VERSION ""

NS_ :

BS_:

BU_: TCM MRGB SGCP ECM MCPB MCPA EVCU2 AGSM

BO_ 271 ENGINE_HYBD_FD_1: 64 ECM
 SG_ Sum_FW_ID_Slw : 327|5@0+ (1,0) [0|30] "-"  EVCU2
 SG_ Sum_FW_ID_Fst : 367|5@0+ (1,0) [0|30] "-"  EVCU2
 SG_ MinPrdtdEngRunTorqCapV : 213|1@0+ (1,0) [0|0] "-"  EVCU2
 SG_ MinPrdtdEngRunTorqCap : 243|12@0+ (0.32,-300.16) [-300.16|1008] "Nm"  EVCU2
 SG_ MinImmedEngTorqCapV : 215|1@0+ (1,0) [0|0] "-"  EVCU2,TCM
 SG_ MinImmedEngTorqCap : 227|12@0+ (0.32,-300.16) [-300.16|1008] "Nm"  EVCU2,TCM
 SG_ MinEngTorqCapV : 196|1@0+ (1,0) [0|0] "-"  EVCU2
 SG_ MinEngTorqCap : 211|12@0+ (0.32,-300.16) [-300.16|1008] "Nm"  EVCU2
 SG_ MinAirFlowMinSparkTorqCapV : 197|1@0+ (1,0) [0|0] "-"  EVCU2,TCM
 SG_ MinAirFlowMinSparkTorqCap : 195|12@0+ (0.32,-300.16) [-300.16|1008] "Nm"  EVCU2,TCM
 SG_ MessageCounter_ENGINE_HYBD_FD_1 : 435|4@0+ (1,0) [0|15] "-"  EVCU2,TCM
 SG_ MaxPrdtdEngTorqCapV : 198|1@0+ (1,0) [0|0] "-"  EVCU2,TCM
 SG_ MaxPrdtdEngTorqCap : 179|12@0+ (0.32,-300.16) [-300.16|1008] "Nm"  EVCU2,TCM
 SG_ MaxOffEngTorqCap : 163|12@0+ (0.32,-300.16) [-300.16|1008] "Nm"  EVCU2
 SG_ HybActEngTorqRespTyp : 149|2@0+ (1,0) [0|0] "-"  EVCU2
 SG_ Feedback_HCP : 293|1@0+ (1,0) [0|0] "-"  EVCU2
 SG_ ETRQ_Mode : 362|3@0+ (1,0) [0|5] "-"  EVCU2
 SG_ EngTrqReserveReq : 351|8@0+ (0.32,0) [0|81.28] "Nm"  EVCU2
 SG_ EngRunCrnkAct : 295|1@0+ (1,0) [0|0] "-"  EVCU2
 SG_ EngAirFlwStdyStTorqV : 262|1@0+ (1,0) [0|0] "-"  EVCU2,TCM
 SG_ EngAirFlwStdyStTorq : 275|12@0+ (0.32,-300.16) [-300.16|1008] "Nm"  EVCU2,TCM
 SG_ EngActuatorsStat : 133|2@0+ (1,0) [0|0] "-"  EVCU2
 SG_ EngActStdyStTorqV : 263|1@0+ (1,0) [0|0] "-"  EVCU2
 SG_ EngActStdyStTorq : 259|12@0+ (0.32,-300.16) [-300.16|1008] "Nm"  EVCU2
 SG_ CRC_ENGINE_HYBD_FD_1 : 447|8@0+ (1,0) [0|255] "-"  EVCU2,TCM
 SG_ MAP_4_BAR_PHEV : 392|9@0+ (0.8,0) [0|408] "kPa"  EVCU2
 SG_ RedSpkAuthorityAvbl : 308|1@0+ (1,0) [0|1] "" EVCU2
 SG_ EngMinSparkNomCurrAirTorqCap : 82|11@0+ (1,-500) [-500|1547] "Nm"  EVCU2
 SG_ EngTrqFSO_CurrAir : 391|12@0+ (0.32,-300.16) [-300.16|1008] "Nm"  TCM
 SG_ GasFlwEnblsFuAtStr : 212|1@0+ (1,0) [0|1] "" EVCU2

BO_ 262 ENGINE_FD_2: 64 ECM
 SG_ TxAC_EMCC_rq_W : 189|1@0+ (1,0) [0|1] "-"  TCM
 SG_ TRANS_CLU_SLIP_MODE_W : 71|3@0+ (1,0) [0|7] "-"  TCM
 SG_ MessageCounter_ENGINE2 : 435|4@0+ (1,0) [0|15] "-"  EVCU2,TCM
 SG_ LV12PwrFreeRq_W : 176|1@0+ (1,0) [0|1] "-"  EVCU2,TCM
 SG_ KickDownRequest_W : 182|1@0+ (1,0) [0|1] "-"  TCM
 SG_ IntakeAirTemperature_W : 151|8@0+ (1,-40) [-40|214] "C"  TCM
 SG_ GasPedalPositionFailSts_W : 169|1@0+ (1,0) [0|1] "-"  TCM
 SG_ GasPedalPosition_W : 143|8@0+ (0.392,0) [0|99.568] "%"  TCM
 SG_ ESS_RqShftPark_W : 115|1@0+ (1,0) [0|0] "-"  Vector__XXX
 SG_ ESS_ENG_ST_W : 175|4@0+ (1,0) [0|15] "-"  TCM
 SG_ EngTrq_Enbl_Rq_TCM_W : 178|1@0+ (1,0) [0|1] "-"  EVCU2,TCM
 SG_ EngineSts_W : 87|2@0+ (1,0) [0|3] "-"  EVCU2,TCM
 SG_ EngineSpeedFailSts_W : 168|1@0+ (1,0) [0|1] "-"  SGCP,MCPB,MCPA
 SG_ EngineSpeed_W : 21|14@0+ (1,0) [0|16382] "1/min"  SGCP,EVCU2,MCPB,MCPA,TCM
 SG_ EngineIdleRefSpeed : 35|12@0+ (1,0) [0|4094] "1/min"  EVCU2,TCM
 SG_ EngineFrictionTorque_W : 112|9@0+ (1,0) [0|510] "Nm"  EVCU2
 SG_ ECM_LHOM_W : 188|1@0+ (1,0) [0|1] "-"  EVCU2,TCM
 SG_ ECM_LHOM_Trans_W : 117|2@0+ (1,0) [0|3] "-"  EVCU2,TCM
 SG_ CRC_ENGINE2 : 447|8@0+ (1,0) [0|255] "-"  EVCU2,TCM
 SG_ CrankHold_W : 179|1@0+ (1,0) [0|1] "-"  Vector__XXX
 SG_ ESS_EBOOST_BRKHLD_STATUS : 279|3@0+ (1,0) [0|6] "-"  Vector__XXX
 SG_ Engine_Stall_Detected : 197|1@0+ (1,0) [0|1] "-"  EVCU2
 SG_ EssEngStrtIsNotAllwdID : 68|3@0+ (1,0) [0|7] "" EVCU2
 SG_ EssEngStrtIsNotAllwd : 37|1@0+ (1,0) [0|1] "" EVCU2
 SG_ EssEngStopIsNotAllwdID : 59|4@0+ (1,0) [0|15] "" EVCU2
 SG_ EssEngStopIsNotAllwd : 255|1@0+ (1,0) [0|1] "" EVCU2
 SG_ EssEngSt : 202|3@0+ (1,0) [0|7] "" EVCU2
 SG_ EssEngModReq : 254|3@0+ (1,0) [0|7] "" EVCU2
 SG_ CompressionTest : 36|1@0+ (1,0) [0|1] "" EVCU2
 SG_ MinEngPowerReqForOilDil : 111|8@0+ (0.2,0) [0|51] "kw"  EVCU2
 SG_ MinEngPowerReqForOilDilEnabler : 96|1@0+ (1,0) [0|1] "" EVCU2
 SG_ Torque_Interface_Mask : 79|6@0+ (1,0) [0|63] "" TCM

BO_ 258 BRAKE_FD_2: 64 EVCU2
 SG_ MessageCounter_BRAKE2 : 435|4@0+ (1,0) [0|15] "-"  MCPB,MCPA
 SG_ LongAccelerationFailSts_BSM : 69|1@0+ (1,0) [0|1] "-"  MCPB,MCPA
 SG_ LongAcceleration_BSM : 35|12@0+ (0.02,-40.96) [-40.96|40.92] "m/s^2"  MCPB,MCPA
 SG_ LatAccelerationFailSts_BSM : 68|1@0+ (1,0) [0|1] "-"  MCPB,MCPA
 SG_ LatAcceleration_BSM : 19|12@0+ (0.02,-40.96) [-40.96|40.92] "m/s^2"  MCPB,MCPA
 SG_ ESCActive : 84|1@0+ (1,0) [0|1] "-"  MCPB,MCPA
 SG_ CRC_BRAKE2 : 447|8@0+ (1,0) [0|255] "-"  MCPB,MCPA
 SG_ ABSActive : 83|1@0+ (1,0) [0|1] "-"  MCPB,MCPA

BO_ 476 AGSM_FD_2: 32 AGSM
 SG_ ShiftLockFailSts : 91|1@0+ (1,0) [0|1] "-"  TCM
 SG_ PRNDFailSts : 82|1@0+ (1,0) [0|1] "-"  EVCU2,TCM
 SG_ PRNDdisplayFailSts : 83|1@0+ (1,0) [0|1] "-"  EVCU2,TCM
 SG_ MessageCounter_AGSM2 : 179|4@0+ (1,0) [0|15] "-"  EVCU2,TCM
 SG_ CRC_AGSM2 : 191|8@0+ (1,0) [0|255] "-"  EVCU2,TCM
 SG_ APCM_Stat : 107|2@0+ (1,0) [0|2] "-"  EVCU2
 SG_ ShiftLever_PositionFlt : 104|1@0+ (1,0) [0|1] "-"  TCM
 SG_ Low_Mode_Req : 5|1@0+ (1,0) [0|1] "-"  TCM
 SG_ ShiftLeverPositionReq : 95|4@0+ (1,0) [0|15] "-"  EVCU2,MCPB,TCM

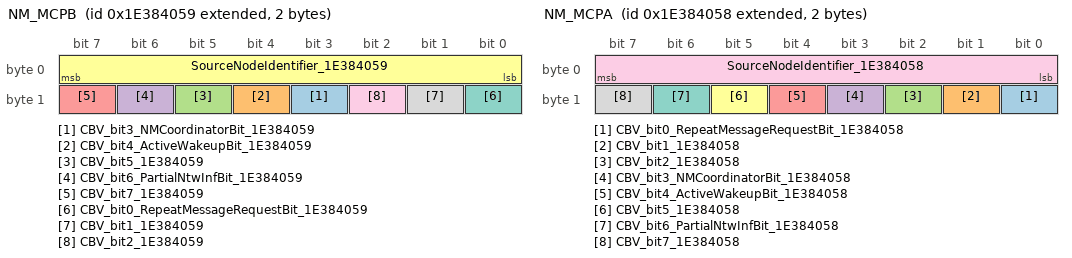
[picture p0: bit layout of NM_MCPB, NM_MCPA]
BO_ 2654486617 NM_MCPB: 2 MCPB
 SG_ CBV_bit3_NMCoordinatorBit_1E384059 : 11|1@0+ (1,0) [0|1] "" SGCP,EVCU2,MCPA,AGSM
 SG_ CBV_bit4_ActiveWakeupBit_1E384059 : 12|1@0+ (1,0) [0|1] "" SGCP,EVCU2,MCPA,AGSM
 SG_ CBV_bit5_1E384059 : 13|1@0+ (1,0) [0|1] "" SGCP,EVCU2,MCPA,AGSM
 SG_ CBV_bit6_PartialNtwInfBit_1E384059 : 14|1@0+ (1,0) [0|1] "" SGCP,EVCU2,MCPA,AGSM
 SG_ CBV_bit7_1E384059 : 15|1@0+ (1,0) [0|1] "" SGCP,EVCU2,MCPA,AGSM
 SG_ SourceNodeIdentifier_1E384059 : 7|8@0+ (1,0) [0|255] "-"  SGCP,EVCU2,MCPA,AGSM
 SG_ CBV_bit0_RepeatMessageRequestBit_1E384059 : 8|1@0+ (1,0) [0|1] "" SGCP,EVCU2,MCPA,AGSM
 SG_ CBV_bit1_1E384059 : 9|1@0+ (1,0) [0|1] "" SGCP,EVCU2,MCPA,AGSM
 SG_ CBV_bit2_1E384059 : 10|1@0+ (1,0) [0|1] "" SGCP,EVCU2,MCPA,AGSM

BO_ 2654486616 NM_MCPA: 2 MCPA
 SG_ CBV_bit0_RepeatMessageRequestBit_1E384058 : 8|1@0+ (1,0) [0|1] "" SGCP,EVCU2,MCPB,AGSM
 SG_ CBV_bit1_1E384058 : 9|1@0+ (1,0) [0|1] "" SGCP,EVCU2,MCPB,AGSM
 SG_ CBV_bit2_1E384058 : 10|1@0+ (1,0) [0|1] "" SGCP,EVCU2,MCPB,AGSM
 SG_ CBV_bit3_NMCoordinatorBit_1E384058 : 11|1@0+ (1,0) [0|1] "" SGCP,EVCU2,MCPB,AGSM
 SG_ CBV_bit4_ActiveWakeupBit_1E384058 : 12|1@0+ (1,0) [0|1] "" SGCP,EVCU2,MCPB,AGSM
 SG_ CBV_bit5_1E384058 : 13|1@0+ (1,0) [0|1] "" SGCP,EVCU2,MCPB,AGSM
 SG_ CBV_bit6_PartialNtwInfBit_1E384058 : 14|1@0+ (1,0) [0|1] "" SGCP,EVCU2,MCPB,AGSM
 SG_ CBV_bit7_1E384058 : 15|1@0+ (1,0) [0|1] "" SGCP,EVCU2,MCPB,AGSM
 SG_ SourceNodeIdentifier_1E384058 : 7|8@0+ (1,0) [0|255] "-"  SGCP,EVCU2,MCPB,AGSM

BO_ 2564682261 DIAGNOSTIC_ROE_FD_MCPB: 64 MCPB
 SG_ N_PDU_18DDF215 : 7|64@0+ (1,0) [0|0] "" EVCU2

BO_ 2564682260 DIAGNOSTIC_ROE_FD_MCPA: 64 MCPA
 SG_ N_PDU_18DDF214 : 7|64@0+ (1,0) [0|0] "" EVCU2

BO_ 2564485396 DIAGNOSTIC_RESPONSE_MCPA: 8 MCPA
 SG_ N_PDU_18DAF114 : 7|64@0+ (1,0) [0|0] "" EVCU2

BO_ 2564485653 DIAGNOSTIC_RESPONSE_FD_MCPB: 64 MCPB
 SG_ N_PDU_18DAF215 : 7|64@0+ (1,0) [0|0] "" EVCU2

BO_ 2564485652 DIAGNOSTIC_RESPONSE_FD_MCPA: 64 MCPA
 SG_ N_PDU_18DAF214 : 7|64@0+ (1,0) [0|0] "" EVCU2

BO_ 2564429297 DIAGNOSTIC_REQUEST_MCPB: 8 EVCU2
 SG_ N_PDU_18DA15F1 : 7|64@0+ (1,0) [0|0] "" MCPB

BO_ 2564429298 DIAGNOSTIC_REQUEST_FD_MCPB: 64 EVCU2
 SG_ N_PDU_18DA15F2 : 7|64@0+ (1,0) [0|0] "" MCPB

BO_ 2564429042 DIAGNOSTIC_REQUEST_FD_MCPA: 64 EVCU2
 SG_ N_PDU_18DA14F2 : 7|64@0+ (1,0) [0|0] "" MCPA

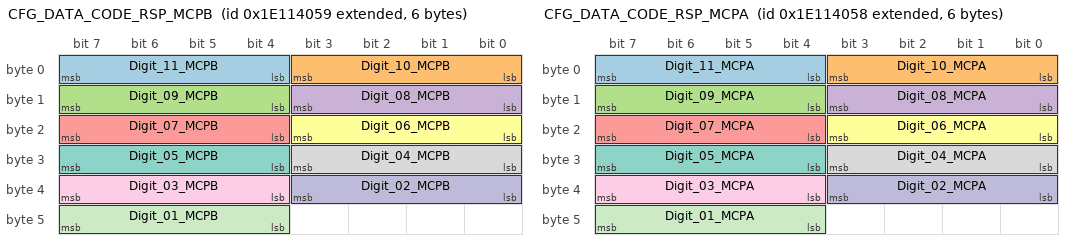
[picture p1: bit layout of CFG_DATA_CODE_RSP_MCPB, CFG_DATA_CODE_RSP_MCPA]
BO_ 2651930713 CFG_DATA_CODE_RSP_MCPB: 6 MCPB
 SG_ Digit_11_MCPB : 7|4@0+ (1,0) [0|15] "-"  EVCU2
 SG_ Digit_10_MCPB : 3|4@0+ (1,0) [0|15] "-"  EVCU2
 SG_ Digit_09_MCPB : 15|4@0+ (1,0) [0|15] "-"  EVCU2
 SG_ Digit_08_MCPB : 11|4@0+ (1,0) [0|15] "-"  EVCU2
 SG_ Digit_07_MCPB : 23|4@0+ (1,0) [0|15] "-"  EVCU2
 SG_ Digit_06_MCPB : 19|4@0+ (1,0) [0|15] "-"  EVCU2
 SG_ Digit_05_MCPB : 31|4@0+ (1,0) [0|15] "-"  EVCU2
 SG_ Digit_04_MCPB : 27|4@0+ (1,0) [0|15] "-"  EVCU2
 SG_ Digit_03_MCPB : 39|4@0+ (1,0) [0|15] "-"  EVCU2
 SG_ Digit_02_MCPB : 35|4@0+ (1,0) [0|15] "-"  EVCU2
 SG_ Digit_01_MCPB : 47|4@0+ (1,0) [0|15] "-"  EVCU2

BO_ 2651930712 CFG_DATA_CODE_RSP_MCPA: 6 MCPA
 SG_ Digit_11_MCPA : 7|4@0+ (1,0) [0|15] "-"  EVCU2
 SG_ Digit_10_MCPA : 3|4@0+ (1,0) [0|15] "-"  EVCU2
 SG_ Digit_09_MCPA : 15|4@0+ (1,0) [0|15] "-"  EVCU2
 SG_ Digit_08_MCPA : 11|4@0+ (1,0) [0|15] "-"  EVCU2
 SG_ Digit_07_MCPA : 23|4@0+ (1,0) [0|15] "-"  EVCU2
 SG_ Digit_06_MCPA : 19|4@0+ (1,0) [0|15] "-"  EVCU2
 SG_ Digit_05_MCPA : 31|4@0+ (1,0) [0|15] "-"  EVCU2
 SG_ Digit_04_MCPA : 27|4@0+ (1,0) [0|15] "-"  EVCU2
 SG_ Digit_03_MCPA : 39|4@0+ (1,0) [0|15] "-"  EVCU2
 SG_ Digit_02_MCPA : 35|4@0+ (1,0) [0|15] "-"  EVCU2
 SG_ Digit_01_MCPA : 47|4@0+ (1,0) [0|15] "-"  EVCU2

BO_ 496 PARK_DATA: 24 MCPB
 SG_ MessageCounter_PARK_DATA : 115|4@0+ (1,0) [0|15] "" EVCU2
 SG_ CRC_PARK_DATA : 127|8@0+ (1,0) [0|255] "" EVCU2
 SG_ Plock_fdbk_sts : 7|3@0+ (1,0) [0|7] "" Vector__XXX

BO_ 105 VDCM_PWT3: 64 EVCU2
 SG_ T7_Sensor_Temp : 330|11@0+ (0.1,-40) [-40|164.7] "°C"  SGCP,MCPB,MCPA
 SG_ T7_CoolantTempVldty : 331|1@0+ (1,0) [0|1] "" SGCP,MCPB,MCPA
 SG_ T4_Sensor_Temp : 378|11@0+ (0.1,-40) [-40|164.7] "°C"  SGCP,MCPB,MCPA

BO_ 2654339273 PDC_INFO_FD_SGCP: 32 SGCP
 SG_ GenericFailSts_FD16_SGCP : 180|1@0+ (1,0) [0|1] "" EVCU2
 SG_ EOL_FD16_SGCP : 2|1@0+ (1,0) [0|1] "-"  EVCU2
 SG_ CurrentFailSts_FD16_SGCP : 181|1@0+ (1,0) [0|1] "" EVCU2

BO_ 2654339161 PDC_INFO_FD_MCPB: 32 MCPB
 SG_ EOL_FD16_MCPB : 2|1@0+ (1,0) [0|1] "-"  EVCU2
 SG_ GenericFailSts_FD16_MCPB : 172|1@0+ (1,0) [0|1] "" EVCU2
 SG_ CurrentFailSts_FD16_MCPB : 173|1@0+ (1,0) [0|1] "" EVCU2

BO_ 2654339160 PDC_INFO_FD_MCPA: 32 MCPA
 SG_ EOL_FD16_MCPA : 2|1@0+ (1,0) [0|1] "-"  EVCU2
 SG_ GenericFailSts_FD16_MCPA : 172|1@0+ (1,0) [0|1] "" EVCU2
 SG_ CurrentFailSts_FD16_MCPA : 173|1@0+ (1,0) [0|1] "" EVCU2

BO_ 2564682364 DIAGNOSTIC_ROE_FD_SGCP: 64 SGCP
 SG_ N_PDU_18DDF27C : 7|64@0+ (1,0) [0|0] "" EVCU2

BO_ 2564485756 DIAGNOSTIC_RESPONSE_FD_SGCP: 64 SGCP
 SG_ N_PDU_18DAF27C : 7|64@0+ (1,0) [0|0] "" EVCU2

BO_ 2564455666 DIAGNOSTIC_REQUEST_FD_SGCP: 64 EVCU2
 SG_ N_PDU_18DA7CF2 : 7|64@0+ (1,0) [0|0] "" SGCP

BO_ 263 PT_SYSTEM_FD_1: 64 EVCU2
 SG_ OptimdStrtReqdActr : 2|3@0+ (1,0) [0|7] "" ECM
 SG_ OptimdEngStrtStpType : 7|5@0+ (1,0) [0|31] "" ECM
 SG_ OptimdEngOnOffCmd : 15|1@0+ (1,0) [0|1] "" ECM
 SG_ Hyb_ProducingTorque : 13|1@0+ (1,0) [0|1] "" ECM
 SG_ HCPFuelDisable : 14|1@0+ (1,0) [0|1] "" ECM
 SG_ PowertrainPrplsnActv_PT : 146|1@0+ (1,0) [0|1] "" SGCP,MCPB,MCPA
 SG_ GearEngagedForDisplay_PT : 12|5@0+ (1,0) [0|31] "" AGSM
 SG_ GearEngaged_PT : 132|4@0+ (1,0) [0|15] "" MCPB
 SG_ TransmissionFailSts_PT : 152|1@0+ (1,0) [0|1] "" AGSM
 SG_ TerrainModeStat_PT : 119|5@0+ (1,0) [0|31] "" Vector__XXX
 SG_ ShiftLeverPosition_PT : 51|4@0+ (1,0) [0|15] "" AGSM
 SG_ ShiftLeverLockReq_PT : 155|1@0+ (1,0) [0|1] "" AGSM
 SG_ R_SHFT_LOCK_PT : 154|1@0+ (1,0) [0|1] "" AGSM
 SG_ MessageCounter_PT_SYSTEM_FD_1 : 435|4@0+ (1,0) [0|15] "-"  MCPB,AGSM,ECM
 SG_ GearIndicationSts_PT : 153|1@0+ (1,0) [0|1] "" AGSM
 SG_ GasPedalPositionFailSts_PT : 145|1@0+ (1,0) [0|1] "" ECM
 SG_ GasPedalPosition_PT : 31|8@0+ (0.392,0) [0|99.96] "%"  ECM
 SG_ CRC_PT_SYSTEM_FD_1 : 447|8@0+ (1,0) [0|255] "-"  MCPB,AGSM,ECM
 SG_ APCM_Rq_PT : 137|2@0+ (1,0) [0|3] "" AGSM
 SG_ PropulsionSystemActive_PT : 209|1@0+ (1,0) [0|1] "-"  MRGB
 SG_ Custom_DrvMdSts_PT : 327|5@0+ (1,0) [0|31] "" Vector__XXX
 SG_ WheelSpeedRearRight : 348|13@0+ (0.0625,0) [0|511.9375] "Km/h"  MRGB
 SG_ WheelSpeedRearLeft : 364|13@0+ (0.0625,0) [0|511.9375] "Km/h"  MRGB
 SG_ Transm_Torq_Feedback : 279|1@0+ (1,0) [0|1] "" MRGB
 SG_ Inertia_Torque_Active : 415|1@0+ (1,0) [0|1] "" MRGB
 SG_ Gear_Rq : 351|3@0+ (1,0) [0|7] "" MRGB
 SG_ EM_min_Trqdyn_P : 393|10@0+ (1,-1021) [-1021|2] "Nm"  MRGB
 SG_ EM_max_Trqdyn_P : 391|10@0+ (1,-1021) [-1021|2] "Nm"  MRGB
 SG_ EOPB_Min_Oil_FlwRate_Rq : 431|8@0+ (0.1,0) [0|25.5] "lpm"  MRGB

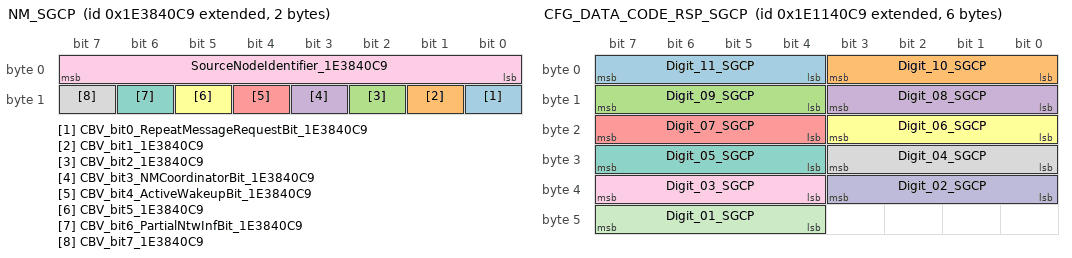
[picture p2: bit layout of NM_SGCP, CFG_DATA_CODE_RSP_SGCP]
BO_ 2654486729 NM_SGCP: 2 SGCP
 SG_ CBV_bit0_RepeatMessageRequestBit_1E3840C9 : 8|1@0+ (1,0) [0|1] "" EVCU2,MCPB,MCPA
 SG_ CBV_bit1_1E3840C9 : 9|1@0+ (1,0) [0|1] "" EVCU2,MCPB,MCPA
 SG_ CBV_bit2_1E3840C9 : 10|1@0+ (1,0) [0|1] "" EVCU2,MCPB,MCPA
 SG_ CBV_bit3_NMCoordinatorBit_1E3840C9 : 11|1@0+ (1,0) [0|1] "" EVCU2,MCPB,MCPA
 SG_ CBV_bit4_ActiveWakeupBit_1E3840C9 : 12|1@0+ (1,0) [0|1] "" EVCU2,MCPB,MCPA
 SG_ CBV_bit5_1E3840C9 : 13|1@0+ (1,0) [0|1] "" EVCU2,MCPB,MCPA
 SG_ CBV_bit6_PartialNtwInfBit_1E3840C9 : 14|1@0+ (1,0) [0|1] "" EVCU2,MCPB,MCPA
 SG_ CBV_bit7_1E3840C9 : 15|1@0+ (1,0) [0|1] "" EVCU2,MCPB,MCPA
 SG_ SourceNodeIdentifier_1E3840C9 : 7|8@0+ (1,0) [0|255] "-"  EVCU2,MCPB,MCPA

BO_ 2651930825 CFG_DATA_CODE_RSP_SGCP: 6 SGCP
 SG_ Digit_11_SGCP : 7|4@0+ (1,0) [0|15] "-"  EVCU2
 SG_ Digit_10_SGCP : 3|4@0+ (1,0) [0|15] "-"  EVCU2
 SG_ Digit_09_SGCP : 15|4@0+ (1,0) [0|15] "-"  EVCU2
 SG_ Digit_08_SGCP : 11|4@0+ (1,0) [0|15] "-"  EVCU2
 SG_ Digit_07_SGCP : 23|4@0+ (1,0) [0|15] "-"  EVCU2
 SG_ Digit_06_SGCP : 19|4@0+ (1,0) [0|15] "-"  EVCU2
 SG_ Digit_05_SGCP : 31|4@0+ (1,0) [0|15] "-"  EVCU2
 SG_ Digit_04_SGCP : 27|4@0+ (1,0) [0|15] "-"  EVCU2
 SG_ Digit_03_SGCP : 39|4@0+ (1,0) [0|15] "-"  EVCU2
 SG_ Digit_02_SGCP : 35|4@0+ (1,0) [0|15] "-"  EVCU2
 SG_ Digit_01_SGCP : 47|4@0+ (1,0) [0|15] "-"  EVCU2

BO_ 216 PT_ENERGY_FD_1: 64 EVCU2
 SG_ BatteryVoltage_Raw_PT : 97|10@0+ (0.2,0) [0|204.60] "V"  MCPB,MCPA

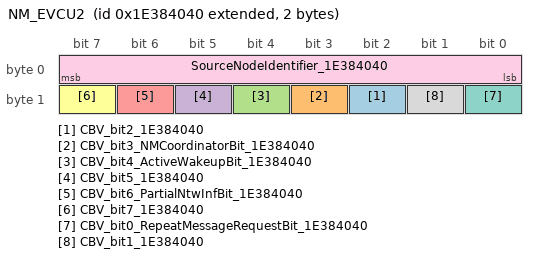
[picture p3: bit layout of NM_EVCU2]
BO_ 2654486592 NM_EVCU2: 2 EVCU2
 SG_ CBV_bit2_1E384040 : 10|1@0+ (1,0) [0|1] "" SGCP,MCPB,MCPA,AGSM
 SG_ CBV_bit3_NMCoordinatorBit_1E384040 : 11|1@0+ (1,0) [0|1] "" SGCP,MCPB,MCPA,AGSM
 SG_ CBV_bit4_ActiveWakeupBit_1E384040 : 12|1@0+ (1,0) [0|1] "" SGCP,MCPB,MCPA,AGSM
 SG_ CBV_bit5_1E384040 : 13|1@0+ (1,0) [0|1] "" SGCP,MCPB,MCPA,AGSM
 SG_ CBV_bit6_PartialNtwInfBit_1E384040 : 14|1@0+ (1,0) [0|1] "" SGCP,MCPB,MCPA,AGSM
 SG_ CBV_bit7_1E384040 : 15|1@0+ (1,0) [0|1] "" SGCP,MCPB,MCPA,AGSM
 SG_ CBV_bit0_RepeatMessageRequestBit_1E384040 : 8|1@0+ (1,0) [0|1] "" SGCP,MCPB,MCPA,AGSM
 SG_ CBV_bit1_1E384040 : 9|1@0+ (1,0) [0|1] "" SGCP,MCPB,MCPA,AGSM
 SG_ SourceNodeIdentifier_1E384040 : 7|8@0+ (1,0) [0|255] "-"  SGCP,MCPB,MCPA,AGSM

BO_ 1811 REAL_TIME_CLOCK: 64 EVCU2
 SG_ Real_Time_Validity : 39|1@0+ (1,0) [0|1] "" SGCP,MCPB,MCPA
 SG_ Real_Time_Clock : 7|32@0+ (1,0) [0|4294967295] "" SGCP,MCPB,MCPA

BO_ 1070 SGCP_OBD_DTC: 32 SGCP
 SG_ SGCP_DTC_Stat2 : 26|3@0+ (1,0) [0|7] "" EVCU2
 SG_ SGCP_DTC_Stat1 : 18|3@0+ (1,0) [0|7] "" EVCU2
 SG_ SGCP_DTC_Idx2 : 31|5@0+ (1,0) [0|31] "" EVCU2
 SG_ SGCP_DTC_Idx1 : 23|5@0+ (1,0) [0|31] "" EVCU2
 SG_ SGCP_CalChar : 15|8@0+ (1,0) [0|255] "" EVCU2
 SG_ SGCP_Cal_ID_Idx : 7|6@0+ (1,0) [0|63] "" EVCU2
 SG_ MessageCounter_SGCP_OBD_DTC : 179|4@0+ (1,0) [0|15] ""  EVCU2
 SG_ CRC_SGCP_OBD_DTC : 191|8@0+ (1,0) [0|255] ""  EVCU2

BO_ 1065 MCPB_OBD_DTC: 32 MCPB
 SG_ MessageCounter_MCPB_OBD_DTC : 179|4@0+ (1,0) [0|15] ""  EVCU2
 SG_ MCPB_DTC_Stat2 : 26|3@0+ (1,0) [0|7] "" EVCU2
 SG_ MCPB_DTC_Stat1 : 18|3@0+ (1,0) [0|7] "" EVCU2
 SG_ MCPB_DTC_Idx2 : 31|5@0+ (1,0) [0|31] "" EVCU2
 SG_ MCPB_DTC_Idx1 : 23|5@0+ (1,0) [0|31] "" EVCU2
 SG_ MCPB_CalChar : 15|8@0+ (1,0) [0|255] "" EVCU2
 SG_ MCPB_Cal_ID_Idx : 7|6@0+ (1,0) [0|63] "" EVCU2
 SG_ CRC_MCPB_OBD_DTC : 191|8@0+ (1,0) [0|255] ""  EVCU2

BO_ 1057 MCPA_OBD_DTC: 32 MCPA
 SG_ MessageCounter_MCPA_OBD_DTC : 179|4@0+ (1,0) [0|15] ""  EVCU2
 SG_ MCPA_DTC_Stat2 : 26|3@0+ (1,0) [0|7] "" EVCU2
 SG_ MCPA_DTC_Stat1 : 18|3@0+ (1,0) [0|7] "" EVCU2
 SG_ MCPA_DTC_Idx2 : 31|5@0+ (1,0) [0|31] "" EVCU2
 SG_ MCPA_DTC_Idx1 : 23|5@0+ (1,0) [0|31] "" EVCU2
 SG_ MCPA_CalChar : 15|8@0+ (1,0) [0|255] "" EVCU2
 SG_ MCPA_Cal_ID_Idx : 7|6@0+ (1,0) [0|63] "" EVCU2
 SG_ CRC_MCPA_OBD_DTC : 191|8@0+ (1,0) [0|255] ""  EVCU2

BO_ 286 VEHDYN_FD_1: 64 EVCU2
 SG_ RELSD_TgtTrq : 136|9@0+ (10,0) [0|5110] "Nm"  MRGB

CM_ SG_ 476 ShiftLockFailSts "-";
CM_ SG_ 476 PRNDFailSts "-";
CM_ SG_ 476 PRNDdisplayFailSts "-";
CM_ SG_ 476 MessageCounter_AGSM2 "This signal is a counter used for safety checks strategies. This counter is incremented of 1 (one) unit at each frame transmission.";
CM_ SG_ 476 CRC_AGSM2 "CRC according to SAE J1850 standard at each frame transmission.";
CM_ SG_ 271 Sum_FW_ID_Slw "Enumeration of system controlling combustion slow path";
CM_ SG_ 271 Sum_FW_ID_Fst "Enumeration of system controlling combustion fast path";
CM_ SG_ 271 MinPrdtdEngRunTorqCapV "Minimum predicted engine run torque capacity validity; Invalid = [1]";
CM_ SG_ 271 MinPrdtdEngRunTorqCap "Minimum predicted engine run torque capacity (minimum air flow, MBT spark)";
CM_ SG_ 271 MinImmedEngTorqCapV "Minimum immediate engine torque capacity validity; Invalid = [1]";
CM_ SG_ 271 MinImmedEngTorqCap "Minimum immediate engine torque capacity (current air flow, minimum spark)";
CM_ SG_ 271 MinEngTorqCapV "Minimum engine torque capacity validity; Invalid = [1]";
CM_ SG_ 271 MinEngTorqCap "Minimum engine torque capacity (min air flow, fuel off)";
CM_ SG_ 271 MinAirFlowMinSparkTorqCapV "Engine Torque capacity at minimum air flow and  minimum spark validity; Invalid = [1]";
CM_ SG_ 271 MinAirFlowMinSparkTorqCap "Engine Torque capacity at minimum air flow and  minimum spark";
CM_ SG_ 271 MessageCounter_ENGINE_HYBD_FD_1 "This signal is a counter used for safety checks strategies. This counter is incremented of 1 (one) unit at each frame transmission.";
CM_ SG_ 271 MaxPrdtdEngTorqCapV "Maximum predicted engine torque capacity validity; Invalid = [1]";
CM_ SG_ 271 MaxPrdtdEngTorqCap "Maximum predicted engine torque capacity";
CM_ SG_ 271 MaxOffEngTorqCap "Capacity Max-off";
CM_ SG_ 271 HybActEngTorqRespTyp "Hybrid Actual Engine Torque Response Type";
CM_ SG_ 271 Feedback_HCP "Indication that the ECM is receiving valid data from the HCP. 0 - False; 1 - True.";
CM_ SG_ 271 ETRQ_Mode "Enumeration of combustion torque mode";
CM_ SG_ 271 EngTrqReserveReq "Engine Torque Reserve Request";
CM_ SG_ 271 EngRunCrnkAct "ECM run crank terminal status, 1=active";
CM_ SG_ 271 EngAirFlwStdyStTorqV "Engine airflow steady state torque validity; Invalid = [1]";
CM_ SG_ 271 EngAirFlwStdyStTorq "Engine airflow steady state torque (potential)";
CM_ SG_ 271 EngActuatorsStat "Engine Actuator Status for Autostop";
CM_ SG_ 271 EngActStdyStTorqV "Engine actual steady state torque validity; Invalid = [1]";
CM_ SG_ 271 EngActStdyStTorq "Engine actual steady state torque (current conditions)";
CM_ SG_ 271 CRC_ENGINE_HYBD_FD_1 "CRC according to SAE J1850 standard at each frame transmission.";
CM_ SG_ 262 TxAC_EMCC_rq_W "-";
CM_ SG_ 262 TRANS_CLU_SLIP_MODE_W "-";
CM_ SG_ 262 MessageCounter_ENGINE2 "This signal is a counter used for safety checks strategies. This counter is incremented of 1 (one) unit at each frame transmission.";
CM_ SG_ 262 LV12PwrFreeRq_W "-";
CM_ SG_ 262 KickDownRequest_W "It is set to KD_requested whenever the Kick-Down condition is detected by the ECM.";
CM_ SG_ 262 GasPedalPositionFailSts_W "-";
CM_ SG_ 262 GasPedalPosition_W "-";
CM_ SG_ 262 ESS_RqShftPark_W "ESS Request shift to Park.  1 = True, 0 = False";
CM_ SG_ 262 ESS_ENG_ST_W "ESS Engine State";
CM_ SG_ 262 EngTrq_Enbl_Rq_TCM_W "Allow TRANS torque request";
CM_ SG_ 262 EngineSts_W "-";
CM_ SG_ 262 EngineSpeedFailSts_W "Used to indicate if a Fail is present for the engine speed";
CM_ SG_ 262 EngineSpeed_W "It gives information on C-CAN network about  engine speed";
CM_ SG_ 262 EngineIdleRefSpeed "This signal represents target of engine speed for the idle control function, at the end of dynamic transient conditions. It takes into account changes of idle speed due to temperature and auxiliary loads. It is updated even when the engine is ou(...)";
CM_ SG_ 262 EngineFrictionTorque_W "-";
CM_ SG_ 262 ECM_LHOM_W "-";
CM_ SG_ 262 ECM_LHOM_Trans_W "Indicates to the transmission the Limp Home Status of ECM and Torque Accuracy";
CM_ SG_ 262 CRC_ENGINE2 "CRC according to SAE J1850 standard at each frame transmission.";
CM_ SG_ 262 CrankHold_W "Used by ECM to command an action to the BCM cranking relay during cranking phase";
CM_ SG_ 258 MessageCounter_BRAKE2 "This signal is a counter used for safety checks strategies. This counter is incremented of 1 (one) unit at each frame transmission.";
CM_ SG_ 258 LongAccelerationFailSts_BSM "This signal indicates the status of Longitudinal acceleration signal";
CM_ SG_ 258 LongAcceleration_BSM "This signal indicates the Longitudinal Acceleration Value";
CM_ SG_ 258 LatAccelerationFailSts_BSM "This signal indicates the status of Lateral Acceleration Signal";
CM_ SG_ 258 LatAcceleration_BSM "This signal indicates the Lateral Acceleration Value";
CM_ SG_ 258 ESCActive "This signal is set to Active when the brake intervention by ESC is active.";
CM_ SG_ 258 CRC_BRAKE2 "CRC according to SAE J1850 standard at each frame transmission.";
CM_ SG_ 258 ABSActive "This signal is set to Active when the ABS functionality is active.";
CM_ SG_ 476 APCM_Stat "Auto position correction mode status";
CM_ SG_ 262 ESS_EBOOST_BRKHLD_STATUS "ESS brake hold release status";
CM_ SG_ 262 Engine_Stall_Detected "Engine stall detected flag";
CM_ SG_ 496 MessageCounter_PARK_DATA "This signal is a counter used for safety checks strategies. This counter is incremented of 1 (one) unit at each frame transmission.";
CM_ SG_ 496 CRC_PARK_DATA "CRC according to SAE J1850 standard at each frame transmission.";
CM_ SG_ 105 T7_Sensor_Temp "T7 Temperature sensor";
CM_ SG_ 105 T7_CoolantTempVldty "Inlet inverter temperature validity";
CM_ SG_ 105 T4_Sensor_Temp "T4 Temperature sensor";
CM_ SG_ 271 MAP_4_BAR_PHEV "Engine manifold pressure (4 bar range) 10ms cyclic";
CM_ SG_ 2564485396 N_PDU_18DAF114 "This signal is used for diagnostic purposes";
CM_ SG_ 2654486617 CBV_bit3_NMCoordinatorBit_1E384059 "NM Coordinator Sleep Bit";
CM_ SG_ 2654486617 CBV_bit4_ActiveWakeupBit_1E384059 "Active Wakeup Bit";
CM_ SG_ 2654486617 CBV_bit6_PartialNtwInfBit_1E384059 "Partial Network Information Bit (PNI)";
CM_ SG_ 2654486617 SourceNodeIdentifier_1E384059 "Source Node Identifier";
CM_ SG_ 2654486617 CBV_bit0_RepeatMessageRequestBit_1E384059 "Repeat Message Request Bit";
CM_ SG_ 2654486616 CBV_bit0_RepeatMessageRequestBit_1E384058 "Repeat Message Request Bit";
CM_ SG_ 2654486616 CBV_bit3_NMCoordinatorBit_1E384058 "NM Coordinator Sleep Bit";
CM_ SG_ 2654486616 CBV_bit4_ActiveWakeupBit_1E384058 "Active Wakeup Bit";
CM_ SG_ 2654486616 CBV_bit6_PartialNtwInfBit_1E384058 "Partial Network Information Bit (PNI)";
CM_ SG_ 2654486616 SourceNodeIdentifier_1E384058 "Source Node Identifier";
CM_ SG_ 2564682261 N_PDU_18DDF215 "This signal is used for diagnostic purposes";
CM_ SG_ 2564682260 N_PDU_18DDF214 "This signal is used for diagnostic purposes";
CM_ SG_ 2564485653 N_PDU_18DAF215 "This signal is used for diagnostic purposes";
CM_ SG_ 2564485652 N_PDU_18DAF214 "This signal is used for diagnostic purposes";
CM_ SG_ 2564429297 N_PDU_18DA15F1 "This signal is used for diagnostic purposes";
CM_ SG_ 2564429298 N_PDU_18DA15F2 "This signal is used for diagnostic purposes";
CM_ SG_ 2564429042 N_PDU_18DA14F2 "This signal is used for diagnostic purposes";
CM_ SG_ 476 ShiftLever_PositionFlt "Shifter Position Failure";
CM_ SG_ 2654339273 GenericFailSts_FD16_SGCP "Indicates the presence/absent of at least one DTC in the System Memory";
CM_ SG_ 2654339273 EOL_FD16_SGCP "Indicates if the ECU requires configuration data at the assembly plant End Of Line";
CM_ SG_ 2654339273 CurrentFailSts_FD16_SGCP "Indicates the presence/absence of at least one DTC with DTCStatus = present in the System Memory";
CM_ SG_ 2654339161 EOL_FD16_MCPB "Indicates if the ECU requires configuration data at the assembly plant End Of Line";
CM_ SG_ 2654339160 EOL_FD16_MCPA "Indicates if the ECU requires configuration data at the assembly plant End Of Line";
CM_ SG_ 263 OptimdStrtReqdActr "Signal to determine which actuator will be used to spin/crank the engine";
CM_ SG_ 263 OptimdEngStrtStpType "This signal indicates the type of engine start";
CM_ SG_ 263 OptimdEngOnOffCmd "Signal to give the final command on if the engine should be On or Off";
CM_ SG_ 263 Hyb_ProducingTorque "This signal indicates that hybrid control unit is declaring enging producing torque";
CM_ SG_ 263 HCPFuelDisable "Signal to disable fueling for engine ramp or ramp down purposes";
CM_ SG_ 262 EssEngStrtIsNotAllwdID "This is an enumerated interface that reports the reason why a Start is not allowed by the ECM";
CM_ SG_ 262 EssEngStrtIsNotAllwd "This is a flag that signifies if a start is allowed by the ECM";
CM_ SG_ 262 EssEngStopIsNotAllwdID "This is an enumerated interface that reports the reason why a Stop is not allowed by the ECM";
CM_ SG_ 262 EssEngStopIsNotAllwd "This is a flag that signifies if a stop is allowed by the ECM";
CM_ SG_ 262 EssEngSt "Signal that gives feedback on the current engine state";
CM_ SG_ 262 EssEngModReq "Command signal from EssEveMgr that directs the engine actuators for turning On or Off the engine";
CM_ SG_ 262 CompressionTest "This signal requests a compression test";
CM_ SG_ 263 PowertrainPrplsnActv_PT "Powertrain Propulsion System Status";
CM_ SG_ 263 GearEngagedForDisplay_PT "Transmission Gear Engaged signal for the instrument cluster display";
CM_ SG_ 263 GearEngaged_PT "Current engaged gear";
CM_ SG_ 216 BatteryVoltage_Raw_PT "Battery Voltage value measured from the electrified powertrain control module pin";
CM_ SG_ 2654339161 GenericFailSts_FD16_MCPB "Indicates the presence/absent of at least one DTC in the System Memory";
CM_ SG_ 2654339161 CurrentFailSts_FD16_MCPB "Indicates the presence/absence of at least one DTC with DTCStatus = present in the System Memory";
CM_ SG_ 2654339160 GenericFailSts_FD16_MCPA "Indicates the presence/absent of at least one DTC in the System Memory";
CM_ SG_ 2654339160 CurrentFailSts_FD16_MCPA "Indicates the presence/absence of at least one DTC with DTCStatus = present in the System Memory";
CM_ SG_ 496 Plock_fdbk_sts "Park lock status";
CM_ SG_ 271 RedSpkAuthorityAvbl "Reduced Spark Availability Warning";
CM_ SG_ 271 EngMinSparkNomCurrAirTorqCap "Engine Torque capacity at current airflow  min and  nominal spark advance.";
CM_ SG_ 263 TransmissionFailSts_PT "Transmission Failure Status";
CM_ SG_ 263 TerrainModeStat_PT "Terrain Mode";
CM_ SG_ 263 ShiftLeverPosition_PT "Shift Lever Position";
CM_ SG_ 263 ShiftLeverLockReq_PT "Shift Lever Lock Request";
CM_ SG_ 263 R_SHFT_LOCK_PT "Shift lock for reverse";
CM_ SG_ 263 MessageCounter_PT_SYSTEM_FD_1 "This signal is a counter used for safety checks strategies. This counter is incremented of 1 (one) unit at each frame transmission.";
CM_ SG_ 263 GearIndicationSts_PT "Gear Indication Status";
CM_ SG_ 263 GasPedalPositionFailSts_PT "Gas Pedal Position Failure Status";
CM_ SG_ 263 GasPedalPosition_PT "Gas Pedal Position in percentage";
CM_ SG_ 263 CRC_PT_SYSTEM_FD_1 "CRC according to SAE J1850 standard at each frame transmission.";
CM_ SG_ 263 APCM_Rq_PT "Auto position correction mode request";
CM_ SG_ 271 EngTrqFSO_CurrAir "Engine torque at current air at with all cylinders in fuel shut off";
CM_ SG_ 2564682364 N_PDU_18DDF27C "This signal is used for diagnostic purposes";
CM_ SG_ 2564485756 N_PDU_18DAF27C "This signal is used for diagnostic purposes";
CM_ SG_ 2564455666 N_PDU_18DA7CF2 "This signal is used for diagnostic purposes";
CM_ SG_ 2654486729 CBV_bit0_RepeatMessageRequestBit_1E3840C9 "Repeat Message Request Bit";
CM_ SG_ 2654486729 CBV_bit3_NMCoordinatorBit_1E3840C9 "NM Coordinator Sleep Bit";
CM_ SG_ 2654486729 CBV_bit4_ActiveWakeupBit_1E3840C9 "Active Wakeup Bit";
CM_ SG_ 2654486729 CBV_bit6_PartialNtwInfBit_1E3840C9 "Partial Network Information Bit (PNI)";
CM_ SG_ 2654486729 SourceNodeIdentifier_1E3840C9 "Source Node Identifier";
CM_ SG_ 1811 Real_Time_Validity "EVCU Real Time Clock Validity";
CM_ SG_ 1811 Real_Time_Clock "EVCU Real Time Clock";
CM_ SG_ 476 Low_Mode_Req "Signal Indicating L Button Pressed Status";
CM_ SG_ 476 ShiftLeverPositionReq "This signal describes the shift lever position requested by the driver.";
CM_ SG_ 1070 SGCP_DTC_Stat2 "SGCP diagnostic trouble code status 1";
CM_ SG_ 1070 SGCP_DTC_Stat1 "SGCP diagnostic trouble code status 1";
CM_ SG_ 1070 SGCP_DTC_Idx2 "SGCP diagnostic trouble code index 2";
CM_ SG_ 1070 SGCP_DTC_Idx1 "SGCP diagnostic trouble code index 1";
CM_ SG_ 1070 SGCP_CalChar "SGCP Calibration CVN";
CM_ SG_ 1070 SGCP_Cal_ID_Idx "SGCP Calibration ID Index";
CM_ SG_ 1070 MessageCounter_SGCP_OBD_DTC "This signal is a counter used for safety checks strategies. This counter is incremented of 1 (one) unit at each frame transmission.";
CM_ SG_ 1070 CRC_SGCP_OBD_DTC "CRC according to SAE J1850 standard at each frame transmission.";
CM_ SG_ 1065 MessageCounter_MCPB_OBD_DTC "This signal is a counter used for safety checks strategies. This counter is incremented of 1 (one) unit at each frame transmission.";
CM_ SG_ 1065 MCPB_DTC_Stat2 "MCPB diagnostic trouble code status 1";
CM_ SG_ 1065 MCPB_DTC_Stat1 "MCPB diagnostic trouble code status 1";
CM_ SG_ 1065 MCPB_DTC_Idx2 "MCPB diagnostic trouble code index 2";
CM_ SG_ 1065 MCPB_DTC_Idx1 "MCPB diagnostic trouble code index 1";
CM_ SG_ 1065 MCPB_CalChar "MCPB Calibration CVN";
CM_ SG_ 1065 MCPB_Cal_ID_Idx "MCPB Calibration ID Index";
CM_ SG_ 1065 CRC_MCPB_OBD_DTC "CRC according to SAE J1850 standard at each frame transmission.";
CM_ SG_ 1057 MessageCounter_MCPA_OBD_DTC "This signal is a counter used for safety checks strategies. This counter is incremented of 1 (one) unit at each frame transmission.";
CM_ SG_ 1057 MCPA_DTC_Stat2 "MCPA diagnostic trouble code status 1";
CM_ SG_ 1057 MCPA_DTC_Stat1 "MCPA diagnostic trouble code status 1";
CM_ SG_ 1057 MCPA_DTC_Idx2 "MCPA diagnostic trouble code index 2";
CM_ SG_ 1057 MCPA_DTC_Idx1 "MCPA diagnostic trouble code index 1";
CM_ SG_ 1057 MCPA_CalChar "MCPA Calibration CVN";
CM_ SG_ 1057 MCPA_Cal_ID_Idx "MCPA Calibration ID Index";
CM_ SG_ 1057 CRC_MCPA_OBD_DTC "CRC according to SAE J1850 standard at each frame transmission.";
CM_ SG_ 263 PropulsionSystemActive_PT "Propulsion system active, [1] = active";
CM_ SG_ 263 Custom_DrvMdSts_PT "The requested state of the drive mode feature";
CM_ SG_ 263 WheelSpeedRearRight "This is the value of the right rear wheel speed";
CM_ SG_ 263 WheelSpeedRearLeft "This is the value of the left rear wheel speed";
CM_ SG_ 263 Transm_Torq_Feedback "Ability of EVCU to honor a torque request from the MRGB";
CM_ SG_ 263 Inertia_Torque_Active "Zero Torque Confirmation for Transmission's Request";
CM_ SG_ 263 Gear_Rq "Desired Gear determined by EVCU";
CM_ SG_ 263 EM_min_Trqdyn_P "Minimum electrical machine torque available (short time limit) Negative: Generating Mode";
CM_ SG_ 263 EM_max_Trqdyn_P "Maximum electrical machine torque available (short time limit). Positive: Motoring Mode";
CM_ SG_ 262 MinEngPowerReqForOilDil "The minimum ICE effective power that grants that the engine oil temperature is high enough to promote a fuel evaporation sufficient to reduce the dilution of the fuel in engine oil";
CM_ SG_ 262 MinEngPowerReqForOilDilEnabler "Flag indicating if the request of the minimum ICE effective power is enabled";
CM_ SG_ 262 Torque_Interface_Mask "Bit mask signal representing conditions when the torque is not accurate.";
CM_ SG_ 271 GasFlwEnblsFuAtStr "VVT (Variable Valve Timing), Throttle and DSVL (Dual Stage Valve Lift) actutors are on target, to allow fuel at start of the engine";
CM_ SG_ 263 EOPB_Min_Oil_FlwRate_Rq "Minimum oil flow sent to the rear Electric Oil Pump";
BA_DEF_ SG_ "GenSigTimeoutTime_MRGB" INT 0 65535;
BA_DEF_ SG_ "GenSigTimeoutTime_TCM" INT 0 65535;
BA_DEF_ SG_ "GenSigTimeoutTime_ECM" INT 0 65535;
BA_DEF_ SG_ "GenSigTimeoutTime_SGCP" INT 0 65535;
BA_DEF_ SG_ "GenSigStartValue" INT 0 2147483647;
BA_DEF_ SG_ "GenSigInactiveValue" INT 0 2147483647;
BA_DEF_ SG_ "GenSigSendType" ENUM "NotUsed","OnWrite","OnWriteWithRepetition","OnChange","OnChangeWithRepetition","IfActive","IfActiveWithRepetition","NoSigSendType";
BA_DEF_ SG_ "SystemSignalLongSymbol" STRING ;
BA_DEF_ SG_ "GenSigTimeoutTime_AGSM" INT 0 65535;
BA_DEF_ SG_ "GenSigTimeoutTime_EVCU2" INT 0 65535;
BA_DEF_ SG_ "GenSigTimeoutTime_MCPA" INT 0 65535;
BA_DEF_ SG_ "GenSigTimeoutTime_MCPB" INT 0 65535;
BA_DEF_ BO_ "DiagRequest" ENUM "No","Yes";
BA_DEF_ BO_ "Type" ENUM "P","C","PE","COC","PE_Cntrl","E","E_Cntrl","OC","S","BAF","DC","EM","MM","ISO-TP","-";
BA_DEF_ BO_ "DiagResponse" ENUM "No","Yes";
BA_DEF_ BO_ "NmMessage" ENUM "No","Yes";
BA_DEF_ BO_ "GenMsgSendType" ENUM "Cyclic","NotUsed","NotUsed","NotUsed","NotUsed","NotUsed","NotUsed","NotUsed","NoMsgSendType";
BA_DEF_ BO_ "GenMsgNrOfRepetition" INT 0 255;
BA_DEF_ BO_ "GenMsgILSupport" ENUM "No","Yes";
BA_DEF_ BO_ "GenMsgStartDelayTime" INT 0 65535;
BA_DEF_ BO_ "GenMsgCycleTimeFast" INT 0 65535;
BA_DEF_ BO_ "GenMsgCycleTime" INT 0 65535;
BA_DEF_ BO_ "GenMsgDelayTime" INT 0 65535;
BA_DEF_ BO_ "NmAsrMessage" ENUM "No","Yes";
BA_DEF_ BO_ "DiagState" ENUM "No","Yes";
BA_DEF_ BO_ "DiagConnection" HEX 0 65535;
BA_DEF_ BO_ "VFrameFormat" ENUM "StandardCAN","ExtendedCAN","reserved","reserved","reserved","reserved","reserved","reserved","reserved","reserved","reserved","reserved","reserved","reserved","StandardCAN_FD","ExtendedCAN_FD";
BA_DEF_ BO_ "CANFD_BRS" ENUM "0","1";
BA_DEF_DEF_ "GenSigTimeoutTime_MRGB" 2500;
BA_DEF_DEF_ "GenSigTimeoutTime_TCM" 2500;
BA_DEF_DEF_ "GenSigTimeoutTime_ECM" 2500;
BA_DEF_DEF_ "GenSigTimeoutTime_SGCP" 2500;
BA_DEF_DEF_ "GenSigStartValue" 0;
BA_DEF_DEF_ "GenSigInactiveValue" 0;
BA_DEF_DEF_ "GenSigSendType" "NoSigSendType";
BA_DEF_DEF_ "SystemSignalLongSymbol" "";
BA_DEF_DEF_ "GenSigTimeoutTime_AGSM" 2500;
BA_DEF_DEF_ "GenSigTimeoutTime_EVCU2" 2500;
BA_DEF_DEF_ "GenSigTimeoutTime_MCPA" 2500;
BA_DEF_DEF_ "GenSigTimeoutTime_MCPB" 2500;
BA_DEF_DEF_ "DiagRequest" "No";
BA_DEF_DEF_ "Type" "-";
BA_DEF_DEF_ "DiagResponse" "No";
BA_DEF_DEF_ "NmMessage" "No";
BA_DEF_DEF_ "GenMsgSendType" "NoMsgSendType";
BA_DEF_DEF_ "GenMsgNrOfRepetition" 0;
BA_DEF_DEF_ "GenMsgILSupport" "No";
BA_DEF_DEF_ "GenMsgStartDelayTime" 0;
BA_DEF_DEF_ "GenMsgCycleTimeFast" 0;
BA_DEF_DEF_ "GenMsgCycleTime" 0;
BA_DEF_DEF_ "GenMsgDelayTime" 0;
BA_DEF_DEF_ "NmAsrMessage" "No";
BA_DEF_DEF_ "DiagState" "No";
BA_DEF_DEF_ "DiagConnection" 0;
BA_DEF_DEF_ "VFrameFormat" "StandardCAN_FD";
BA_DEF_DEF_ "CANFD_BRS" "0";
BA_ "Type" BO_ 271 1;
BA_ "GenMsgSendType" BO_ 271 0;
BA_ "GenMsgILSupport" BO_ 271 1;
BA_ "GenMsgCycleTime" BO_ 271 10;
BA_ "CANFD_BRS" BO_ 271 1;
BA_ "Type" BO_ 262 1;
BA_ "GenMsgSendType" BO_ 262 0;
BA_ "GenMsgILSupport" BO_ 262 1;
BA_ "GenMsgCycleTime" BO_ 262 10;
BA_ "CANFD_BRS" BO_ 262 1;
BA_ "GenMsgILSupport" BO_ 258 1;
BA_ "Type" BO_ 258 1;
BA_ "GenMsgSendType" BO_ 258 0;
BA_ "GenMsgCycleTime" BO_ 258 10;
BA_ "CANFD_BRS" BO_ 258 1;
BA_ "Type" BO_ 476 3;
BA_ "GenMsgSendType" BO_ 476 0;
BA_ "GenMsgNrOfRepetition" BO_ 476 2;
BA_ "GenMsgILSupport" BO_ 476 1;
BA_ "GenMsgCycleTimeFast" BO_ 476 20;
BA_ "GenMsgCycleTime" BO_ 476 20;
BA_ "GenMsgDelayTime" BO_ 476 15;
BA_ "CANFD_BRS" BO_ 476 1;
BA_ "Type" BO_ 2654486617 8;
BA_ "NmMessage" BO_ 2654486617 1;
BA_ "NmAsrMessage" BO_ 2654486617 1;
BA_ "VFrameFormat" BO_ 2654486617 15;
BA_ "CANFD_BRS" BO_ 2654486617 1;
BA_ "NmAsrMessage" BO_ 2654486616 1;
BA_ "VFrameFormat" BO_ 2654486616 15;
BA_ "CANFD_BRS" BO_ 2654486616 1;
BA_ "Type" BO_ 2654486616 8;
BA_ "NmMessage" BO_ 2654486616 1;
BA_ "Type" BO_ 2564682261 8;
BA_ "DiagResponse" BO_ 2564682261 1;
BA_ "DiagConnection" BO_ 2564682261 61973;
BA_ "VFrameFormat" BO_ 2564682261 15;
BA_ "CANFD_BRS" BO_ 2564682261 1;
BA_ "Type" BO_ 2564682260 8;
BA_ "DiagResponse" BO_ 2564682260 1;
BA_ "DiagConnection" BO_ 2564682260 61972;
BA_ "VFrameFormat" BO_ 2564682260 15;
BA_ "CANFD_BRS" BO_ 2564682260 1;
BA_ "Type" BO_ 2564485396 8;
BA_ "DiagResponse" BO_ 2564485396 1;
BA_ "DiagConnection" BO_ 2564485396 61716;
BA_ "VFrameFormat" BO_ 2564485396 1;
BA_ "Type" BO_ 2564485653 8;
BA_ "DiagResponse" BO_ 2564485653 1;
BA_ "DiagConnection" BO_ 2564485653 61973;
BA_ "VFrameFormat" BO_ 2564485653 15;
BA_ "CANFD_BRS" BO_ 2564485653 1;
BA_ "DiagConnection" BO_ 2564485652 61972;
BA_ "VFrameFormat" BO_ 2564485652 15;
BA_ "CANFD_BRS" BO_ 2564485652 1;
BA_ "Type" BO_ 2564485652 8;
BA_ "DiagResponse" BO_ 2564485652 1;
BA_ "DiagRequest" BO_ 2564429297 1;
BA_ "Type" BO_ 2564429297 8;
BA_ "DiagConnection" BO_ 2564429297 61717;
BA_ "VFrameFormat" BO_ 2564429297 1;
BA_ "DiagRequest" BO_ 2564429298 1;
BA_ "Type" BO_ 2564429298 8;
BA_ "DiagConnection" BO_ 2564429298 61973;
BA_ "VFrameFormat" BO_ 2564429298 15;
BA_ "CANFD_BRS" BO_ 2564429298 1;
BA_ "DiagConnection" BO_ 2564429042 61972;
BA_ "VFrameFormat" BO_ 2564429042 15;
BA_ "CANFD_BRS" BO_ 2564429042 1;
BA_ "DiagRequest" BO_ 2564429042 1;
BA_ "Type" BO_ 2564429042 8;
BA_ "Type" BO_ 2651930713 11;
BA_ "GenMsgILSupport" BO_ 2651930713 1;
BA_ "VFrameFormat" BO_ 2651930713 15;
BA_ "CANFD_BRS" BO_ 2651930713 1;
BA_ "Type" BO_ 2651930712 11;
BA_ "GenMsgILSupport" BO_ 2651930712 1;
BA_ "VFrameFormat" BO_ 2651930712 15;
BA_ "CANFD_BRS" BO_ 2651930712 1;
BA_ "Type" BO_ 496 1;
BA_ "GenMsgSendType" BO_ 496 0;
BA_ "GenMsgILSupport" BO_ 496 1;
BA_ "GenMsgCycleTime" BO_ 496 10;
BA_ "CANFD_BRS" BO_ 496 1;
BA_ "Type" BO_ 105 3;
BA_ "GenMsgSendType" BO_ 105 0;
BA_ "GenMsgILSupport" BO_ 105 1;
BA_ "GenMsgCycleTime" BO_ 105 1000;
BA_ "GenMsgDelayTime" BO_ 105 100;
BA_ "CANFD_BRS" BO_ 105 1;
BA_ "Type" BO_ 2654339273 1;
BA_ "GenMsgSendType" BO_ 2654339273 0;
BA_ "GenMsgILSupport" BO_ 2654339273 1;
BA_ "GenMsgCycleTime" BO_ 2654339273 1000;
BA_ "VFrameFormat" BO_ 2654339273 15;
BA_ "CANFD_BRS" BO_ 2654339273 1;
BA_ "Type" BO_ 2654339161 1;
BA_ "GenMsgSendType" BO_ 2654339161 0;
BA_ "GenMsgILSupport" BO_ 2654339161 1;
BA_ "GenMsgCycleTime" BO_ 2654339161 1000;
BA_ "VFrameFormat" BO_ 2654339161 15;
BA_ "CANFD_BRS" BO_ 2654339161 1;
BA_ "Type" BO_ 2654339160 1;
BA_ "GenMsgSendType" BO_ 2654339160 0;
BA_ "GenMsgILSupport" BO_ 2654339160 1;
BA_ "GenMsgCycleTime" BO_ 2654339160 1000;
BA_ "VFrameFormat" BO_ 2654339160 15;
BA_ "CANFD_BRS" BO_ 2654339160 1;
BA_ "Type" BO_ 2564682364 8;
BA_ "DiagResponse" BO_ 2564682364 1;
BA_ "DiagConnection" BO_ 2564682364 62076;
BA_ "VFrameFormat" BO_ 2564682364 15;
BA_ "CANFD_BRS" BO_ 2564682364 1;
BA_ "Type" BO_ 2564485756 8;
BA_ "DiagResponse" BO_ 2564485756 1;
BA_ "DiagConnection" BO_ 2564485756 62076;
BA_ "VFrameFormat" BO_ 2564485756 15;
BA_ "CANFD_BRS" BO_ 2564485756 1;
BA_ "Type" BO_ 2564455666 8;
BA_ "DiagConnection" BO_ 2564455666 62076;
BA_ "VFrameFormat" BO_ 2564455666 15;
BA_ "CANFD_BRS" BO_ 2564455666 1;
BA_ "DiagRequest" BO_ 2564455666 1;
BA_ "Type" BO_ 263 1;
BA_ "GenMsgSendType" BO_ 263 0;
BA_ "GenMsgILSupport" BO_ 263 1;
BA_ "GenMsgCycleTime" BO_ 263 10;
BA_ "CANFD_BRS" BO_ 263 1;
BA_ "Type" BO_ 2654486729 8;
BA_ "NmMessage" BO_ 2654486729 1;
BA_ "NmAsrMessage" BO_ 2654486729 1;
BA_ "VFrameFormat" BO_ 2654486729 15;
BA_ "CANFD_BRS" BO_ 2654486729 1;
BA_ "Type" BO_ 2651930825 11;
BA_ "GenMsgILSupport" BO_ 2651930825 1;
BA_ "VFrameFormat" BO_ 2651930825 15;
BA_ "CANFD_BRS" BO_ 2651930825 1;
BA_ "Type" BO_ 216 1;
BA_ "GenMsgSendType" BO_ 216 0;
BA_ "GenMsgILSupport" BO_ 216 1;
BA_ "GenMsgCycleTime" BO_ 216 10;
BA_ "CANFD_BRS" BO_ 216 1;
BA_ "Type" BO_ 2654486592 8;
BA_ "NmMessage" BO_ 2654486592 1;
BA_ "NmAsrMessage" BO_ 2654486592 1;
BA_ "VFrameFormat" BO_ 2654486592 15;
BA_ "CANFD_BRS" BO_ 2654486592 1;
BA_ "Type" BO_ 1811 1;
BA_ "GenMsgSendType" BO_ 1811 0;
BA_ "GenMsgILSupport" BO_ 1811 1;
BA_ "GenMsgCycleTime" BO_ 1811 1000;
BA_ "GenMsgDelayTime" BO_ 1811 20;
BA_ "CANFD_BRS" BO_ 1811 1;
BA_ "Type" BO_ 1070 1;
BA_ "GenMsgSendType" BO_ 1070 0;
BA_ "GenMsgILSupport" BO_ 1070 1;
BA_ "GenMsgCycleTime" BO_ 1070 100;
BA_ "CANFD_BRS" BO_ 1070 1;
BA_ "Type" BO_ 1065 1;
BA_ "GenMsgSendType" BO_ 1065 0;
BA_ "GenMsgILSupport" BO_ 1065 1;
BA_ "GenMsgCycleTime" BO_ 1065 100;
BA_ "CANFD_BRS" BO_ 1065 1;
BA_ "Type" BO_ 1057 1;
BA_ "GenMsgSendType" BO_ 1057 0;
BA_ "GenMsgILSupport" BO_ 1057 1;
BA_ "GenMsgCycleTime" BO_ 1057 100;
BA_ "CANFD_BRS" BO_ 1057 1;
BA_ "Type" BO_ 286 1;
BA_ "GenMsgSendType" BO_ 286 0;
BA_ "GenMsgILSupport" BO_ 286 1;
BA_ "GenMsgCycleTime" BO_ 286 10;
BA_ "CANFD_BRS" BO_ 286 1;
BA_ "GenSigTimeoutTime_MRGB" SG_ 262 EngTrq_Enbl_Rq_TCM_W 0;
BA_ "GenSigTimeoutTime_ECM" SG_ 262 EngTrq_Enbl_Rq_TCM_W 0;
BA_ "GenSigTimeoutTime_SGCP" SG_ 262 EngTrq_Enbl_Rq_TCM_W 0;
BA_ "GenSigTimeoutTime_AGSM" SG_ 262 EngTrq_Enbl_Rq_TCM_W 0;
BA_ "GenSigTimeoutTime_EVCU2" SG_ 262 EngTrq_Enbl_Rq_TCM_W 0;
BA_ "GenSigTimeoutTime_MCPA" SG_ 262 EngTrq_Enbl_Rq_TCM_W 0;
BA_ "GenSigTimeoutTime_MCPB" SG_ 262 EngTrq_Enbl_Rq_TCM_W 0;
BA_ "GenSigTimeoutTime_MRGB" SG_ 262 EngineSts_W 0;
BA_ "GenSigTimeoutTime_ECM" SG_ 262 EngineSts_W 0;
BA_ "GenSigTimeoutTime_SGCP" SG_ 262 EngineSts_W 0;
BA_ "GenSigStartValue" SG_ 262 EngineSts_W 3;
BA_ "GenSigTimeoutTime_AGSM" SG_ 262 EngineSts_W 0;
BA_ "GenSigTimeoutTime_EVCU2" SG_ 262 EngineSts_W 0;
BA_ "GenSigTimeoutTime_MCPA" SG_ 262 EngineSts_W 0;
BA_ "GenSigTimeoutTime_MCPB" SG_ 262 EngineSts_W 0;
BA_ "GenSigTimeoutTime_MRGB" SG_ 262 EngineSpeed_W 0;
BA_ "GenSigTimeoutTime_ECM" SG_ 262 EngineSpeed_W 0;
BA_ "GenSigTimeoutTime_AGSM" SG_ 262 EngineSpeed_W 0;
BA_ "GenSigTimeoutTime_EVCU2" SG_ 262 EngineSpeed_W 0;
BA_ "GenSigTimeoutTime_MCPA" SG_ 262 EngineSpeed_W 0;
BA_ "GenSigTimeoutTime_MCPB" SG_ 262 EngineSpeed_W 0;
BA_ "GenSigTimeoutTime_ECM" SG_ 262 EngineSpeedFailSts_W 0;
BA_ "GenSigTimeoutTime_AGSM" SG_ 262 EngineSpeedFailSts_W 0;
BA_ "GenSigTimeoutTime_EVCU2" SG_ 262 EngineSpeedFailSts_W 0;
BA_ "GenSigTimeoutTime_MRGB" SG_ 271 MinImmedEngTorqCap 0;
BA_ "GenSigTimeoutTime_ECM" SG_ 271 MinImmedEngTorqCap 0;
BA_ "GenSigTimeoutTime_SGCP" SG_ 271 MinImmedEngTorqCap 0;
BA_ "GenSigStartValue" SG_ 271 MinImmedEngTorqCap 938;
BA_ "GenSigTimeoutTime_ECM" SG_ 271 MinEngTorqCapV 0;
BA_ "GenSigTimeoutTime_SGCP" SG_ 271 MinEngTorqCapV 0;
BA_ "GenSigTimeoutTime_AGSM" SG_ 271 MinEngTorqCapV 0;
BA_ "GenSigTimeoutTime_MCPA" SG_ 271 MinEngTorqCapV 0;
BA_ "GenSigTimeoutTime_MCPB" SG_ 271 MinEngTorqCapV 0;
BA_ "GenSigTimeoutTime_ECM" SG_ 271 MinEngTorqCap 0;
BA_ "GenSigTimeoutTime_SGCP" SG_ 271 MinEngTorqCap 0;
BA_ "GenSigStartValue" SG_ 271 MinEngTorqCap 938;
BA_ "GenSigTimeoutTime_AGSM" SG_ 271 MinEngTorqCap 0;
BA_ "GenSigTimeoutTime_MCPA" SG_ 271 MinEngTorqCap 0;
BA_ "GenSigTimeoutTime_MCPB" SG_ 271 MinEngTorqCap 0;
BA_ "GenSigTimeoutTime_MRGB" SG_ 271 MinAirFlowMinSparkTorqCapV 0;
BA_ "GenSigTimeoutTime_ECM" SG_ 271 MinAirFlowMinSparkTorqCapV 0;
BA_ "GenSigTimeoutTime_SGCP" SG_ 271 MinAirFlowMinSparkTorqCapV 0;
BA_ "GenSigTimeoutTime_AGSM" SG_ 271 MinAirFlowMinSparkTorqCapV 0;
BA_ "GenSigTimeoutTime_EVCU2" SG_ 271 MinAirFlowMinSparkTorqCapV 0;
BA_ "GenSigTimeoutTime_MCPA" SG_ 271 MinAirFlowMinSparkTorqCapV 0;
BA_ "GenSigTimeoutTime_MCPB" SG_ 271 MinAirFlowMinSparkTorqCapV 0;
BA_ "GenSigTimeoutTime_MRGB" SG_ 271 MinAirFlowMinSparkTorqCap 0;
BA_ "GenSigTimeoutTime_ECM" SG_ 271 MinAirFlowMinSparkTorqCap 0;
BA_ "GenSigTimeoutTime_SGCP" SG_ 271 MinAirFlowMinSparkTorqCap 0;
BA_ "GenSigStartValue" SG_ 271 MinAirFlowMinSparkTorqCap 938;
BA_ "GenSigTimeoutTime_AGSM" SG_ 271 MinAirFlowMinSparkTorqCap 0;
BA_ "GenSigTimeoutTime_EVCU2" SG_ 271 MinAirFlowMinSparkTorqCap 0;
BA_ "GenSigTimeoutTime_MCPA" SG_ 271 MinAirFlowMinSparkTorqCap 0;
BA_ "GenSigTimeoutTime_MCPB" SG_ 271 MinAirFlowMinSparkTorqCap 0;
BA_ "GenSigTimeoutTime_MRGB" SG_ 271 MessageCounter_ENGINE_HYBD_FD_1 0;
BA_ "GenSigTimeoutTime_ECM" SG_ 271 MessageCounter_ENGINE_HYBD_FD_1 0;
BA_ "GenSigTimeoutTime_SGCP" SG_ 271 MessageCounter_ENGINE_HYBD_FD_1 0;
BA_ "GenSigTimeoutTime_AGSM" SG_ 271 MessageCounter_ENGINE_HYBD_FD_1 0;
BA_ "GenSigTimeoutTime_EVCU2" SG_ 271 MessageCounter_ENGINE_HYBD_FD_1 0;
BA_ "GenSigTimeoutTime_MCPA" SG_ 271 MessageCounter_ENGINE_HYBD_FD_1 0;
BA_ "GenSigTimeoutTime_MCPB" SG_ 271 MessageCounter_ENGINE_HYBD_FD_1 0;
BA_ "GenSigTimeoutTime_MRGB" SG_ 271 MaxPrdtdEngTorqCapV 0;
BA_ "GenSigTimeoutTime_ECM" SG_ 271 MaxPrdtdEngTorqCapV 0;
BA_ "GenSigTimeoutTime_SGCP" SG_ 271 MaxPrdtdEngTorqCapV 0;
BA_ "GenSigTimeoutTime_AGSM" SG_ 271 MaxPrdtdEngTorqCapV 0;
BA_ "GenSigTimeoutTime_EVCU2" SG_ 271 MaxPrdtdEngTorqCapV 0;
BA_ "GenSigTimeoutTime_MCPA" SG_ 271 MaxPrdtdEngTorqCapV 0;
BA_ "GenSigTimeoutTime_MCPB" SG_ 271 MaxPrdtdEngTorqCapV 0;
BA_ "GenSigTimeoutTime_MRGB" SG_ 271 MaxPrdtdEngTorqCap 0;
BA_ "GenSigTimeoutTime_ECM" SG_ 271 MaxPrdtdEngTorqCap 0;
BA_ "GenSigTimeoutTime_SGCP" SG_ 271 MaxPrdtdEngTorqCap 0;
BA_ "GenSigStartValue" SG_ 271 MaxPrdtdEngTorqCap 938;
BA_ "GenSigTimeoutTime_AGSM" SG_ 271 MaxPrdtdEngTorqCap 0;
BA_ "GenSigTimeoutTime_EVCU2" SG_ 271 MaxPrdtdEngTorqCap 0;
BA_ "GenSigTimeoutTime_MCPA" SG_ 271 MaxPrdtdEngTorqCap 0;
BA_ "GenSigTimeoutTime_MCPB" SG_ 271 MaxPrdtdEngTorqCap 0;
BA_ "GenSigTimeoutTime_ECM" SG_ 271 MaxOffEngTorqCap 0;
BA_ "GenSigTimeoutTime_SGCP" SG_ 271 MaxOffEngTorqCap 0;
BA_ "GenSigStartValue" SG_ 271 MaxOffEngTorqCap 938;
BA_ "GenSigTimeoutTime_AGSM" SG_ 271 MaxOffEngTorqCap 0;
BA_ "GenSigTimeoutTime_MCPA" SG_ 271 MaxOffEngTorqCap 0;
BA_ "GenSigTimeoutTime_MCPB" SG_ 271 MaxOffEngTorqCap 0;
BA_ "GenSigTimeoutTime_ECM" SG_ 271 HybActEngTorqRespTyp 0;
BA_ "GenSigTimeoutTime_SGCP" SG_ 271 HybActEngTorqRespTyp 0;
BA_ "GenSigTimeoutTime_AGSM" SG_ 271 HybActEngTorqRespTyp 0;
BA_ "GenSigTimeoutTime_MCPA" SG_ 271 HybActEngTorqRespTyp 0;
BA_ "GenSigTimeoutTime_MCPB" SG_ 271 HybActEngTorqRespTyp 0;
BA_ "GenSigTimeoutTime_ECM" SG_ 271 Feedback_HCP 0;
BA_ "GenSigTimeoutTime_SGCP" SG_ 271 Feedback_HCP 0;
BA_ "GenSigTimeoutTime_AGSM" SG_ 271 Feedback_HCP 0;
BA_ "GenSigTimeoutTime_MCPA" SG_ 271 Feedback_HCP 0;
BA_ "GenSigTimeoutTime_MCPB" SG_ 271 Feedback_HCP 0;
BA_ "GenSigTimeoutTime_ECM" SG_ 271 ETRQ_Mode 0;
BA_ "GenSigTimeoutTime_SGCP" SG_ 271 ETRQ_Mode 0;
BA_ "GenSigTimeoutTime_AGSM" SG_ 271 ETRQ_Mode 0;
BA_ "GenSigTimeoutTime_MCPA" SG_ 271 ETRQ_Mode 0;
BA_ "GenSigTimeoutTime_MCPB" SG_ 271 ETRQ_Mode 0;
BA_ "GenSigTimeoutTime_ECM" SG_ 271 EngTrqReserveReq 0;
BA_ "GenSigTimeoutTime_SGCP" SG_ 271 EngTrqReserveReq 0;
BA_ "GenSigTimeoutTime_AGSM" SG_ 271 EngTrqReserveReq 0;
BA_ "GenSigTimeoutTime_MCPA" SG_ 271 EngTrqReserveReq 0;
BA_ "GenSigTimeoutTime_MCPB" SG_ 271 EngTrqReserveReq 0;
BA_ "GenSigTimeoutTime_ECM" SG_ 271 EngRunCrnkAct 0;
BA_ "GenSigTimeoutTime_SGCP" SG_ 271 EngRunCrnkAct 0;
BA_ "GenSigTimeoutTime_AGSM" SG_ 271 EngRunCrnkAct 0;
BA_ "GenSigTimeoutTime_MCPA" SG_ 271 EngRunCrnkAct 0;
BA_ "GenSigTimeoutTime_MCPB" SG_ 271 EngRunCrnkAct 0;
BA_ "GenSigTimeoutTime_MRGB" SG_ 271 EngAirFlwStdyStTorqV 0;
BA_ "GenSigTimeoutTime_ECM" SG_ 271 EngAirFlwStdyStTorqV 0;
BA_ "GenSigTimeoutTime_SGCP" SG_ 271 EngAirFlwStdyStTorqV 0;
BA_ "GenSigTimeoutTime_AGSM" SG_ 271 EngAirFlwStdyStTorqV 0;
BA_ "GenSigTimeoutTime_EVCU2" SG_ 271 EngAirFlwStdyStTorqV 0;
BA_ "GenSigTimeoutTime_MCPA" SG_ 271 EngAirFlwStdyStTorqV 0;
BA_ "GenSigTimeoutTime_MCPB" SG_ 271 EngAirFlwStdyStTorqV 0;
BA_ "GenSigTimeoutTime_MRGB" SG_ 271 EngAirFlwStdyStTorq 0;
BA_ "GenSigTimeoutTime_ECM" SG_ 271 EngAirFlwStdyStTorq 0;
BA_ "GenSigTimeoutTime_SGCP" SG_ 271 EngAirFlwStdyStTorq 0;
BA_ "GenSigStartValue" SG_ 271 EngAirFlwStdyStTorq 938;
BA_ "GenSigTimeoutTime_AGSM" SG_ 271 EngAirFlwStdyStTorq 0;
BA_ "GenSigTimeoutTime_EVCU2" SG_ 271 EngAirFlwStdyStTorq 0;
BA_ "GenSigTimeoutTime_MCPA" SG_ 271 EngAirFlwStdyStTorq 0;
BA_ "GenSigTimeoutTime_MCPB" SG_ 271 EngAirFlwStdyStTorq 0;
BA_ "GenSigTimeoutTime_ECM" SG_ 271 EngActuatorsStat 0;
BA_ "GenSigTimeoutTime_SGCP" SG_ 271 EngActuatorsStat 0;
BA_ "GenSigTimeoutTime_AGSM" SG_ 271 EngActuatorsStat 0;
BA_ "GenSigTimeoutTime_MCPA" SG_ 271 EngActuatorsStat 0;
BA_ "GenSigTimeoutTime_MCPB" SG_ 271 EngActuatorsStat 0;
BA_ "GenSigTimeoutTime_ECM" SG_ 271 EngActStdyStTorqV 0;
BA_ "GenSigTimeoutTime_SGCP" SG_ 271 EngActStdyStTorqV 0;
BA_ "GenSigTimeoutTime_AGSM" SG_ 271 EngActStdyStTorqV 0;
BA_ "GenSigTimeoutTime_MCPA" SG_ 271 EngActStdyStTorqV 0;
BA_ "GenSigTimeoutTime_MCPB" SG_ 271 EngActStdyStTorqV 0;
BA_ "GenSigTimeoutTime_MRGB" SG_ 271 CRC_ENGINE_HYBD_FD_1 0;
BA_ "GenSigTimeoutTime_ECM" SG_ 271 CRC_ENGINE_HYBD_FD_1 0;
BA_ "GenSigTimeoutTime_SGCP" SG_ 271 CRC_ENGINE_HYBD_FD_1 0;
BA_ "GenSigTimeoutTime_AGSM" SG_ 271 CRC_ENGINE_HYBD_FD_1 0;
BA_ "GenSigTimeoutTime_EVCU2" SG_ 271 CRC_ENGINE_HYBD_FD_1 0;
BA_ "GenSigTimeoutTime_MCPA" SG_ 271 CRC_ENGINE_HYBD_FD_1 0;
BA_ "GenSigTimeoutTime_MCPB" SG_ 271 CRC_ENGINE_HYBD_FD_1 0;
BA_ "GenSigTimeoutTime_ECM" SG_ 271 EngActStdyStTorq 0;
BA_ "GenSigTimeoutTime_SGCP" SG_ 271 EngActStdyStTorq 0;
BA_ "GenSigStartValue" SG_ 271 EngActStdyStTorq 938;
BA_ "GenSigTimeoutTime_AGSM" SG_ 271 EngActStdyStTorq 0;
BA_ "GenSigTimeoutTime_MCPA" SG_ 271 EngActStdyStTorq 0;
BA_ "GenSigTimeoutTime_MCPB" SG_ 271 EngActStdyStTorq 0;
BA_ "GenSigTimeoutTime_MRGB" SG_ 262 LV12PwrFreeRq_W 0;
BA_ "GenSigTimeoutTime_ECM" SG_ 262 LV12PwrFreeRq_W 0;
BA_ "GenSigTimeoutTime_SGCP" SG_ 262 LV12PwrFreeRq_W 0;
BA_ "GenSigTimeoutTime_AGSM" SG_ 262 LV12PwrFreeRq_W 0;
BA_ "GenSigTimeoutTime_EVCU2" SG_ 262 LV12PwrFreeRq_W 0;
BA_ "GenSigTimeoutTime_MCPA" SG_ 262 LV12PwrFreeRq_W 0;
BA_ "GenSigTimeoutTime_MCPB" SG_ 262 LV12PwrFreeRq_W 0;
BA_ "GenSigTimeoutTime_MRGB" SG_ 262 MessageCounter_ENGINE2 0;
BA_ "GenSigTimeoutTime_ECM" SG_ 262 MessageCounter_ENGINE2 0;
BA_ "GenSigTimeoutTime_SGCP" SG_ 262 MessageCounter_ENGINE2 0;
BA_ "GenSigTimeoutTime_AGSM" SG_ 262 MessageCounter_ENGINE2 0;
BA_ "GenSigTimeoutTime_EVCU2" SG_ 262 MessageCounter_ENGINE2 0;
BA_ "GenSigTimeoutTime_MCPA" SG_ 262 MessageCounter_ENGINE2 0;
BA_ "GenSigTimeoutTime_MCPB" SG_ 262 MessageCounter_ENGINE2 0;
BA_ "GenSigTimeoutTime_MRGB" SG_ 271 EngTrqFSO_CurrAir 0;
BA_ "GenSigTimeoutTime_ECM" SG_ 271 EngTrqFSO_CurrAir 0;
BA_ "GenSigTimeoutTime_AGSM" SG_ 271 EngTrqFSO_CurrAir 0;
BA_ "GenSigTimeoutTime_EVCU2" SG_ 271 EngTrqFSO_CurrAir 0;
BA_ "GenSigTimeoutTime_MCPA" SG_ 271 EngTrqFSO_CurrAir 0;
BA_ "GenSigTimeoutTime_MCPB" SG_ 271 EngTrqFSO_CurrAir 0;
BA_ "GenSigTimeoutTime_AGSM" SG_ 262 EssEngStrtIsNotAllwdID 0;
BA_ "GenSigTimeoutTime_MCPA" SG_ 262 EssEngStrtIsNotAllwdID 0;
BA_ "GenSigTimeoutTime_MCPB" SG_ 262 EssEngStrtIsNotAllwdID 0;
BA_ "GenSigTimeoutTime_ECM" SG_ 262 CompressionTest 0;
BA_ "GenSigTimeoutTime_SGCP" SG_ 262 CompressionTest 0;
BA_ "GenSigTimeoutTime_AGSM" SG_ 262 CompressionTest 0;
BA_ "GenSigTimeoutTime_MCPA" SG_ 262 CompressionTest 0;
BA_ "GenSigTimeoutTime_MCPB" SG_ 262 CompressionTest 0;
BA_ "GenSigTimeoutTime_ECM" SG_ 271 EngMinSparkNomCurrAirTorqCap 0;
BA_ "GenSigTimeoutTime_SGCP" SG_ 271 EngMinSparkNomCurrAirTorqCap 0;
BA_ "GenSigTimeoutTime_AGSM" SG_ 271 EngMinSparkNomCurrAirTorqCap 0;
BA_ "GenSigTimeoutTime_MCPA" SG_ 271 EngMinSparkNomCurrAirTorqCap 0;
BA_ "GenSigTimeoutTime_MCPB" SG_ 271 EngMinSparkNomCurrAirTorqCap 0;
BA_ "GenSigTimeoutTime_ECM" SG_ 271 RedSpkAuthorityAvbl 0;
BA_ "GenSigTimeoutTime_SGCP" SG_ 271 RedSpkAuthorityAvbl 0;
BA_ "GenSigTimeoutTime_AGSM" SG_ 271 RedSpkAuthorityAvbl 0;
BA_ "GenSigTimeoutTime_MCPA" SG_ 271 RedSpkAuthorityAvbl 0;
BA_ "GenSigTimeoutTime_MCPB" SG_ 271 RedSpkAuthorityAvbl 0;
BA_ "GenSigTimeoutTime_ECM" SG_ 271 MAP_4_BAR_PHEV 0;
BA_ "GenSigTimeoutTime_SGCP" SG_ 271 MAP_4_BAR_PHEV 0;
BA_ "GenSigStartValue" SG_ 271 MAP_4_BAR_PHEV 511;
BA_ "GenSigTimeoutTime_AGSM" SG_ 271 MAP_4_BAR_PHEV 0;
BA_ "GenSigTimeoutTime_MCPA" SG_ 271 MAP_4_BAR_PHEV 0;
BA_ "GenSigTimeoutTime_MCPB" SG_ 271 MAP_4_BAR_PHEV 0;
BA_ "GenSigTimeoutTime_ECM" SG_ 262 MinEngPowerReqForOilDilEnabler 0;
BA_ "GenSigTimeoutTime_SGCP" SG_ 262 MinEngPowerReqForOilDilEnabler 0;
BA_ "GenSigTimeoutTime_AGSM" SG_ 262 MinEngPowerReqForOilDilEnabler 0;
BA_ "GenSigTimeoutTime_MCPA" SG_ 262 MinEngPowerReqForOilDilEnabler 0;
BA_ "GenSigTimeoutTime_MCPB" SG_ 262 MinEngPowerReqForOilDilEnabler 0;
BA_ "GenSigTimeoutTime_MCPB" SG_ 271 GasFlwEnblsFuAtStr 0;
BA_ "GenSigTimeoutTime_ECM" SG_ 271 GasFlwEnblsFuAtStr 0;
BA_ "GenSigTimeoutTime_SGCP" SG_ 271 GasFlwEnblsFuAtStr 0;
BA_ "GenSigTimeoutTime_AGSM" SG_ 271 GasFlwEnblsFuAtStr 0;
BA_ "GenSigTimeoutTime_MCPA" SG_ 271 GasFlwEnblsFuAtStr 0;
BA_ "GenSigTimeoutTime_ECM" SG_ 262 MinEngPowerReqForOilDil 0;
BA_ "GenSigTimeoutTime_SGCP" SG_ 262 MinEngPowerReqForOilDil 0;
BA_ "GenSigTimeoutTime_AGSM" SG_ 262 MinEngPowerReqForOilDil 0;
BA_ "GenSigTimeoutTime_MCPA" SG_ 262 MinEngPowerReqForOilDil 0;
BA_ "GenSigTimeoutTime_MCPB" SG_ 262 MinEngPowerReqForOilDil 0;
BA_ "GenSigTimeoutTime_TCM" SG_ 286 RELSD_TgtTrq 0;
BA_ "GenSigTimeoutTime_ECM" SG_ 286 RELSD_TgtTrq 0;
BA_ "GenSigTimeoutTime_AGSM" SG_ 286 RELSD_TgtTrq 0;
BA_ "GenSigTimeoutTime_EVCU2" SG_ 286 RELSD_TgtTrq 0;
BA_ "GenSigTimeoutTime_MCPA" SG_ 286 RELSD_TgtTrq 0;
BA_ "GenSigTimeoutTime_MCPB" SG_ 286 RELSD_TgtTrq 0;
BA_ "GenSigTimeoutTime_ECM" SG_ 2651930825 Digit_01_SGCP 0;
BA_ "GenSigTimeoutTime_SGCP" SG_ 2651930825 Digit_01_SGCP 0;
BA_ "GenSigSendType" SG_ 2651930825 Digit_01_SGCP 1;
BA_ "GenSigTimeoutTime_AGSM" SG_ 2651930825 Digit_01_SGCP 0;
BA_ "GenSigTimeoutTime_MCPA" SG_ 2651930825 Digit_01_SGCP 0;
BA_ "GenSigTimeoutTime_MCPB" SG_ 2651930825 Digit_01_SGCP 0;
BA_ "GenSigTimeoutTime_ECM" SG_ 2651930825 Digit_02_SGCP 0;
BA_ "GenSigTimeoutTime_SGCP" SG_ 2651930825 Digit_02_SGCP 0;
BA_ "GenSigTimeoutTime_AGSM" SG_ 2651930825 Digit_02_SGCP 0;
BA_ "GenSigTimeoutTime_MCPA" SG_ 2651930825 Digit_02_SGCP 0;
BA_ "GenSigTimeoutTime_MCPB" SG_ 2651930825 Digit_02_SGCP 0;
BA_ "GenSigTimeoutTime_ECM" SG_ 2651930825 Digit_03_SGCP 0;
BA_ "GenSigTimeoutTime_SGCP" SG_ 2651930825 Digit_03_SGCP 0;
BA_ "GenSigTimeoutTime_AGSM" SG_ 2651930825 Digit_03_SGCP 0;
BA_ "GenSigTimeoutTime_MCPA" SG_ 2651930825 Digit_03_SGCP 0;
BA_ "GenSigTimeoutTime_MCPB" SG_ 2651930825 Digit_03_SGCP 0;
BA_ "GenSigTimeoutTime_ECM" SG_ 2654339161 GenericFailSts_FD16_MCPB 0;
BA_ "GenSigTimeoutTime_SGCP" SG_ 2654339161 GenericFailSts_FD16_MCPB 0;
BA_ "GenSigTimeoutTime_AGSM" SG_ 2654339161 GenericFailSts_FD16_MCPB 0;
BA_ "GenSigTimeoutTime_MCPA" SG_ 2654339161 GenericFailSts_FD16_MCPB 0;
BA_ "GenSigTimeoutTime_MCPB" SG_ 2654339161 GenericFailSts_FD16_MCPB 0;
BA_ "GenSigTimeoutTime_ECM" SG_ 2654339160 CurrentFailSts_FD16_MCPA 0;
BA_ "GenSigTimeoutTime_SGCP" SG_ 2654339160 CurrentFailSts_FD16_MCPA 0;
BA_ "GenSigTimeoutTime_AGSM" SG_ 2654339160 CurrentFailSts_FD16_MCPA 0;
BA_ "GenSigTimeoutTime_MCPA" SG_ 2654339160 CurrentFailSts_FD16_MCPA 0;
BA_ "GenSigTimeoutTime_MCPB" SG_ 2654339160 CurrentFailSts_FD16_MCPA 0;
BA_ "GenSigTimeoutTime_ECM" SG_ 2654339160 GenericFailSts_FD16_MCPA 0;
BA_ "GenSigTimeoutTime_SGCP" SG_ 2654339160 GenericFailSts_FD16_MCPA 0;
BA_ "GenSigTimeoutTime_AGSM" SG_ 2654339160 GenericFailSts_FD16_MCPA 0;
BA_ "GenSigTimeoutTime_MCPA" SG_ 2654339160 GenericFailSts_FD16_MCPA 0;
BA_ "GenSigTimeoutTime_MCPB" SG_ 2654339160 GenericFailSts_FD16_MCPA 0;
BA_ "GenSigTimeoutTime_ECM" SG_ 2654339161 CurrentFailSts_FD16_MCPB 0;
BA_ "GenSigTimeoutTime_SGCP" SG_ 2654339161 CurrentFailSts_FD16_MCPB 0;
BA_ "GenSigTimeoutTime_AGSM" SG_ 2654339161 CurrentFailSts_FD16_MCPB 0;
BA_ "GenSigTimeoutTime_MCPA" SG_ 2654339161 CurrentFailSts_FD16_MCPB 0;
BA_ "GenSigTimeoutTime_MCPB" SG_ 2654339161 CurrentFailSts_FD16_MCPB 0;
BA_ "GenSigTimeoutTime_ECM" SG_ 2651930825 Digit_11_SGCP 0;
BA_ "GenSigTimeoutTime_SGCP" SG_ 2651930825 Digit_11_SGCP 0;
BA_ "GenSigTimeoutTime_AGSM" SG_ 2651930825 Digit_11_SGCP 0;
BA_ "GenSigTimeoutTime_MCPA" SG_ 2651930825 Digit_11_SGCP 0;
BA_ "GenSigTimeoutTime_MCPB" SG_ 2651930825 Digit_11_SGCP 0;
BA_ "GenSigTimeoutTime_ECM" SG_ 2651930825 Digit_10_SGCP 0;
BA_ "GenSigTimeoutTime_SGCP" SG_ 2651930825 Digit_10_SGCP 0;
BA_ "GenSigTimeoutTime_AGSM" SG_ 2651930825 Digit_10_SGCP 0;
BA_ "GenSigTimeoutTime_MCPA" SG_ 2651930825 Digit_10_SGCP 0;
BA_ "GenSigTimeoutTime_MCPB" SG_ 2651930825 Digit_10_SGCP 0;
BA_ "GenSigTimeoutTime_ECM" SG_ 2651930825 Digit_08_SGCP 0;
BA_ "GenSigTimeoutTime_SGCP" SG_ 2651930825 Digit_08_SGCP 0;
BA_ "GenSigTimeoutTime_AGSM" SG_ 2651930825 Digit_08_SGCP 0;
BA_ "GenSigTimeoutTime_MCPA" SG_ 2651930825 Digit_08_SGCP 0;
BA_ "GenSigTimeoutTime_MCPB" SG_ 2651930825 Digit_08_SGCP 0;
BA_ "GenSigTimeoutTime_ECM" SG_ 2651930825 Digit_09_SGCP 0;
BA_ "GenSigTimeoutTime_SGCP" SG_ 2651930825 Digit_09_SGCP 0;
BA_ "GenSigTimeoutTime_AGSM" SG_ 2651930825 Digit_09_SGCP 0;
BA_ "GenSigTimeoutTime_MCPA" SG_ 2651930825 Digit_09_SGCP 0;
BA_ "GenSigTimeoutTime_MCPB" SG_ 2651930825 Digit_09_SGCP 0;
BA_ "GenSigTimeoutTime_ECM" SG_ 2651930825 Digit_04_SGCP 0;
BA_ "GenSigTimeoutTime_SGCP" SG_ 2651930825 Digit_04_SGCP 0;
BA_ "GenSigTimeoutTime_AGSM" SG_ 2651930825 Digit_04_SGCP 0;
BA_ "GenSigTimeoutTime_MCPA" SG_ 2651930825 Digit_04_SGCP 0;
BA_ "GenSigTimeoutTime_MCPB" SG_ 2651930825 Digit_04_SGCP 0;
BA_ "GenSigTimeoutTime_ECM" SG_ 2651930825 Digit_05_SGCP 0;
BA_ "GenSigTimeoutTime_SGCP" SG_ 2651930825 Digit_05_SGCP 0;
BA_ "GenSigTimeoutTime_AGSM" SG_ 2651930825 Digit_05_SGCP 0;
BA_ "GenSigTimeoutTime_MCPA" SG_ 2651930825 Digit_05_SGCP 0;
BA_ "GenSigTimeoutTime_MCPB" SG_ 2651930825 Digit_05_SGCP 0;
BA_ "GenSigTimeoutTime_ECM" SG_ 2651930825 Digit_06_SGCP 0;
BA_ "GenSigTimeoutTime_SGCP" SG_ 2651930825 Digit_06_SGCP 0;
BA_ "GenSigTimeoutTime_AGSM" SG_ 2651930825 Digit_06_SGCP 0;
BA_ "GenSigTimeoutTime_MCPA" SG_ 2651930825 Digit_06_SGCP 0;
BA_ "GenSigTimeoutTime_MCPB" SG_ 2651930825 Digit_06_SGCP 0;
BA_ "GenSigTimeoutTime_ECM" SG_ 2651930825 Digit_07_SGCP 0;
BA_ "GenSigTimeoutTime_SGCP" SG_ 2651930825 Digit_07_SGCP 0;
BA_ "GenSigTimeoutTime_AGSM" SG_ 2651930825 Digit_07_SGCP 0;
BA_ "GenSigTimeoutTime_MCPA" SG_ 2651930825 Digit_07_SGCP 0;
BA_ "GenSigTimeoutTime_MCPB" SG_ 2651930825 Digit_07_SGCP 0;
BA_ "GenSigTimeoutTime_ECM" SG_ 2654339273 EOL_FD16_SGCP 0;
BA_ "GenSigTimeoutTime_SGCP" SG_ 2654339273 EOL_FD16_SGCP 0;
BA_ "GenSigTimeoutTime_AGSM" SG_ 2654339273 EOL_FD16_SGCP 0;
BA_ "GenSigTimeoutTime_MCPA" SG_ 2654339273 EOL_FD16_SGCP 0;
BA_ "GenSigTimeoutTime_MCPB" SG_ 2654339273 EOL_FD16_SGCP 0;
BA_ "GenSigTimeoutTime_ECM" SG_ 2654339273 GenericFailSts_FD16_SGCP 0;
BA_ "GenSigTimeoutTime_SGCP" SG_ 2654339273 GenericFailSts_FD16_SGCP 0;
BA_ "GenSigTimeoutTime_AGSM" SG_ 2654339273 GenericFailSts_FD16_SGCP 0;
BA_ "GenSigTimeoutTime_MCPA" SG_ 2654339273 GenericFailSts_FD16_SGCP 0;
BA_ "GenSigTimeoutTime_MCPB" SG_ 2654339273 GenericFailSts_FD16_SGCP 0;
BA_ "GenSigTimeoutTime_ECM" SG_ 2654339160 EOL_FD16_MCPA 0;
BA_ "GenSigTimeoutTime_SGCP" SG_ 2654339160 EOL_FD16_MCPA 0;
BA_ "GenSigTimeoutTime_AGSM" SG_ 2654339160 EOL_FD16_MCPA 0;
BA_ "GenSigTimeoutTime_MCPA" SG_ 2654339160 EOL_FD16_MCPA 0;
BA_ "GenSigTimeoutTime_MCPB" SG_ 2654339160 EOL_FD16_MCPA 0;
BA_ "GenSigTimeoutTime_ECM" SG_ 2654339161 EOL_FD16_MCPB 0;
BA_ "GenSigTimeoutTime_SGCP" SG_ 2654339161 EOL_FD16_MCPB 0;
BA_ "GenSigTimeoutTime_AGSM" SG_ 2654339161 EOL_FD16_MCPB 0;
BA_ "GenSigTimeoutTime_MCPA" SG_ 2654339161 EOL_FD16_MCPB 0;
BA_ "GenSigTimeoutTime_MCPB" SG_ 2654339161 EOL_FD16_MCPB 0;
BA_ "GenSigTimeoutTime_ECM" SG_ 2654339273 CurrentFailSts_FD16_SGCP 0;
BA_ "GenSigTimeoutTime_SGCP" SG_ 2654339273 CurrentFailSts_FD16_SGCP 0;
BA_ "GenSigTimeoutTime_AGSM" SG_ 2654339273 CurrentFailSts_FD16_SGCP 0;
BA_ "GenSigTimeoutTime_MCPA" SG_ 2654339273 CurrentFailSts_FD16_SGCP 0;
BA_ "GenSigTimeoutTime_MCPB" SG_ 2654339273 CurrentFailSts_FD16_SGCP 0;
BA_ "GenSigTimeoutTime_ECM" SG_ 2651930712 Digit_01_MCPA 0;
BA_ "GenSigTimeoutTime_SGCP" SG_ 2651930712 Digit_01_MCPA 0;
BA_ "GenSigSendType" SG_ 2651930712 Digit_01_MCPA 1;
BA_ "GenSigTimeoutTime_AGSM" SG_ 2651930712 Digit_01_MCPA 0;
BA_ "GenSigTimeoutTime_MCPA" SG_ 2651930712 Digit_01_MCPA 0;
BA_ "GenSigTimeoutTime_MCPB" SG_ 2651930712 Digit_01_MCPA 0;
BA_ "GenSigTimeoutTime_ECM" SG_ 2651930712 Digit_02_MCPA 0;
BA_ "GenSigTimeoutTime_SGCP" SG_ 2651930712 Digit_02_MCPA 0;
BA_ "GenSigTimeoutTime_AGSM" SG_ 2651930712 Digit_02_MCPA 0;
BA_ "GenSigTimeoutTime_MCPA" SG_ 2651930712 Digit_02_MCPA 0;
BA_ "GenSigTimeoutTime_MCPB" SG_ 2651930712 Digit_02_MCPA 0;
BA_ "GenSigTimeoutTime_ECM" SG_ 2651930712 Digit_03_MCPA 0;
BA_ "GenSigTimeoutTime_SGCP" SG_ 2651930712 Digit_03_MCPA 0;
BA_ "GenSigTimeoutTime_AGSM" SG_ 2651930712 Digit_03_MCPA 0;
BA_ "GenSigTimeoutTime_MCPA" SG_ 2651930712 Digit_03_MCPA 0;
BA_ "GenSigTimeoutTime_MCPB" SG_ 2651930712 Digit_03_MCPA 0;
BA_ "GenSigTimeoutTime_ECM" SG_ 2651930712 Digit_04_MCPA 0;
BA_ "GenSigTimeoutTime_SGCP" SG_ 2651930712 Digit_04_MCPA 0;
BA_ "GenSigTimeoutTime_AGSM" SG_ 2651930712 Digit_04_MCPA 0;
BA_ "GenSigTimeoutTime_MCPA" SG_ 2651930712 Digit_04_MCPA 0;
BA_ "GenSigTimeoutTime_MCPB" SG_ 2651930712 Digit_04_MCPA 0;
BA_ "GenSigTimeoutTime_ECM" SG_ 2651930712 Digit_05_MCPA 0;
BA_ "GenSigTimeoutTime_SGCP" SG_ 2651930712 Digit_05_MCPA 0;
BA_ "GenSigTimeoutTime_AGSM" SG_ 2651930712 Digit_05_MCPA 0;
BA_ "GenSigTimeoutTime_MCPA" SG_ 2651930712 Digit_05_MCPA 0;
BA_ "GenSigTimeoutTime_MCPB" SG_ 2651930712 Digit_05_MCPA 0;
BA_ "GenSigTimeoutTime_ECM" SG_ 2651930712 Digit_06_MCPA 0;
BA_ "GenSigTimeoutTime_SGCP" SG_ 2651930712 Digit_06_MCPA 0;
BA_ "GenSigTimeoutTime_AGSM" SG_ 2651930712 Digit_06_MCPA 0;
BA_ "GenSigTimeoutTime_MCPA" SG_ 2651930712 Digit_06_MCPA 0;
BA_ "GenSigTimeoutTime_MCPB" SG_ 2651930712 Digit_06_MCPA 0;
BA_ "GenSigTimeoutTime_ECM" SG_ 2651930712 Digit_07_MCPA 0;
BA_ "GenSigTimeoutTime_SGCP" SG_ 2651930712 Digit_07_MCPA 0;
BA_ "GenSigTimeoutTime_AGSM" SG_ 2651930712 Digit_07_MCPA 0;
BA_ "GenSigTimeoutTime_MCPA" SG_ 2651930712 Digit_07_MCPA 0;
BA_ "GenSigTimeoutTime_MCPB" SG_ 2651930712 Digit_07_MCPA 0;
BA_ "GenSigTimeoutTime_ECM" SG_ 2651930712 Digit_08_MCPA 0;
BA_ "GenSigTimeoutTime_SGCP" SG_ 2651930712 Digit_08_MCPA 0;
BA_ "GenSigTimeoutTime_AGSM" SG_ 2651930712 Digit_08_MCPA 0;
BA_ "GenSigTimeoutTime_MCPA" SG_ 2651930712 Digit_08_MCPA 0;
BA_ "GenSigTimeoutTime_MCPB" SG_ 2651930712 Digit_08_MCPA 0;
BA_ "GenSigTimeoutTime_ECM" SG_ 2651930712 Digit_09_MCPA 0;
BA_ "GenSigTimeoutTime_SGCP" SG_ 2651930712 Digit_09_MCPA 0;
BA_ "GenSigTimeoutTime_AGSM" SG_ 2651930712 Digit_09_MCPA 0;
BA_ "GenSigTimeoutTime_MCPA" SG_ 2651930712 Digit_09_MCPA 0;
BA_ "GenSigTimeoutTime_MCPB" SG_ 2651930712 Digit_09_MCPA 0;
BA_ "GenSigTimeoutTime_ECM" SG_ 2651930712 Digit_10_MCPA 0;
BA_ "GenSigTimeoutTime_SGCP" SG_ 2651930712 Digit_10_MCPA 0;
BA_ "GenSigTimeoutTime_AGSM" SG_ 2651930712 Digit_10_MCPA 0;
BA_ "GenSigTimeoutTime_MCPA" SG_ 2651930712 Digit_10_MCPA 0;
BA_ "GenSigTimeoutTime_MCPB" SG_ 2651930712 Digit_10_MCPA 0;
BA_ "GenSigTimeoutTime_ECM" SG_ 2651930712 Digit_11_MCPA 0;
BA_ "GenSigTimeoutTime_SGCP" SG_ 2651930712 Digit_11_MCPA 0;
BA_ "GenSigTimeoutTime_AGSM" SG_ 2651930712 Digit_11_MCPA 0;
BA_ "GenSigTimeoutTime_MCPA" SG_ 2651930712 Digit_11_MCPA 0;
BA_ "GenSigTimeoutTime_MCPB" SG_ 2651930712 Digit_11_MCPA 0;
BA_ "GenSigTimeoutTime_ECM" SG_ 2651930713 Digit_01_MCPB 0;
BA_ "GenSigTimeoutTime_SGCP" SG_ 2651930713 Digit_01_MCPB 0;
BA_ "GenSigSendType" SG_ 2651930713 Digit_01_MCPB 1;
BA_ "GenSigTimeoutTime_AGSM" SG_ 2651930713 Digit_01_MCPB 0;
BA_ "GenSigTimeoutTime_MCPA" SG_ 2651930713 Digit_01_MCPB 0;
BA_ "GenSigTimeoutTime_MCPB" SG_ 2651930713 Digit_01_MCPB 0;
BA_ "GenSigTimeoutTime_ECM" SG_ 2651930713 Digit_02_MCPB 0;
BA_ "GenSigTimeoutTime_SGCP" SG_ 2651930713 Digit_02_MCPB 0;
BA_ "GenSigTimeoutTime_AGSM" SG_ 2651930713 Digit_02_MCPB 0;
BA_ "GenSigTimeoutTime_MCPA" SG_ 2651930713 Digit_02_MCPB 0;
BA_ "GenSigTimeoutTime_MCPB" SG_ 2651930713 Digit_02_MCPB 0;
BA_ "GenSigTimeoutTime_ECM" SG_ 2651930713 Digit_03_MCPB 0;
BA_ "GenSigTimeoutTime_SGCP" SG_ 2651930713 Digit_03_MCPB 0;
BA_ "GenSigTimeoutTime_AGSM" SG_ 2651930713 Digit_03_MCPB 0;
BA_ "GenSigTimeoutTime_MCPA" SG_ 2651930713 Digit_03_MCPB 0;
BA_ "GenSigTimeoutTime_MCPB" SG_ 2651930713 Digit_03_MCPB 0;
BA_ "GenSigTimeoutTime_ECM" SG_ 2651930713 Digit_04_MCPB 0;
BA_ "GenSigTimeoutTime_SGCP" SG_ 2651930713 Digit_04_MCPB 0;
BA_ "GenSigTimeoutTime_AGSM" SG_ 2651930713 Digit_04_MCPB 0;
BA_ "GenSigTimeoutTime_MCPA" SG_ 2651930713 Digit_04_MCPB 0;
BA_ "GenSigTimeoutTime_MCPB" SG_ 2651930713 Digit_04_MCPB 0;
BA_ "GenSigTimeoutTime_ECM" SG_ 2651930713 Digit_05_MCPB 0;
BA_ "GenSigTimeoutTime_SGCP" SG_ 2651930713 Digit_05_MCPB 0;
BA_ "GenSigTimeoutTime_AGSM" SG_ 2651930713 Digit_05_MCPB 0;
BA_ "GenSigTimeoutTime_MCPA" SG_ 2651930713 Digit_05_MCPB 0;
BA_ "GenSigTimeoutTime_MCPB" SG_ 2651930713 Digit_05_MCPB 0;
BA_ "GenSigTimeoutTime_ECM" SG_ 2651930713 Digit_06_MCPB 0;
BA_ "GenSigTimeoutTime_SGCP" SG_ 2651930713 Digit_06_MCPB 0;
BA_ "GenSigTimeoutTime_AGSM" SG_ 2651930713 Digit_06_MCPB 0;
BA_ "GenSigTimeoutTime_MCPA" SG_ 2651930713 Digit_06_MCPB 0;
BA_ "GenSigTimeoutTime_MCPB" SG_ 2651930713 Digit_06_MCPB 0;
BA_ "GenSigTimeoutTime_ECM" SG_ 2651930713 Digit_07_MCPB 0;
BA_ "GenSigTimeoutTime_SGCP" SG_ 2651930713 Digit_07_MCPB 0;
BA_ "GenSigTimeoutTime_AGSM" SG_ 2651930713 Digit_07_MCPB 0;
BA_ "GenSigTimeoutTime_MCPA" SG_ 2651930713 Digit_07_MCPB 0;
BA_ "GenSigTimeoutTime_MCPB" SG_ 2651930713 Digit_07_MCPB 0;
BA_ "GenSigTimeoutTime_ECM" SG_ 2651930713 Digit_08_MCPB 0;
BA_ "GenSigTimeoutTime_SGCP" SG_ 2651930713 Digit_08_MCPB 0;
BA_ "GenSigTimeoutTime_AGSM" SG_ 2651930713 Digit_08_MCPB 0;
BA_ "GenSigTimeoutTime_MCPA" SG_ 2651930713 Digit_08_MCPB 0;
BA_ "GenSigTimeoutTime_MCPB" SG_ 2651930713 Digit_08_MCPB 0;
BA_ "GenSigTimeoutTime_ECM" SG_ 2651930713 Digit_09_MCPB 0;
BA_ "GenSigTimeoutTime_SGCP" SG_ 2651930713 Digit_09_MCPB 0;
BA_ "GenSigTimeoutTime_AGSM" SG_ 2651930713 Digit_09_MCPB 0;
BA_ "GenSigTimeoutTime_MCPA" SG_ 2651930713 Digit_09_MCPB 0;
BA_ "GenSigTimeoutTime_MCPB" SG_ 2651930713 Digit_09_MCPB 0;
BA_ "GenSigTimeoutTime_ECM" SG_ 2651930713 Digit_10_MCPB 0;
BA_ "GenSigTimeoutTime_SGCP" SG_ 2651930713 Digit_10_MCPB 0;
BA_ "GenSigTimeoutTime_AGSM" SG_ 2651930713 Digit_10_MCPB 0;
BA_ "GenSigTimeoutTime_MCPA" SG_ 2651930713 Digit_10_MCPB 0;
BA_ "GenSigTimeoutTime_MCPB" SG_ 2651930713 Digit_10_MCPB 0;
BA_ "GenSigTimeoutTime_ECM" SG_ 2651930713 Digit_11_MCPB 0;
BA_ "GenSigTimeoutTime_SGCP" SG_ 2651930713 Digit_11_MCPB 0;
BA_ "GenSigTimeoutTime_AGSM" SG_ 2651930713 Digit_11_MCPB 0;
BA_ "GenSigTimeoutTime_MCPA" SG_ 2651930713 Digit_11_MCPB 0;
BA_ "GenSigTimeoutTime_MCPB" SG_ 2651930713 Digit_11_MCPB 0;
BA_ "GenSigTimeoutTime_ECM" SG_ 2654486729 SourceNodeIdentifier_1E3840C9 0;
BA_ "GenSigTimeoutTime_SGCP" SG_ 2654486729 SourceNodeIdentifier_1E3840C9 0;
BA_ "GenSigTimeoutTime_ECM" SG_ 1070 SGCP_DTC_Stat2 0;
BA_ "GenSigTimeoutTime_SGCP" SG_ 1070 SGCP_DTC_Stat2 0;
BA_ "GenSigTimeoutTime_AGSM" SG_ 1070 SGCP_DTC_Stat2 0;
BA_ "GenSigTimeoutTime_MCPA" SG_ 1070 SGCP_DTC_Stat2 0;
BA_ "GenSigTimeoutTime_MCPB" SG_ 1070 SGCP_DTC_Stat2 0;
BA_ "GenSigTimeoutTime_ECM" SG_ 2654486729 CBV_bit7_1E3840C9 0;
BA_ "GenSigTimeoutTime_SGCP" SG_ 2654486729 CBV_bit7_1E3840C9 0;
BA_ "GenSigTimeoutTime_AGSM" SG_ 2654486729 CBV_bit7_1E3840C9 0;
BA_ "GenSigTimeoutTime_EVCU2" SG_ 2654486729 CBV_bit7_1E3840C9 0;
BA_ "GenSigTimeoutTime_MCPA" SG_ 2654486729 CBV_bit7_1E3840C9 0;
BA_ "GenSigTimeoutTime_MCPB" SG_ 2654486729 CBV_bit7_1E3840C9 0;
BA_ "GenSigTimeoutTime_ECM" SG_ 2654486729 CBV_bit6_PartialNtwInfBit_1E3840C9 0;
BA_ "GenSigTimeoutTime_SGCP" SG_ 2654486729 CBV_bit6_PartialNtwInfBit_1E3840C9 0;
BA_ "GenSigTimeoutTime_AGSM" SG_ 2654486729 CBV_bit6_PartialNtwInfBit_1E3840C9 0;
BA_ "GenSigTimeoutTime_EVCU2" SG_ 2654486729 CBV_bit6_PartialNtwInfBit_1E3840C9 0;
BA_ "GenSigTimeoutTime_MCPA" SG_ 2654486729 CBV_bit6_PartialNtwInfBit_1E3840C9 0;
BA_ "GenSigTimeoutTime_MCPB" SG_ 2654486729 CBV_bit6_PartialNtwInfBit_1E3840C9 0;
BA_ "GenSigTimeoutTime_ECM" SG_ 2654486729 CBV_bit5_1E3840C9 0;
BA_ "GenSigTimeoutTime_SGCP" SG_ 2654486729 CBV_bit5_1E3840C9 0;
BA_ "GenSigTimeoutTime_AGSM" SG_ 2654486729 CBV_bit5_1E3840C9 0;
BA_ "GenSigTimeoutTime_EVCU2" SG_ 2654486729 CBV_bit5_1E3840C9 0;
BA_ "GenSigTimeoutTime_MCPA" SG_ 2654486729 CBV_bit5_1E3840C9 0;
BA_ "GenSigTimeoutTime_MCPB" SG_ 2654486729 CBV_bit5_1E3840C9 0;
BA_ "GenSigTimeoutTime_ECM" SG_ 2654486729 CBV_bit4_ActiveWakeupBit_1E3840C9 0;
BA_ "GenSigTimeoutTime_SGCP" SG_ 2654486729 CBV_bit4_ActiveWakeupBit_1E3840C9 0;
BA_ "GenSigTimeoutTime_AGSM" SG_ 2654486729 CBV_bit4_ActiveWakeupBit_1E3840C9 0;
BA_ "GenSigTimeoutTime_EVCU2" SG_ 2654486729 CBV_bit4_ActiveWakeupBit_1E3840C9 0;
BA_ "GenSigTimeoutTime_MCPA" SG_ 2654486729 CBV_bit4_ActiveWakeupBit_1E3840C9 0;
BA_ "GenSigTimeoutTime_MCPB" SG_ 2654486729 CBV_bit4_ActiveWakeupBit_1E3840C9 0;
BA_ "GenSigTimeoutTime_MCPB" SG_ 2654486729 CBV_bit3_NMCoordinatorBit_1E3840C9 0;
BA_ "GenSigTimeoutTime_ECM" SG_ 2654486729 CBV_bit3_NMCoordinatorBit_1E3840C9 0;
BA_ "GenSigTimeoutTime_SGCP" SG_ 2654486729 CBV_bit3_NMCoordinatorBit_1E3840C9 0;
BA_ "GenSigTimeoutTime_AGSM" SG_ 2654486729 CBV_bit3_NMCoordinatorBit_1E3840C9 0;
BA_ "GenSigTimeoutTime_EVCU2" SG_ 2654486729 CBV_bit3_NMCoordinatorBit_1E3840C9 0;
BA_ "GenSigTimeoutTime_MCPA" SG_ 2654486729 CBV_bit3_NMCoordinatorBit_1E3840C9 0;
BA_ "GenSigTimeoutTime_ECM" SG_ 2654486729 CBV_bit2_1E3840C9 0;
BA_ "GenSigTimeoutTime_SGCP" SG_ 2654486729 CBV_bit2_1E3840C9 0;
BA_ "GenSigTimeoutTime_AGSM" SG_ 2654486729 CBV_bit2_1E3840C9 0;
BA_ "GenSigTimeoutTime_EVCU2" SG_ 2654486729 CBV_bit2_1E3840C9 0;
BA_ "GenSigTimeoutTime_MCPA" SG_ 2654486729 CBV_bit2_1E3840C9 0;
BA_ "GenSigTimeoutTime_MCPB" SG_ 2654486729 CBV_bit2_1E3840C9 0;
BA_ "GenSigTimeoutTime_ECM" SG_ 2654486729 CBV_bit1_1E3840C9 0;
BA_ "GenSigTimeoutTime_SGCP" SG_ 2654486729 CBV_bit1_1E3840C9 0;
BA_ "GenSigTimeoutTime_AGSM" SG_ 2654486729 CBV_bit1_1E3840C9 0;
BA_ "GenSigTimeoutTime_EVCU2" SG_ 2654486729 CBV_bit1_1E3840C9 0;
BA_ "GenSigTimeoutTime_MCPA" SG_ 2654486729 CBV_bit1_1E3840C9 0;
BA_ "GenSigTimeoutTime_MCPB" SG_ 2654486729 CBV_bit1_1E3840C9 0;
BA_ "GenSigTimeoutTime_ECM" SG_ 2654486729 CBV_bit0_RepeatMessageRequestBit_1E3840C9 0;
BA_ "GenSigTimeoutTime_SGCP" SG_ 2654486729 CBV_bit0_RepeatMessageRequestBit_1E3840C9 0;
BA_ "GenSigTimeoutTime_AGSM" SG_ 2654486729 CBV_bit0_RepeatMessageRequestBit_1E3840C9 0;
BA_ "GenSigTimeoutTime_EVCU2" SG_ 2654486729 CBV_bit0_RepeatMessageRequestBit_1E3840C9 0;
BA_ "GenSigTimeoutTime_MCPA" SG_ 2654486729 CBV_bit0_RepeatMessageRequestBit_1E3840C9 0;
BA_ "GenSigTimeoutTime_MCPB" SG_ 2654486729 CBV_bit0_RepeatMessageRequestBit_1E3840C9 0;
BA_ "GenSigTimeoutTime_ECM" SG_ 1070 CRC_SGCP_OBD_DTC 0;
BA_ "GenSigTimeoutTime_SGCP" SG_ 1070 CRC_SGCP_OBD_DTC 0;
BA_ "GenSigTimeoutTime_AGSM" SG_ 1070 CRC_SGCP_OBD_DTC 0;
BA_ "GenSigTimeoutTime_MCPA" SG_ 1070 CRC_SGCP_OBD_DTC 0;
BA_ "GenSigTimeoutTime_MCPB" SG_ 1070 CRC_SGCP_OBD_DTC 0;
BA_ "GenSigTimeoutTime_ECM" SG_ 1070 MessageCounter_SGCP_OBD_DTC 0;
BA_ "GenSigTimeoutTime_SGCP" SG_ 1070 MessageCounter_SGCP_OBD_DTC 0;
BA_ "GenSigTimeoutTime_AGSM" SG_ 1070 MessageCounter_SGCP_OBD_DTC 0;
BA_ "GenSigTimeoutTime_MCPA" SG_ 1070 MessageCounter_SGCP_OBD_DTC 0;
BA_ "GenSigTimeoutTime_MCPB" SG_ 1070 MessageCounter_SGCP_OBD_DTC 0;
BA_ "GenSigTimeoutTime_ECM" SG_ 1070 SGCP_Cal_ID_Idx 0;
BA_ "GenSigTimeoutTime_SGCP" SG_ 1070 SGCP_Cal_ID_Idx 0;
BA_ "GenSigTimeoutTime_AGSM" SG_ 1070 SGCP_Cal_ID_Idx 0;
BA_ "GenSigTimeoutTime_MCPA" SG_ 1070 SGCP_Cal_ID_Idx 0;
BA_ "GenSigTimeoutTime_MCPB" SG_ 1070 SGCP_Cal_ID_Idx 0;
BA_ "GenSigTimeoutTime_ECM" SG_ 1070 SGCP_CalChar 0;
BA_ "GenSigTimeoutTime_SGCP" SG_ 1070 SGCP_CalChar 0;
BA_ "GenSigTimeoutTime_AGSM" SG_ 1070 SGCP_CalChar 0;
BA_ "GenSigTimeoutTime_MCPA" SG_ 1070 SGCP_CalChar 0;
BA_ "GenSigTimeoutTime_MCPB" SG_ 1070 SGCP_CalChar 0;
BA_ "GenSigTimeoutTime_ECM" SG_ 1070 SGCP_DTC_Idx1 0;
BA_ "GenSigTimeoutTime_SGCP" SG_ 1070 SGCP_DTC_Idx1 0;
BA_ "GenSigTimeoutTime_AGSM" SG_ 1070 SGCP_DTC_Idx1 0;
BA_ "GenSigTimeoutTime_MCPA" SG_ 1070 SGCP_DTC_Idx1 0;
BA_ "GenSigTimeoutTime_MCPB" SG_ 1070 SGCP_DTC_Idx1 0;
BA_ "GenSigTimeoutTime_ECM" SG_ 1070 SGCP_DTC_Idx2 0;
BA_ "GenSigTimeoutTime_SGCP" SG_ 1070 SGCP_DTC_Idx2 0;
BA_ "GenSigTimeoutTime_AGSM" SG_ 1070 SGCP_DTC_Idx2 0;
BA_ "GenSigTimeoutTime_MCPA" SG_ 1070 SGCP_DTC_Idx2 0;
BA_ "GenSigTimeoutTime_MCPB" SG_ 1070 SGCP_DTC_Idx2 0;
BA_ "GenSigTimeoutTime_ECM" SG_ 1070 SGCP_DTC_Stat1 0;
BA_ "GenSigTimeoutTime_SGCP" SG_ 1070 SGCP_DTC_Stat1 0;
BA_ "GenSigTimeoutTime_AGSM" SG_ 1070 SGCP_DTC_Stat1 0;
BA_ "GenSigTimeoutTime_MCPA" SG_ 1070 SGCP_DTC_Stat1 0;
BA_ "GenSigTimeoutTime_MCPB" SG_ 1070 SGCP_DTC_Stat1 0;
BA_ "GenSigTimeoutTime_AGSM" SG_ 2654486729 SourceNodeIdentifier_1E3840C9 0;
BA_ "GenSigTimeoutTime_EVCU2" SG_ 2654486729 SourceNodeIdentifier_1E3840C9 0;
BA_ "GenSigTimeoutTime_MCPA" SG_ 2654486729 SourceNodeIdentifier_1E3840C9 0;
BA_ "GenSigTimeoutTime_MCPB" SG_ 2654486729 SourceNodeIdentifier_1E3840C9 0;
BA_ "GenSigTimeoutTime_ECM" SG_ 2564682261 N_PDU_18DDF215 0;
BA_ "GenSigTimeoutTime_SGCP" SG_ 2564682261 N_PDU_18DDF215 0;
BA_ "GenSigTimeoutTime_AGSM" SG_ 2564682261 N_PDU_18DDF215 0;
BA_ "GenSigTimeoutTime_EVCU2" SG_ 2564682261 N_PDU_18DDF215 0;
BA_ "GenSigTimeoutTime_MCPA" SG_ 2564682261 N_PDU_18DDF215 0;
BA_ "GenSigTimeoutTime_MCPB" SG_ 2564682261 N_PDU_18DDF215 0;
BA_ "GenSigTimeoutTime_ECM" SG_ 2564485653 N_PDU_18DAF215 0;
BA_ "GenSigTimeoutTime_SGCP" SG_ 2564485653 N_PDU_18DAF215 0;
BA_ "GenSigTimeoutTime_AGSM" SG_ 2564485653 N_PDU_18DAF215 0;
BA_ "GenSigTimeoutTime_EVCU2" SG_ 2564485653 N_PDU_18DAF215 0;
BA_ "GenSigTimeoutTime_MCPA" SG_ 2564485653 N_PDU_18DAF215 0;
BA_ "GenSigTimeoutTime_MCPB" SG_ 2564485653 N_PDU_18DAF215 0;
BA_ "GenSigTimeoutTime_ECM" SG_ 2564682260 N_PDU_18DDF214 0;
BA_ "GenSigTimeoutTime_SGCP" SG_ 2564682260 N_PDU_18DDF214 0;
BA_ "GenSigTimeoutTime_AGSM" SG_ 2564682260 N_PDU_18DDF214 0;
BA_ "GenSigTimeoutTime_EVCU2" SG_ 2564682260 N_PDU_18DDF214 0;
BA_ "GenSigTimeoutTime_MCPA" SG_ 2564682260 N_PDU_18DDF214 0;
BA_ "GenSigTimeoutTime_MCPB" SG_ 2564682260 N_PDU_18DDF214 0;
BA_ "GenSigTimeoutTime_ECM" SG_ 2564485652 N_PDU_18DAF214 0;
BA_ "GenSigTimeoutTime_SGCP" SG_ 2564485652 N_PDU_18DAF214 0;
BA_ "GenSigTimeoutTime_AGSM" SG_ 2564485652 N_PDU_18DAF214 0;
BA_ "GenSigTimeoutTime_EVCU2" SG_ 2564485652 N_PDU_18DAF214 0;
BA_ "GenSigTimeoutTime_MCPA" SG_ 2564485652 N_PDU_18DAF214 0;
BA_ "GenSigTimeoutTime_MCPB" SG_ 2564485652 N_PDU_18DAF214 0;
BA_ "GenSigTimeoutTime_ECM" SG_ 2564429042 N_PDU_18DA14F2 0;
BA_ "GenSigTimeoutTime_SGCP" SG_ 2564429042 N_PDU_18DA14F2 0;
BA_ "GenSigTimeoutTime_AGSM" SG_ 2564429042 N_PDU_18DA14F2 0;
BA_ "GenSigTimeoutTime_EVCU2" SG_ 2564429042 N_PDU_18DA14F2 0;
BA_ "GenSigTimeoutTime_MCPA" SG_ 2564429042 N_PDU_18DA14F2 0;
BA_ "GenSigTimeoutTime_MCPB" SG_ 2564429042 N_PDU_18DA14F2 0;
BA_ "GenSigTimeoutTime_ECM" SG_ 2564429298 N_PDU_18DA15F2 0;
BA_ "GenSigTimeoutTime_SGCP" SG_ 2564429298 N_PDU_18DA15F2 0;
BA_ "GenSigTimeoutTime_AGSM" SG_ 2564429298 N_PDU_18DA15F2 0;
BA_ "GenSigTimeoutTime_EVCU2" SG_ 2564429298 N_PDU_18DA15F2 0;
BA_ "GenSigTimeoutTime_MCPA" SG_ 2564429298 N_PDU_18DA15F2 0;
BA_ "GenSigTimeoutTime_MCPB" SG_ 2564429298 N_PDU_18DA15F2 0;
BA_ "GenSigTimeoutTime_ECM" SG_ 262 Engine_Stall_Detected 0;
BA_ "GenSigTimeoutTime_SGCP" SG_ 262 Engine_Stall_Detected 0;
BA_ "GenSigTimeoutTime_AGSM" SG_ 262 Engine_Stall_Detected 0;
BA_ "GenSigTimeoutTime_MCPA" SG_ 262 Engine_Stall_Detected 0;
BA_ "GenSigTimeoutTime_MCPB" SG_ 262 Engine_Stall_Detected 0;
BA_ "GenSigTimeoutTime_AGSM" SG_ 262 EssEngModReq 0;
BA_ "GenSigTimeoutTime_MCPA" SG_ 262 EssEngModReq 0;
BA_ "GenSigTimeoutTime_MCPB" SG_ 262 EssEngModReq 0;
BA_ "GenSigTimeoutTime_ECM" SG_ 262 EssEngModReq 0;
BA_ "GenSigTimeoutTime_SGCP" SG_ 262 EssEngModReq 0;
BA_ "GenSigTimeoutTime_ECM" SG_ 262 EssEngSt 0;
BA_ "GenSigTimeoutTime_SGCP" SG_ 262 EssEngSt 0;
BA_ "GenSigTimeoutTime_AGSM" SG_ 262 EssEngSt 0;
BA_ "GenSigTimeoutTime_MCPA" SG_ 262 EssEngSt 0;
BA_ "GenSigTimeoutTime_MCPB" SG_ 262 EssEngSt 0;
BA_ "GenSigTimeoutTime_ECM" SG_ 262 EssEngStopIsNotAllwd 0;
BA_ "GenSigTimeoutTime_SGCP" SG_ 262 EssEngStopIsNotAllwd 0;
BA_ "GenSigTimeoutTime_AGSM" SG_ 262 EssEngStopIsNotAllwd 0;
BA_ "GenSigTimeoutTime_MCPA" SG_ 262 EssEngStopIsNotAllwd 0;
BA_ "GenSigTimeoutTime_MCPB" SG_ 262 EssEngStopIsNotAllwd 0;
BA_ "GenSigTimeoutTime_ECM" SG_ 262 EssEngStrtIsNotAllwdID 0;
BA_ "GenSigTimeoutTime_SGCP" SG_ 262 EssEngStrtIsNotAllwdID 0;
BA_ "GenSigTimeoutTime_ECM" SG_ 262 EssEngStopIsNotAllwdID 0;
BA_ "GenSigTimeoutTime_SGCP" SG_ 262 EssEngStopIsNotAllwdID 0;
BA_ "GenSigTimeoutTime_AGSM" SG_ 262 EssEngStopIsNotAllwdID 0;
BA_ "GenSigTimeoutTime_MCPA" SG_ 262 EssEngStopIsNotAllwdID 0;
BA_ "GenSigTimeoutTime_MCPB" SG_ 262 EssEngStopIsNotAllwdID 0;
BA_ "GenSigTimeoutTime_ECM" SG_ 262 EssEngStrtIsNotAllwd 0;
BA_ "GenSigTimeoutTime_SGCP" SG_ 262 EssEngStrtIsNotAllwd 0;
BA_ "GenSigTimeoutTime_AGSM" SG_ 262 EssEngStrtIsNotAllwd 0;
BA_ "GenSigTimeoutTime_MCPA" SG_ 262 EssEngStrtIsNotAllwd 0;
BA_ "GenSigTimeoutTime_MCPB" SG_ 262 EssEngStrtIsNotAllwd 0;
BA_ "GenSigTimeoutTime_ECM" SG_ 2564682364 N_PDU_18DDF27C 0;
BA_ "GenSigTimeoutTime_SGCP" SG_ 2564682364 N_PDU_18DDF27C 0;
BA_ "GenSigTimeoutTime_AGSM" SG_ 2564682364 N_PDU_18DDF27C 0;
BA_ "GenSigTimeoutTime_EVCU2" SG_ 2564682364 N_PDU_18DDF27C 0;
BA_ "GenSigTimeoutTime_MCPA" SG_ 2564682364 N_PDU_18DDF27C 0;
BA_ "GenSigTimeoutTime_MCPB" SG_ 2564682364 N_PDU_18DDF27C 0;
BA_ "GenSigTimeoutTime_ECM" SG_ 2564455666 N_PDU_18DA7CF2 0;
BA_ "GenSigTimeoutTime_SGCP" SG_ 2564455666 N_PDU_18DA7CF2 0;
BA_ "GenSigTimeoutTime_AGSM" SG_ 2564455666 N_PDU_18DA7CF2 0;
BA_ "GenSigTimeoutTime_EVCU2" SG_ 2564455666 N_PDU_18DA7CF2 0;
BA_ "GenSigTimeoutTime_MCPA" SG_ 2564455666 N_PDU_18DA7CF2 0;
BA_ "GenSigTimeoutTime_MCPB" SG_ 2564455666 N_PDU_18DA7CF2 0;
BA_ "GenSigTimeoutTime_ECM" SG_ 2564485756 N_PDU_18DAF27C 0;
BA_ "GenSigTimeoutTime_SGCP" SG_ 2564485756 N_PDU_18DAF27C 0;
BA_ "GenSigTimeoutTime_AGSM" SG_ 2564485756 N_PDU_18DAF27C 0;
BA_ "GenSigTimeoutTime_EVCU2" SG_ 2564485756 N_PDU_18DAF27C 0;
BA_ "GenSigTimeoutTime_MCPA" SG_ 2564485756 N_PDU_18DAF27C 0;
BA_ "GenSigTimeoutTime_MCPB" SG_ 2564485756 N_PDU_18DAF27C 0;
BA_ "GenSigTimeoutTime_MRGB" SG_ 262 TRANS_CLU_SLIP_MODE_W 0;
BA_ "GenSigTimeoutTime_ECM" SG_ 262 TRANS_CLU_SLIP_MODE_W 0;
BA_ "GenSigTimeoutTime_AGSM" SG_ 262 TRANS_CLU_SLIP_MODE_W 0;
BA_ "GenSigTimeoutTime_EVCU2" SG_ 262 TRANS_CLU_SLIP_MODE_W 0;
BA_ "GenSigTimeoutTime_MCPA" SG_ 262 TRANS_CLU_SLIP_MODE_W 0;
BA_ "GenSigTimeoutTime_MCPB" SG_ 262 TRANS_CLU_SLIP_MODE_W 0;
BA_ "GenSigTimeoutTime_MRGB" SG_ 262 TxAC_EMCC_rq_W 0;
BA_ "GenSigTimeoutTime_ECM" SG_ 262 TxAC_EMCC_rq_W 0;
BA_ "GenSigTimeoutTime_AGSM" SG_ 262 TxAC_EMCC_rq_W 0;
BA_ "GenSigTimeoutTime_EVCU2" SG_ 262 TxAC_EMCC_rq_W 0;
BA_ "GenSigTimeoutTime_MCPA" SG_ 262 TxAC_EMCC_rq_W 0;
BA_ "GenSigTimeoutTime_MCPB" SG_ 262 TxAC_EMCC_rq_W 0;
BA_ "GenSigTimeoutTime_MRGB" SG_ 262 ESS_ENG_ST_W 0;
BA_ "GenSigTimeoutTime_ECM" SG_ 262 ESS_ENG_ST_W 0;
BA_ "GenSigTimeoutTime_SGCP" SG_ 262 ESS_ENG_ST_W 0;
BA_ "GenSigStartValue" SG_ 262 ESS_ENG_ST_W 15;
BA_ "GenSigSendType" SG_ 262 ESS_ENG_ST_W 3;
BA_ "GenSigTimeoutTime_AGSM" SG_ 262 ESS_ENG_ST_W 0;
BA_ "GenSigTimeoutTime_EVCU2" SG_ 262 ESS_ENG_ST_W 0;
BA_ "GenSigTimeoutTime_MCPA" SG_ 262 ESS_ENG_ST_W 0;
BA_ "GenSigTimeoutTime_MCPB" SG_ 262 ESS_ENG_ST_W 0;
BA_ "GenSigTimeoutTime_MRGB" SG_ 262 ESS_RqShftPark_W 0;
BA_ "GenSigTimeoutTime_TCM" SG_ 262 ESS_RqShftPark_W 0;
BA_ "GenSigTimeoutTime_ECM" SG_ 262 ESS_RqShftPark_W 0;
BA_ "GenSigTimeoutTime_AGSM" SG_ 262 ESS_RqShftPark_W 0;
BA_ "GenSigTimeoutTime_EVCU2" SG_ 262 ESS_RqShftPark_W 0;
BA_ "GenSigTimeoutTime_MCPA" SG_ 262 ESS_RqShftPark_W 0;
BA_ "GenSigTimeoutTime_MCPB" SG_ 262 ESS_RqShftPark_W 0;
BA_ "GenSigTimeoutTime_MRGB" SG_ 262 GasPedalPosition_W 0;
BA_ "GenSigTimeoutTime_ECM" SG_ 262 GasPedalPosition_W 0;
BA_ "GenSigTimeoutTime_AGSM" SG_ 262 GasPedalPosition_W 0;
BA_ "GenSigTimeoutTime_EVCU2" SG_ 262 GasPedalPosition_W 0;
BA_ "GenSigTimeoutTime_MCPA" SG_ 262 GasPedalPosition_W 0;
BA_ "GenSigTimeoutTime_MCPB" SG_ 262 GasPedalPosition_W 0;
BA_ "GenSigTimeoutTime_MRGB" SG_ 262 GasPedalPositionFailSts_W 0;
BA_ "GenSigTimeoutTime_ECM" SG_ 262 GasPedalPositionFailSts_W 0;
BA_ "GenSigTimeoutTime_AGSM" SG_ 262 GasPedalPositionFailSts_W 0;
BA_ "GenSigTimeoutTime_EVCU2" SG_ 262 GasPedalPositionFailSts_W 0;
BA_ "GenSigTimeoutTime_MCPA" SG_ 262 GasPedalPositionFailSts_W 0;
BA_ "GenSigTimeoutTime_MCPB" SG_ 262 GasPedalPositionFailSts_W 0;
BA_ "GenSigTimeoutTime_MRGB" SG_ 262 KickDownRequest_W 0;
BA_ "GenSigTimeoutTime_ECM" SG_ 262 KickDownRequest_W 0;
BA_ "GenSigTimeoutTime_SGCP" SG_ 262 KickDownRequest_W 0;
BA_ "GenSigTimeoutTime_AGSM" SG_ 262 KickDownRequest_W 0;
BA_ "GenSigTimeoutTime_EVCU2" SG_ 262 KickDownRequest_W 0;
BA_ "GenSigTimeoutTime_MCPA" SG_ 262 KickDownRequest_W 0;
BA_ "GenSigTimeoutTime_MCPB" SG_ 262 KickDownRequest_W 0;
BA_ "GenSigTimeoutTime_MRGB" SG_ 262 IntakeAirTemperature_W 0;
BA_ "GenSigTimeoutTime_ECM" SG_ 262 IntakeAirTemperature_W 0;
BA_ "GenSigTimeoutTime_SGCP" SG_ 262 IntakeAirTemperature_W 0;
BA_ "GenSigStartValue" SG_ 262 IntakeAirTemperature_W 65;
BA_ "GenSigTimeoutTime_AGSM" SG_ 262 IntakeAirTemperature_W 0;
BA_ "GenSigTimeoutTime_EVCU2" SG_ 262 IntakeAirTemperature_W 0;
BA_ "GenSigTimeoutTime_MCPA" SG_ 262 IntakeAirTemperature_W 0;
BA_ "GenSigTimeoutTime_MCPB" SG_ 262 IntakeAirTemperature_W 0;
BA_ "GenSigTimeoutTime_MRGB" SG_ 262 ESS_EBOOST_BRKHLD_STATUS 0;
BA_ "GenSigTimeoutTime_TCM" SG_ 262 ESS_EBOOST_BRKHLD_STATUS 0;
BA_ "GenSigTimeoutTime_ECM" SG_ 262 ESS_EBOOST_BRKHLD_STATUS 0;
BA_ "GenSigTimeoutTime_AGSM" SG_ 262 ESS_EBOOST_BRKHLD_STATUS 0;
BA_ "GenSigTimeoutTime_EVCU2" SG_ 262 ESS_EBOOST_BRKHLD_STATUS 0;
BA_ "GenSigTimeoutTime_MCPA" SG_ 262 ESS_EBOOST_BRKHLD_STATUS 0;
BA_ "GenSigTimeoutTime_MCPB" SG_ 262 ESS_EBOOST_BRKHLD_STATUS 0;
BA_ "GenSigTimeoutTime_MRGB" SG_ 262 EngineFrictionTorque_W 0;
BA_ "GenSigTimeoutTime_TCM" SG_ 262 EngineFrictionTorque_W 0;
BA_ "GenSigTimeoutTime_ECM" SG_ 262 EngineFrictionTorque_W 0;
BA_ "GenSigTimeoutTime_SGCP" SG_ 262 EngineFrictionTorque_W 0;
BA_ "GenSigTimeoutTime_AGSM" SG_ 262 EngineFrictionTorque_W 0;
BA_ "GenSigTimeoutTime_EVCU2" SG_ 262 EngineFrictionTorque_W 0;
BA_ "GenSigTimeoutTime_MCPA" SG_ 262 EngineFrictionTorque_W 0;
BA_ "GenSigTimeoutTime_MCPB" SG_ 262 EngineFrictionTorque_W 0;
BA_ "GenSigTimeoutTime_MRGB" SG_ 262 ECM_LHOM_Trans_W 0;
BA_ "GenSigTimeoutTime_ECM" SG_ 262 ECM_LHOM_Trans_W 0;
BA_ "GenSigTimeoutTime_SGCP" SG_ 262 ECM_LHOM_Trans_W 0;
BA_ "GenSigTimeoutTime_AGSM" SG_ 262 ECM_LHOM_Trans_W 0;
BA_ "GenSigTimeoutTime_EVCU2" SG_ 262 ECM_LHOM_Trans_W 0;
BA_ "GenSigTimeoutTime_MCPA" SG_ 262 ECM_LHOM_Trans_W 0;
BA_ "GenSigTimeoutTime_MCPB" SG_ 262 ECM_LHOM_Trans_W 0;
BA_ "GenSigTimeoutTime_MRGB" SG_ 262 ECM_LHOM_W 0;
BA_ "GenSigTimeoutTime_ECM" SG_ 262 ECM_LHOM_W 0;
BA_ "GenSigTimeoutTime_SGCP" SG_ 262 ECM_LHOM_W 0;
BA_ "GenSigTimeoutTime_AGSM" SG_ 262 ECM_LHOM_W 0;
BA_ "GenSigTimeoutTime_EVCU2" SG_ 262 ECM_LHOM_W 0;
BA_ "GenSigTimeoutTime_MCPA" SG_ 262 ECM_LHOM_W 0;
BA_ "GenSigTimeoutTime_MCPB" SG_ 262 ECM_LHOM_W 0;
BA_ "GenSigTimeoutTime_MRGB" SG_ 262 EngineIdleRefSpeed 0;
BA_ "GenSigTimeoutTime_ECM" SG_ 262 EngineIdleRefSpeed 0;
BA_ "GenSigTimeoutTime_SGCP" SG_ 262 EngineIdleRefSpeed 0;
BA_ "GenSigTimeoutTime_AGSM" SG_ 262 EngineIdleRefSpeed 0;
BA_ "GenSigTimeoutTime_EVCU2" SG_ 262 EngineIdleRefSpeed 0;
BA_ "GenSigTimeoutTime_MCPA" SG_ 262 EngineIdleRefSpeed 0;
BA_ "GenSigTimeoutTime_MCPB" SG_ 262 EngineIdleRefSpeed 0;
BA_ "GenSigTimeoutTime_MRGB" SG_ 262 CrankHold_W 0;
BA_ "GenSigTimeoutTime_TCM" SG_ 262 CrankHold_W 0;
BA_ "GenSigTimeoutTime_ECM" SG_ 262 CrankHold_W 0;
BA_ "GenSigTimeoutTime_AGSM" SG_ 262 CrankHold_W 0;
BA_ "GenSigTimeoutTime_EVCU2" SG_ 262 CrankHold_W 0;
BA_ "GenSigTimeoutTime_MCPA" SG_ 262 CrankHold_W 0;
BA_ "GenSigTimeoutTime_MCPB" SG_ 262 CrankHold_W 0;
BA_ "GenSigTimeoutTime_MRGB" SG_ 262 CRC_ENGINE2 0;
BA_ "GenSigTimeoutTime_ECM" SG_ 262 CRC_ENGINE2 0;
BA_ "GenSigTimeoutTime_SGCP" SG_ 262 CRC_ENGINE2 0;
BA_ "GenSigTimeoutTime_AGSM" SG_ 262 CRC_ENGINE2 0;
BA_ "GenSigTimeoutTime_EVCU2" SG_ 262 CRC_ENGINE2 0;
BA_ "GenSigTimeoutTime_MCPA" SG_ 262 CRC_ENGINE2 0;
BA_ "GenSigTimeoutTime_MCPB" SG_ 262 CRC_ENGINE2 0;
BA_ "GenSigTimeoutTime_MRGB" SG_ 262 Torque_Interface_Mask 0;
BA_ "GenSigTimeoutTime_ECM" SG_ 262 Torque_Interface_Mask 0;
BA_ "GenSigTimeoutTime_AGSM" SG_ 262 Torque_Interface_Mask 0;
BA_ "GenSigTimeoutTime_EVCU2" SG_ 262 Torque_Interface_Mask 0;
BA_ "GenSigTimeoutTime_MCPA" SG_ 262 Torque_Interface_Mask 0;
BA_ "GenSigTimeoutTime_MCPB" SG_ 262 Torque_Interface_Mask 0;
BA_ "GenSigTimeoutTime_ECM" SG_ 271 Sum_FW_ID_Slw 0;
BA_ "GenSigTimeoutTime_SGCP" SG_ 271 Sum_FW_ID_Slw 0;
BA_ "GenSigStartValue" SG_ 271 Sum_FW_ID_Slw 1;
BA_ "GenSigTimeoutTime_AGSM" SG_ 271 Sum_FW_ID_Slw 0;
BA_ "GenSigTimeoutTime_MCPA" SG_ 271 Sum_FW_ID_Slw 0;
BA_ "GenSigTimeoutTime_MCPB" SG_ 271 Sum_FW_ID_Slw 0;
BA_ "GenSigTimeoutTime_ECM" SG_ 271 MinPrdtdEngRunTorqCapV 0;
BA_ "GenSigTimeoutTime_SGCP" SG_ 271 MinPrdtdEngRunTorqCapV 0;
BA_ "GenSigTimeoutTime_AGSM" SG_ 271 MinPrdtdEngRunTorqCapV 0;
BA_ "GenSigTimeoutTime_MCPA" SG_ 271 MinPrdtdEngRunTorqCapV 0;
BA_ "GenSigTimeoutTime_MCPB" SG_ 271 MinPrdtdEngRunTorqCapV 0;
BA_ "GenSigTimeoutTime_ECM" SG_ 271 Sum_FW_ID_Fst 0;
BA_ "GenSigTimeoutTime_SGCP" SG_ 271 Sum_FW_ID_Fst 0;
BA_ "GenSigStartValue" SG_ 271 Sum_FW_ID_Fst 1;
BA_ "GenSigTimeoutTime_AGSM" SG_ 271 Sum_FW_ID_Fst 0;
BA_ "GenSigTimeoutTime_MCPA" SG_ 271 Sum_FW_ID_Fst 0;
BA_ "GenSigTimeoutTime_MCPB" SG_ 271 Sum_FW_ID_Fst 0;
BA_ "GenSigTimeoutTime_MRGB" SG_ 271 MinImmedEngTorqCapV 0;
BA_ "GenSigTimeoutTime_ECM" SG_ 271 MinImmedEngTorqCapV 0;
BA_ "GenSigTimeoutTime_SGCP" SG_ 271 MinImmedEngTorqCapV 0;
BA_ "GenSigTimeoutTime_AGSM" SG_ 271 MinImmedEngTorqCapV 0;
BA_ "GenSigTimeoutTime_EVCU2" SG_ 271 MinImmedEngTorqCapV 0;
BA_ "GenSigTimeoutTime_MCPA" SG_ 271 MinImmedEngTorqCapV 0;
BA_ "GenSigTimeoutTime_MCPB" SG_ 271 MinImmedEngTorqCapV 0;
BA_ "GenSigTimeoutTime_ECM" SG_ 271 MinPrdtdEngRunTorqCap 0;
BA_ "GenSigTimeoutTime_SGCP" SG_ 271 MinPrdtdEngRunTorqCap 0;
BA_ "GenSigStartValue" SG_ 271 MinPrdtdEngRunTorqCap 938;
BA_ "GenSigTimeoutTime_AGSM" SG_ 271 MinPrdtdEngRunTorqCap 0;
BA_ "GenSigTimeoutTime_MCPA" SG_ 271 MinPrdtdEngRunTorqCap 0;
BA_ "GenSigTimeoutTime_MCPB" SG_ 271 MinPrdtdEngRunTorqCap 0;
BA_ "GenSigTimeoutTime_AGSM" SG_ 271 MinImmedEngTorqCap 0;
BA_ "GenSigTimeoutTime_EVCU2" SG_ 271 MinImmedEngTorqCap 0;
BA_ "GenSigTimeoutTime_MCPA" SG_ 271 MinImmedEngTorqCap 0;
BA_ "GenSigTimeoutTime_MCPB" SG_ 271 MinImmedEngTorqCap 0;
BA_ "GenSigTimeoutTime_AGSM" SG_ 496 Plock_fdbk_sts 0;
BA_ "GenSigTimeoutTime_EVCU2" SG_ 496 Plock_fdbk_sts 0;
BA_ "GenSigTimeoutTime_MCPA" SG_ 496 Plock_fdbk_sts 0;
BA_ "GenSigTimeoutTime_MCPB" SG_ 496 Plock_fdbk_sts 0;
BA_ "GenSigTimeoutTime_MRGB" SG_ 216 BatteryVoltage_Raw_PT 0;
BA_ "GenSigTimeoutTime_TCM" SG_ 216 BatteryVoltage_Raw_PT 0;
BA_ "GenSigTimeoutTime_ECM" SG_ 216 BatteryVoltage_Raw_PT 0;
BA_ "GenSigTimeoutTime_SGCP" SG_ 216 BatteryVoltage_Raw_PT 0;
BA_ "GenSigTimeoutTime_AGSM" SG_ 216 BatteryVoltage_Raw_PT 0;
BA_ "GenSigTimeoutTime_EVCU2" SG_ 216 BatteryVoltage_Raw_PT 0;
BA_ "GenSigTimeoutTime_AGSM" SG_ 2564485396 N_PDU_18DAF114 0;
BA_ "GenSigTimeoutTime_EVCU2" SG_ 2564485396 N_PDU_18DAF114 0;
BA_ "GenSigTimeoutTime_MCPA" SG_ 2564485396 N_PDU_18DAF114 0;
BA_ "GenSigTimeoutTime_MCPB" SG_ 2564485396 N_PDU_18DAF114 0;
BA_ "GenSigTimeoutTime_MRGB" SG_ 496 CRC_PARK_DATA 0;
BA_ "GenSigTimeoutTime_TCM" SG_ 496 CRC_PARK_DATA 0;
BA_ "GenSigTimeoutTime_ECM" SG_ 496 CRC_PARK_DATA 0;
BA_ "GenSigTimeoutTime_AGSM" SG_ 496 CRC_PARK_DATA 0;
BA_ "GenSigTimeoutTime_MCPA" SG_ 496 CRC_PARK_DATA 0;
BA_ "GenSigTimeoutTime_MCPB" SG_ 496 CRC_PARK_DATA 0;
BA_ "GenSigTimeoutTime_MRGB" SG_ 496 MessageCounter_PARK_DATA 0;
BA_ "GenSigTimeoutTime_TCM" SG_ 496 MessageCounter_PARK_DATA 0;
BA_ "GenSigTimeoutTime_ECM" SG_ 496 MessageCounter_PARK_DATA 0;
BA_ "GenSigTimeoutTime_AGSM" SG_ 496 MessageCounter_PARK_DATA 0;
BA_ "GenSigTimeoutTime_MCPA" SG_ 496 MessageCounter_PARK_DATA 0;
BA_ "GenSigTimeoutTime_MCPB" SG_ 496 MessageCounter_PARK_DATA 0;
BA_ "GenSigTimeoutTime_AGSM" SG_ 2564429297 N_PDU_18DA15F1 0;
BA_ "GenSigTimeoutTime_EVCU2" SG_ 2564429297 N_PDU_18DA15F1 0;
BA_ "GenSigTimeoutTime_MCPA" SG_ 2564429297 N_PDU_18DA15F1 0;
BA_ "GenSigTimeoutTime_MCPB" SG_ 2564429297 N_PDU_18DA15F1 0;
BA_ "GenSigTimeoutTime_MRGB" SG_ 1057 MessageCounter_MCPA_OBD_DTC 0;
BA_ "GenSigTimeoutTime_TCM" SG_ 1057 MessageCounter_MCPA_OBD_DTC 0;
BA_ "GenSigTimeoutTime_ECM" SG_ 1057 MessageCounter_MCPA_OBD_DTC 0;
BA_ "GenSigTimeoutTime_SGCP" SG_ 1057 MessageCounter_MCPA_OBD_DTC 0;
BA_ "GenSigTimeoutTime_AGSM" SG_ 1057 MessageCounter_MCPA_OBD_DTC 0;
BA_ "GenSigTimeoutTime_MCPA" SG_ 1057 MessageCounter_MCPA_OBD_DTC 0;
BA_ "GenSigTimeoutTime_MCPB" SG_ 1057 MessageCounter_MCPA_OBD_DTC 0;
BA_ "GenSigTimeoutTime_MRGB" SG_ 1065 CRC_MCPB_OBD_DTC 0;
BA_ "GenSigTimeoutTime_TCM" SG_ 1065 CRC_MCPB_OBD_DTC 0;
BA_ "GenSigTimeoutTime_ECM" SG_ 1065 CRC_MCPB_OBD_DTC 0;
BA_ "GenSigTimeoutTime_SGCP" SG_ 1065 CRC_MCPB_OBD_DTC 0;
BA_ "GenSigTimeoutTime_MRGB" SG_ 1057 CRC_MCPA_OBD_DTC 0;
BA_ "GenSigTimeoutTime_TCM" SG_ 1057 CRC_MCPA_OBD_DTC 0;
BA_ "GenSigTimeoutTime_ECM" SG_ 1057 CRC_MCPA_OBD_DTC 0;
BA_ "GenSigTimeoutTime_SGCP" SG_ 1057 CRC_MCPA_OBD_DTC 0;
BA_ "GenSigTimeoutTime_AGSM" SG_ 1057 CRC_MCPA_OBD_DTC 0;
BA_ "GenSigTimeoutTime_MCPA" SG_ 1057 CRC_MCPA_OBD_DTC 0;
BA_ "GenSigTimeoutTime_MCPB" SG_ 1057 CRC_MCPA_OBD_DTC 0;
BA_ "GenSigTimeoutTime_AGSM" SG_ 1057 MCPA_Cal_ID_Idx 0;
BA_ "GenSigTimeoutTime_MCPA" SG_ 1057 MCPA_Cal_ID_Idx 0;
BA_ "GenSigTimeoutTime_MCPB" SG_ 1057 MCPA_Cal_ID_Idx 0;
BA_ "GenSigTimeoutTime_MRGB" SG_ 1057 MCPA_Cal_ID_Idx 0;
BA_ "GenSigTimeoutTime_TCM" SG_ 1057 MCPA_Cal_ID_Idx 0;
BA_ "GenSigTimeoutTime_ECM" SG_ 1057 MCPA_Cal_ID_Idx 0;
BA_ "GenSigTimeoutTime_SGCP" SG_ 1057 MCPA_Cal_ID_Idx 0;
BA_ "GenSigTimeoutTime_AGSM" SG_ 1057 MCPA_CalChar 0;
BA_ "GenSigTimeoutTime_MCPA" SG_ 1057 MCPA_CalChar 0;
BA_ "GenSigTimeoutTime_MCPB" SG_ 1057 MCPA_CalChar 0;
BA_ "GenSigTimeoutTime_MRGB" SG_ 1057 MCPA_CalChar 0;
BA_ "GenSigTimeoutTime_TCM" SG_ 1057 MCPA_CalChar 0;
BA_ "GenSigTimeoutTime_ECM" SG_ 1057 MCPA_CalChar 0;
BA_ "GenSigTimeoutTime_SGCP" SG_ 1057 MCPA_CalChar 0;
BA_ "GenSigTimeoutTime_AGSM" SG_ 1057 MCPA_DTC_Idx1 0;
BA_ "GenSigTimeoutTime_MCPA" SG_ 1057 MCPA_DTC_Idx1 0;
BA_ "GenSigTimeoutTime_MCPB" SG_ 1057 MCPA_DTC_Idx1 0;
BA_ "GenSigTimeoutTime_MRGB" SG_ 1057 MCPA_DTC_Idx1 0;
BA_ "GenSigTimeoutTime_TCM" SG_ 1057 MCPA_DTC_Idx1 0;
BA_ "GenSigTimeoutTime_ECM" SG_ 1057 MCPA_DTC_Idx1 0;
BA_ "GenSigTimeoutTime_SGCP" SG_ 1057 MCPA_DTC_Idx1 0;
BA_ "GenSigTimeoutTime_AGSM" SG_ 1057 MCPA_DTC_Idx2 0;
BA_ "GenSigTimeoutTime_MCPA" SG_ 1057 MCPA_DTC_Idx2 0;
BA_ "GenSigTimeoutTime_MCPB" SG_ 1057 MCPA_DTC_Idx2 0;
BA_ "GenSigTimeoutTime_MRGB" SG_ 1057 MCPA_DTC_Idx2 0;
BA_ "GenSigTimeoutTime_TCM" SG_ 1057 MCPA_DTC_Idx2 0;
BA_ "GenSigTimeoutTime_ECM" SG_ 1057 MCPA_DTC_Idx2 0;
BA_ "GenSigTimeoutTime_SGCP" SG_ 1057 MCPA_DTC_Idx2 0;
BA_ "GenSigTimeoutTime_AGSM" SG_ 1057 MCPA_DTC_Stat1 0;
BA_ "GenSigTimeoutTime_MCPA" SG_ 1057 MCPA_DTC_Stat1 0;
BA_ "GenSigTimeoutTime_MCPB" SG_ 1057 MCPA_DTC_Stat1 0;
BA_ "GenSigTimeoutTime_MRGB" SG_ 1057 MCPA_DTC_Stat1 0;
BA_ "GenSigTimeoutTime_TCM" SG_ 1057 MCPA_DTC_Stat1 0;
BA_ "GenSigTimeoutTime_ECM" SG_ 1057 MCPA_DTC_Stat1 0;
BA_ "GenSigTimeoutTime_SGCP" SG_ 1057 MCPA_DTC_Stat1 0;
BA_ "GenSigTimeoutTime_AGSM" SG_ 1057 MCPA_DTC_Stat2 0;
BA_ "GenSigTimeoutTime_MCPA" SG_ 1057 MCPA_DTC_Stat2 0;
BA_ "GenSigTimeoutTime_MCPB" SG_ 1057 MCPA_DTC_Stat2 0;
BA_ "GenSigTimeoutTime_MRGB" SG_ 1057 MCPA_DTC_Stat2 0;
BA_ "GenSigTimeoutTime_TCM" SG_ 1057 MCPA_DTC_Stat2 0;
BA_ "GenSigTimeoutTime_ECM" SG_ 1057 MCPA_DTC_Stat2 0;
BA_ "GenSigTimeoutTime_SGCP" SG_ 1057 MCPA_DTC_Stat2 0;
BA_ "GenSigTimeoutTime_TCM" SG_ 263 WheelSpeedRearLeft 0;
BA_ "GenSigTimeoutTime_ECM" SG_ 263 WheelSpeedRearLeft 0;
BA_ "GenSigTimeoutTime_AGSM" SG_ 263 WheelSpeedRearLeft 0;
BA_ "GenSigTimeoutTime_EVCU2" SG_ 263 WheelSpeedRearLeft 0;
BA_ "GenSigTimeoutTime_MCPA" SG_ 263 WheelSpeedRearLeft 0;
BA_ "GenSigTimeoutTime_MCPB" SG_ 263 WheelSpeedRearLeft 0;
BA_ "GenSigTimeoutTime_TCM" SG_ 263 WheelSpeedRearRight 0;
BA_ "GenSigTimeoutTime_ECM" SG_ 263 WheelSpeedRearRight 0;
BA_ "GenSigTimeoutTime_AGSM" SG_ 263 WheelSpeedRearRight 0;
BA_ "GenSigTimeoutTime_EVCU2" SG_ 263 WheelSpeedRearRight 0;
BA_ "GenSigTimeoutTime_MCPA" SG_ 263 WheelSpeedRearRight 0;
BA_ "GenSigTimeoutTime_MCPB" SG_ 263 WheelSpeedRearRight 0;
BA_ "GenSigTimeoutTime_TCM" SG_ 263 EM_max_Trqdyn_P 0;
BA_ "GenSigTimeoutTime_ECM" SG_ 263 EM_max_Trqdyn_P 0;
BA_ "GenSigTimeoutTime_AGSM" SG_ 263 EM_max_Trqdyn_P 0;
BA_ "GenSigTimeoutTime_EVCU2" SG_ 263 EM_max_Trqdyn_P 0;
BA_ "GenSigTimeoutTime_MCPA" SG_ 263 EM_max_Trqdyn_P 0;
BA_ "GenSigTimeoutTime_MCPB" SG_ 263 EM_max_Trqdyn_P 0;
BA_ "GenSigTimeoutTime_TCM" SG_ 263 EM_min_Trqdyn_P 0;
BA_ "GenSigTimeoutTime_ECM" SG_ 263 EM_min_Trqdyn_P 0;
BA_ "GenSigTimeoutTime_AGSM" SG_ 263 EM_min_Trqdyn_P 0;
BA_ "GenSigTimeoutTime_EVCU2" SG_ 263 EM_min_Trqdyn_P 0;
BA_ "GenSigTimeoutTime_MCPA" SG_ 263 EM_min_Trqdyn_P 0;
BA_ "GenSigTimeoutTime_MCPB" SG_ 263 EM_min_Trqdyn_P 0;
BA_ "GenSigTimeoutTime_TCM" SG_ 263 Gear_Rq 0;
BA_ "GenSigTimeoutTime_ECM" SG_ 263 Gear_Rq 0;
BA_ "GenSigTimeoutTime_AGSM" SG_ 263 Gear_Rq 0;
BA_ "GenSigTimeoutTime_EVCU2" SG_ 263 Gear_Rq 0;
BA_ "GenSigTimeoutTime_MCPA" SG_ 263 Gear_Rq 0;
BA_ "GenSigTimeoutTime_MCPB" SG_ 263 Gear_Rq 0;
BA_ "GenSigTimeoutTime_TCM" SG_ 263 Inertia_Torque_Active 0;
BA_ "GenSigTimeoutTime_ECM" SG_ 263 Inertia_Torque_Active 0;
BA_ "GenSigTimeoutTime_AGSM" SG_ 263 Inertia_Torque_Active 0;
BA_ "GenSigTimeoutTime_EVCU2" SG_ 263 Inertia_Torque_Active 0;
BA_ "GenSigTimeoutTime_MCPA" SG_ 263 Inertia_Torque_Active 0;
BA_ "GenSigTimeoutTime_MCPB" SG_ 263 Inertia_Torque_Active 0;
BA_ "GenSigTimeoutTime_TCM" SG_ 263 Transm_Torq_Feedback 0;
BA_ "GenSigTimeoutTime_ECM" SG_ 263 Transm_Torq_Feedback 0;
BA_ "GenSigTimeoutTime_AGSM" SG_ 263 Transm_Torq_Feedback 0;
BA_ "GenSigTimeoutTime_EVCU2" SG_ 263 Transm_Torq_Feedback 0;
BA_ "GenSigTimeoutTime_MCPA" SG_ 263 Transm_Torq_Feedback 0;
BA_ "GenSigTimeoutTime_MCPB" SG_ 263 Transm_Torq_Feedback 0;
BA_ "GenSigTimeoutTime_TCM" SG_ 263 EOPB_Min_Oil_FlwRate_Rq 0;
BA_ "GenSigTimeoutTime_ECM" SG_ 263 EOPB_Min_Oil_FlwRate_Rq 0;
BA_ "GenSigTimeoutTime_AGSM" SG_ 263 EOPB_Min_Oil_FlwRate_Rq 0;
BA_ "GenSigTimeoutTime_EVCU2" SG_ 263 EOPB_Min_Oil_FlwRate_Rq 0;
BA_ "GenSigTimeoutTime_MCPA" SG_ 263 EOPB_Min_Oil_FlwRate_Rq 0;
BA_ "GenSigTimeoutTime_MCPB" SG_ 263 EOPB_Min_Oil_FlwRate_Rq 0;
BA_ "GenSigTimeoutTime_AGSM" SG_ 263 Custom_DrvMdSts_PT 0;
BA_ "GenSigTimeoutTime_EVCU2" SG_ 263 Custom_DrvMdSts_PT 0;
BA_ "GenSigTimeoutTime_MCPA" SG_ 263 Custom_DrvMdSts_PT 0;
BA_ "GenSigTimeoutTime_MCPB" SG_ 263 Custom_DrvMdSts_PT 0;
BA_ "GenSigTimeoutTime_MRGB" SG_ 263 Custom_DrvMdSts_PT 0;
BA_ "GenSigTimeoutTime_TCM" SG_ 263 Custom_DrvMdSts_PT 0;
BA_ "GenSigTimeoutTime_ECM" SG_ 263 Custom_DrvMdSts_PT 0;
BA_ "GenSigTimeoutTime_TCM" SG_ 263 PropulsionSystemActive_PT 0;
BA_ "GenSigTimeoutTime_ECM" SG_ 263 PropulsionSystemActive_PT 0;
BA_ "GenSigTimeoutTime_AGSM" SG_ 263 PropulsionSystemActive_PT 0;
BA_ "GenSigTimeoutTime_EVCU2" SG_ 263 PropulsionSystemActive_PT 0;
BA_ "GenSigTimeoutTime_MCPA" SG_ 263 PropulsionSystemActive_PT 0;
BA_ "GenSigTimeoutTime_MCPB" SG_ 263 PropulsionSystemActive_PT 0;
BA_ "GenSigTimeoutTime_AGSM" SG_ 1065 CRC_MCPB_OBD_DTC 0;
BA_ "GenSigTimeoutTime_MCPA" SG_ 1065 CRC_MCPB_OBD_DTC 0;
BA_ "GenSigTimeoutTime_MCPB" SG_ 1065 CRC_MCPB_OBD_DTC 0;
BA_ "GenSigTimeoutTime_MRGB" SG_ 1065 MCPB_Cal_ID_Idx 0;
BA_ "GenSigTimeoutTime_TCM" SG_ 1065 MCPB_Cal_ID_Idx 0;
BA_ "GenSigTimeoutTime_ECM" SG_ 1065 MCPB_Cal_ID_Idx 0;
BA_ "GenSigTimeoutTime_SGCP" SG_ 1065 MCPB_Cal_ID_Idx 0;
BA_ "GenSigTimeoutTime_AGSM" SG_ 1065 MCPB_Cal_ID_Idx 0;
BA_ "GenSigTimeoutTime_MCPA" SG_ 1065 MCPB_Cal_ID_Idx 0;
BA_ "GenSigTimeoutTime_MCPB" SG_ 1065 MCPB_Cal_ID_Idx 0;
BA_ "GenSigTimeoutTime_MRGB" SG_ 1065 MCPB_CalChar 0;
BA_ "GenSigTimeoutTime_TCM" SG_ 1065 MCPB_CalChar 0;
BA_ "GenSigTimeoutTime_ECM" SG_ 1065 MCPB_CalChar 0;
BA_ "GenSigTimeoutTime_SGCP" SG_ 1065 MCPB_CalChar 0;
BA_ "GenSigTimeoutTime_AGSM" SG_ 1065 MCPB_CalChar 0;
BA_ "GenSigTimeoutTime_MCPA" SG_ 1065 MCPB_CalChar 0;
BA_ "GenSigTimeoutTime_MCPB" SG_ 1065 MCPB_CalChar 0;
BA_ "GenSigTimeoutTime_MRGB" SG_ 1065 MCPB_DTC_Idx1 0;
BA_ "GenSigTimeoutTime_TCM" SG_ 1065 MCPB_DTC_Idx1 0;
BA_ "GenSigTimeoutTime_ECM" SG_ 1065 MCPB_DTC_Idx1 0;
BA_ "GenSigTimeoutTime_SGCP" SG_ 1065 MCPB_DTC_Idx1 0;
BA_ "GenSigTimeoutTime_AGSM" SG_ 1065 MCPB_DTC_Idx1 0;
BA_ "GenSigTimeoutTime_MCPA" SG_ 1065 MCPB_DTC_Idx1 0;
BA_ "GenSigTimeoutTime_MCPB" SG_ 1065 MCPB_DTC_Idx1 0;
BA_ "GenSigTimeoutTime_MRGB" SG_ 1065 MCPB_DTC_Idx2 0;
BA_ "GenSigTimeoutTime_TCM" SG_ 1065 MCPB_DTC_Idx2 0;
BA_ "GenSigTimeoutTime_ECM" SG_ 1065 MCPB_DTC_Idx2 0;
BA_ "GenSigTimeoutTime_SGCP" SG_ 1065 MCPB_DTC_Idx2 0;
BA_ "GenSigTimeoutTime_AGSM" SG_ 1065 MCPB_DTC_Idx2 0;
BA_ "GenSigTimeoutTime_MCPA" SG_ 1065 MCPB_DTC_Idx2 0;
BA_ "GenSigTimeoutTime_MCPB" SG_ 1065 MCPB_DTC_Idx2 0;
BA_ "GenSigTimeoutTime_MRGB" SG_ 1065 MCPB_DTC_Stat1 0;
BA_ "GenSigTimeoutTime_TCM" SG_ 1065 MCPB_DTC_Stat1 0;
BA_ "GenSigTimeoutTime_ECM" SG_ 1065 MCPB_DTC_Stat1 0;
BA_ "GenSigTimeoutTime_SGCP" SG_ 1065 MCPB_DTC_Stat1 0;
BA_ "GenSigTimeoutTime_AGSM" SG_ 1065 MCPB_DTC_Stat1 0;
BA_ "GenSigTimeoutTime_MCPA" SG_ 1065 MCPB_DTC_Stat1 0;
BA_ "GenSigTimeoutTime_MCPB" SG_ 1065 MCPB_DTC_Stat1 0;
BA_ "GenSigTimeoutTime_MRGB" SG_ 1065 MCPB_DTC_Stat2 0;
BA_ "GenSigTimeoutTime_TCM" SG_ 1065 MCPB_DTC_Stat2 0;
BA_ "GenSigTimeoutTime_ECM" SG_ 1065 MCPB_DTC_Stat2 0;
BA_ "GenSigTimeoutTime_SGCP" SG_ 1065 MCPB_DTC_Stat2 0;
BA_ "GenSigTimeoutTime_AGSM" SG_ 1065 MCPB_DTC_Stat2 0;
BA_ "GenSigTimeoutTime_MCPA" SG_ 1065 MCPB_DTC_Stat2 0;
BA_ "GenSigTimeoutTime_MCPB" SG_ 1065 MCPB_DTC_Stat2 0;
BA_ "GenSigTimeoutTime_MRGB" SG_ 1065 MessageCounter_MCPB_OBD_DTC 0;
BA_ "GenSigTimeoutTime_TCM" SG_ 1065 MessageCounter_MCPB_OBD_DTC 0;
BA_ "GenSigTimeoutTime_ECM" SG_ 1065 MessageCounter_MCPB_OBD_DTC 0;
BA_ "GenSigTimeoutTime_SGCP" SG_ 1065 MessageCounter_MCPB_OBD_DTC 0;
BA_ "GenSigTimeoutTime_AGSM" SG_ 1065 MessageCounter_MCPB_OBD_DTC 0;
BA_ "GenSigTimeoutTime_MCPA" SG_ 1065 MessageCounter_MCPB_OBD_DTC 0;
BA_ "GenSigTimeoutTime_MCPB" SG_ 1065 MessageCounter_MCPB_OBD_DTC 0;
BA_ "GenSigTimeoutTime_MRGB" SG_ 1811 Real_Time_Validity 0;
BA_ "GenSigTimeoutTime_TCM" SG_ 1811 Real_Time_Validity 0;
BA_ "GenSigTimeoutTime_ECM" SG_ 1811 Real_Time_Validity 0;
BA_ "GenSigTimeoutTime_AGSM" SG_ 1811 Real_Time_Validity 0;
BA_ "GenSigTimeoutTime_EVCU2" SG_ 1811 Real_Time_Validity 0;
BA_ "GenSigTimeoutTime_MRGB" SG_ 1811 Real_Time_Clock 0;
BA_ "GenSigTimeoutTime_TCM" SG_ 1811 Real_Time_Clock 0;
BA_ "GenSigTimeoutTime_ECM" SG_ 1811 Real_Time_Clock 0;
BA_ "GenSigTimeoutTime_AGSM" SG_ 1811 Real_Time_Clock 0;
BA_ "GenSigTimeoutTime_EVCU2" SG_ 1811 Real_Time_Clock 0;
BA_ "GenSigTimeoutTime_MRGB" SG_ 263 TerrainModeStat_PT 0;
BA_ "GenSigTimeoutTime_TCM" SG_ 263 TerrainModeStat_PT 0;
BA_ "GenSigTimeoutTime_ECM" SG_ 263 TerrainModeStat_PT 0;
BA_ "GenSigTimeoutTime_AGSM" SG_ 263 TerrainModeStat_PT 0;
BA_ "GenSigTimeoutTime_EVCU2" SG_ 263 TerrainModeStat_PT 0;
BA_ "GenSigTimeoutTime_MCPA" SG_ 263 TerrainModeStat_PT 0;
BA_ "GenSigTimeoutTime_MCPB" SG_ 263 TerrainModeStat_PT 0;
BA_ "GenSigTimeoutTime_MRGB" SG_ 2654486592 SourceNodeIdentifier_1E384040 0;
BA_ "GenSigTimeoutTime_TCM" SG_ 2654486592 SourceNodeIdentifier_1E384040 0;
BA_ "GenSigTimeoutTime_ECM" SG_ 2654486592 SourceNodeIdentifier_1E384040 0;
BA_ "GenSigTimeoutTime_SGCP" SG_ 2654486592 SourceNodeIdentifier_1E384040 0;
BA_ "GenSigTimeoutTime_AGSM" SG_ 2654486592 SourceNodeIdentifier_1E384040 0;
BA_ "GenSigTimeoutTime_EVCU2" SG_ 2654486592 SourceNodeIdentifier_1E384040 0;
BA_ "GenSigTimeoutTime_MCPA" SG_ 2654486592 SourceNodeIdentifier_1E384040 0;
BA_ "GenSigTimeoutTime_MCPB" SG_ 2654486592 SourceNodeIdentifier_1E384040 0;
BA_ "GenSigTimeoutTime_MRGB" SG_ 2654486592 CBV_bit1_1E384040 0;
BA_ "GenSigTimeoutTime_TCM" SG_ 2654486592 CBV_bit1_1E384040 0;
BA_ "GenSigTimeoutTime_ECM" SG_ 2654486592 CBV_bit1_1E384040 0;
BA_ "GenSigTimeoutTime_SGCP" SG_ 2654486592 CBV_bit1_1E384040 0;
BA_ "GenSigTimeoutTime_AGSM" SG_ 2654486592 CBV_bit1_1E384040 0;
BA_ "GenSigTimeoutTime_EVCU2" SG_ 2654486592 CBV_bit1_1E384040 0;
BA_ "GenSigTimeoutTime_MCPA" SG_ 2654486592 CBV_bit1_1E384040 0;
BA_ "GenSigTimeoutTime_MCPB" SG_ 2654486592 CBV_bit1_1E384040 0;
BA_ "GenSigTimeoutTime_MRGB" SG_ 2654486592 CBV_bit0_RepeatMessageRequestBit_1E384040 0;
BA_ "GenSigTimeoutTime_TCM" SG_ 2654486592 CBV_bit0_RepeatMessageRequestBit_1E384040 0;
BA_ "GenSigTimeoutTime_ECM" SG_ 2654486592 CBV_bit0_RepeatMessageRequestBit_1E384040 0;
BA_ "GenSigTimeoutTime_SGCP" SG_ 2654486592 CBV_bit0_RepeatMessageRequestBit_1E384040 0;
BA_ "GenSigTimeoutTime_AGSM" SG_ 2654486592 CBV_bit0_RepeatMessageRequestBit_1E384040 0;
BA_ "GenSigTimeoutTime_EVCU2" SG_ 2654486592 CBV_bit0_RepeatMessageRequestBit_1E384040 0;
BA_ "GenSigTimeoutTime_MCPA" SG_ 2654486592 CBV_bit0_RepeatMessageRequestBit_1E384040 0;
BA_ "GenSigTimeoutTime_MCPB" SG_ 2654486592 CBV_bit0_RepeatMessageRequestBit_1E384040 0;
BA_ "GenSigTimeoutTime_MRGB" SG_ 2654486592 CBV_bit7_1E384040 0;
BA_ "GenSigTimeoutTime_TCM" SG_ 2654486592 CBV_bit7_1E384040 0;
BA_ "GenSigTimeoutTime_ECM" SG_ 2654486592 CBV_bit7_1E384040 0;
BA_ "GenSigTimeoutTime_SGCP" SG_ 2654486592 CBV_bit7_1E384040 0;
BA_ "GenSigTimeoutTime_AGSM" SG_ 2654486592 CBV_bit7_1E384040 0;
BA_ "GenSigTimeoutTime_EVCU2" SG_ 2654486592 CBV_bit7_1E384040 0;
BA_ "GenSigTimeoutTime_MCPA" SG_ 2654486592 CBV_bit7_1E384040 0;
BA_ "GenSigTimeoutTime_MCPB" SG_ 2654486592 CBV_bit7_1E384040 0;
BA_ "GenSigTimeoutTime_MRGB" SG_ 2654486592 CBV_bit6_PartialNtwInfBit_1E384040 0;
BA_ "GenSigTimeoutTime_TCM" SG_ 2654486592 CBV_bit6_PartialNtwInfBit_1E384040 0;
BA_ "GenSigTimeoutTime_ECM" SG_ 2654486592 CBV_bit6_PartialNtwInfBit_1E384040 0;
BA_ "GenSigTimeoutTime_SGCP" SG_ 2654486592 CBV_bit6_PartialNtwInfBit_1E384040 0;
BA_ "GenSigTimeoutTime_AGSM" SG_ 2654486592 CBV_bit6_PartialNtwInfBit_1E384040 0;
BA_ "GenSigTimeoutTime_EVCU2" SG_ 2654486592 CBV_bit6_PartialNtwInfBit_1E384040 0;
BA_ "GenSigTimeoutTime_MCPA" SG_ 2654486592 CBV_bit6_PartialNtwInfBit_1E384040 0;
BA_ "GenSigTimeoutTime_MCPB" SG_ 2654486592 CBV_bit6_PartialNtwInfBit_1E384040 0;
BA_ "GenSigTimeoutTime_MRGB" SG_ 2654486592 CBV_bit5_1E384040 0;
BA_ "GenSigTimeoutTime_TCM" SG_ 2654486592 CBV_bit5_1E384040 0;
BA_ "GenSigTimeoutTime_ECM" SG_ 2654486592 CBV_bit5_1E384040 0;
BA_ "GenSigTimeoutTime_SGCP" SG_ 2654486592 CBV_bit5_1E384040 0;
BA_ "GenSigTimeoutTime_AGSM" SG_ 2654486592 CBV_bit5_1E384040 0;
BA_ "GenSigTimeoutTime_EVCU2" SG_ 2654486592 CBV_bit5_1E384040 0;
BA_ "GenSigTimeoutTime_MCPA" SG_ 2654486592 CBV_bit5_1E384040 0;
BA_ "GenSigTimeoutTime_MCPB" SG_ 2654486592 CBV_bit5_1E384040 0;
BA_ "GenSigTimeoutTime_MRGB" SG_ 2654486592 CBV_bit4_ActiveWakeupBit_1E384040 0;
BA_ "GenSigTimeoutTime_TCM" SG_ 2654486592 CBV_bit4_ActiveWakeupBit_1E384040 0;
BA_ "GenSigTimeoutTime_ECM" SG_ 2654486592 CBV_bit4_ActiveWakeupBit_1E384040 0;
BA_ "GenSigTimeoutTime_SGCP" SG_ 2654486592 CBV_bit4_ActiveWakeupBit_1E384040 0;
BA_ "GenSigTimeoutTime_AGSM" SG_ 2654486592 CBV_bit4_ActiveWakeupBit_1E384040 0;
BA_ "GenSigTimeoutTime_EVCU2" SG_ 2654486592 CBV_bit4_ActiveWakeupBit_1E384040 0;
BA_ "GenSigTimeoutTime_MCPA" SG_ 2654486592 CBV_bit4_ActiveWakeupBit_1E384040 0;
BA_ "GenSigTimeoutTime_MCPB" SG_ 2654486592 CBV_bit4_ActiveWakeupBit_1E384040 0;
BA_ "GenSigTimeoutTime_MRGB" SG_ 2654486592 CBV_bit3_NMCoordinatorBit_1E384040 0;
BA_ "GenSigTimeoutTime_TCM" SG_ 2654486592 CBV_bit3_NMCoordinatorBit_1E384040 0;
BA_ "GenSigTimeoutTime_ECM" SG_ 2654486592 CBV_bit3_NMCoordinatorBit_1E384040 0;
BA_ "GenSigTimeoutTime_SGCP" SG_ 2654486592 CBV_bit3_NMCoordinatorBit_1E384040 0;
BA_ "GenSigTimeoutTime_AGSM" SG_ 2654486592 CBV_bit3_NMCoordinatorBit_1E384040 0;
BA_ "GenSigTimeoutTime_EVCU2" SG_ 2654486592 CBV_bit3_NMCoordinatorBit_1E384040 0;
BA_ "GenSigTimeoutTime_MCPA" SG_ 2654486592 CBV_bit3_NMCoordinatorBit_1E384040 0;
BA_ "GenSigTimeoutTime_MCPB" SG_ 2654486592 CBV_bit3_NMCoordinatorBit_1E384040 0;
BA_ "GenSigTimeoutTime_MRGB" SG_ 2654486592 CBV_bit2_1E384040 0;
BA_ "GenSigTimeoutTime_TCM" SG_ 2654486592 CBV_bit2_1E384040 0;
BA_ "GenSigTimeoutTime_ECM" SG_ 2654486592 CBV_bit2_1E384040 0;
BA_ "GenSigTimeoutTime_SGCP" SG_ 2654486592 CBV_bit2_1E384040 0;
BA_ "GenSigTimeoutTime_AGSM" SG_ 2654486592 CBV_bit2_1E384040 0;
BA_ "GenSigTimeoutTime_EVCU2" SG_ 2654486592 CBV_bit2_1E384040 0;
BA_ "GenSigTimeoutTime_MCPA" SG_ 2654486592 CBV_bit2_1E384040 0;
BA_ "GenSigTimeoutTime_MCPB" SG_ 2654486592 CBV_bit2_1E384040 0;
BA_ "GenSigTimeoutTime_SGCP" SG_ 263 GasPedalPositionFailSts_PT 0;
BA_ "GenSigTimeoutTime_AGSM" SG_ 263 GasPedalPositionFailSts_PT 0;
BA_ "GenSigTimeoutTime_EVCU2" SG_ 263 GasPedalPositionFailSts_PT 0;
BA_ "GenSigTimeoutTime_MCPA" SG_ 263 GasPedalPositionFailSts_PT 0;
BA_ "GenSigTimeoutTime_MCPB" SG_ 263 GasPedalPositionFailSts_PT 0;
BA_ "GenSigTimeoutTime_MRGB" SG_ 263 GearIndicationSts_PT 0;
BA_ "GenSigTimeoutTime_TCM" SG_ 263 GearIndicationSts_PT 0;
BA_ "GenSigTimeoutTime_ECM" SG_ 263 GearIndicationSts_PT 0;
BA_ "GenSigTimeoutTime_SGCP" SG_ 263 GearIndicationSts_PT 0;
BA_ "GenSigTimeoutTime_EVCU2" SG_ 263 GearIndicationSts_PT 0;
BA_ "GenSigTimeoutTime_MCPA" SG_ 263 GearIndicationSts_PT 0;
BA_ "GenSigTimeoutTime_MCPB" SG_ 263 GearIndicationSts_PT 0;
BA_ "GenSigTimeoutTime_MRGB" SG_ 263 CRC_PT_SYSTEM_FD_1 0;
BA_ "GenSigTimeoutTime_TCM" SG_ 263 CRC_PT_SYSTEM_FD_1 0;
BA_ "GenSigTimeoutTime_SGCP" SG_ 263 CRC_PT_SYSTEM_FD_1 0;
BA_ "GenSigTimeoutTime_MCPB" SG_ 263 CRC_PT_SYSTEM_FD_1 0;
BA_ "GenSigTimeoutTime_AGSM" SG_ 263 CRC_PT_SYSTEM_FD_1 0;
BA_ "GenSigTimeoutTime_EVCU2" SG_ 263 CRC_PT_SYSTEM_FD_1 0;
BA_ "GenSigTimeoutTime_MCPA" SG_ 263 CRC_PT_SYSTEM_FD_1 0;
BA_ "GenSigTimeoutTime_SGCP" SG_ 263 GasPedalPosition_PT 0;
BA_ "GenSigTimeoutTime_AGSM" SG_ 263 GasPedalPosition_PT 0;
BA_ "GenSigTimeoutTime_EVCU2" SG_ 263 GasPedalPosition_PT 0;
BA_ "GenSigTimeoutTime_MCPA" SG_ 263 GasPedalPosition_PT 0;
BA_ "GenSigTimeoutTime_MCPB" SG_ 263 GasPedalPosition_PT 0;
BA_ "GenSigTimeoutTime_MRGB" SG_ 263 ShiftLeverLockReq_PT 0;
BA_ "GenSigTimeoutTime_TCM" SG_ 263 ShiftLeverLockReq_PT 0;
BA_ "GenSigTimeoutTime_ECM" SG_ 263 ShiftLeverLockReq_PT 0;
BA_ "GenSigTimeoutTime_EVCU2" SG_ 263 ShiftLeverLockReq_PT 0;
BA_ "GenSigTimeoutTime_MCPA" SG_ 263 ShiftLeverLockReq_PT 0;
BA_ "GenSigTimeoutTime_MCPB" SG_ 263 ShiftLeverLockReq_PT 0;
BA_ "GenSigTimeoutTime_MRGB" SG_ 263 ShiftLeverPosition_PT 0;
BA_ "GenSigTimeoutTime_TCM" SG_ 263 ShiftLeverPosition_PT 0;
BA_ "GenSigTimeoutTime_ECM" SG_ 263 ShiftLeverPosition_PT 0;
BA_ "GenSigTimeoutTime_SGCP" SG_ 263 ShiftLeverPosition_PT 0;
BA_ "GenSigTimeoutTime_EVCU2" SG_ 263 ShiftLeverPosition_PT 0;
BA_ "GenSigTimeoutTime_MCPA" SG_ 263 ShiftLeverPosition_PT 0;
BA_ "GenSigTimeoutTime_MCPB" SG_ 263 ShiftLeverPosition_PT 0;
BA_ "GenSigTimeoutTime_MRGB" SG_ 263 MessageCounter_PT_SYSTEM_FD_1 0;
BA_ "GenSigTimeoutTime_TCM" SG_ 263 MessageCounter_PT_SYSTEM_FD_1 0;
BA_ "GenSigTimeoutTime_SGCP" SG_ 263 MessageCounter_PT_SYSTEM_FD_1 0;
BA_ "GenSigTimeoutTime_MCPB" SG_ 263 MessageCounter_PT_SYSTEM_FD_1 0;
BA_ "GenSigTimeoutTime_AGSM" SG_ 263 MessageCounter_PT_SYSTEM_FD_1 0;
BA_ "GenSigTimeoutTime_EVCU2" SG_ 263 MessageCounter_PT_SYSTEM_FD_1 0;
BA_ "GenSigTimeoutTime_MCPA" SG_ 263 MessageCounter_PT_SYSTEM_FD_1 0;
BA_ "GenSigTimeoutTime_EVCU2" SG_ 263 R_SHFT_LOCK_PT 0;
BA_ "GenSigTimeoutTime_MCPA" SG_ 263 R_SHFT_LOCK_PT 0;
BA_ "GenSigTimeoutTime_MCPB" SG_ 263 R_SHFT_LOCK_PT 0;
BA_ "GenSigTimeoutTime_ECM" SG_ 263 APCM_Rq_PT 0;
BA_ "GenSigTimeoutTime_SGCP" SG_ 263 APCM_Rq_PT 0;
BA_ "GenSigTimeoutTime_EVCU2" SG_ 263 APCM_Rq_PT 0;
BA_ "GenSigTimeoutTime_MCPA" SG_ 263 APCM_Rq_PT 0;
BA_ "GenSigTimeoutTime_MCPB" SG_ 263 APCM_Rq_PT 0;
BA_ "GenSigTimeoutTime_MRGB" SG_ 263 TransmissionFailSts_PT 0;
BA_ "GenSigTimeoutTime_TCM" SG_ 263 TransmissionFailSts_PT 0;
BA_ "GenSigTimeoutTime_ECM" SG_ 263 TransmissionFailSts_PT 0;
BA_ "GenSigTimeoutTime_SGCP" SG_ 263 TransmissionFailSts_PT 0;
BA_ "GenSigTimeoutTime_EVCU2" SG_ 263 TransmissionFailSts_PT 0;
BA_ "GenSigTimeoutTime_MCPA" SG_ 263 TransmissionFailSts_PT 0;
BA_ "GenSigTimeoutTime_MCPB" SG_ 263 TransmissionFailSts_PT 0;
BA_ "GenSigTimeoutTime_MRGB" SG_ 263 GearEngaged_PT 0;
BA_ "GenSigTimeoutTime_TCM" SG_ 263 GearEngaged_PT 0;
BA_ "GenSigTimeoutTime_ECM" SG_ 263 GearEngaged_PT 0;
BA_ "GenSigTimeoutTime_SGCP" SG_ 263 GearEngaged_PT 0;
BA_ "GenSigTimeoutTime_AGSM" SG_ 263 GearEngaged_PT 0;
BA_ "GenSigTimeoutTime_EVCU2" SG_ 263 GearEngaged_PT 0;
BA_ "GenSigTimeoutTime_MCPA" SG_ 263 GearEngaged_PT 0;
BA_ "GenSigTimeoutTime_MRGB" SG_ 263 GearEngagedForDisplay_PT 0;
BA_ "GenSigTimeoutTime_TCM" SG_ 263 GearEngagedForDisplay_PT 0;
BA_ "GenSigTimeoutTime_ECM" SG_ 263 GearEngagedForDisplay_PT 0;
BA_ "GenSigTimeoutTime_SGCP" SG_ 263 GearEngagedForDisplay_PT 0;
BA_ "GenSigTimeoutTime_EVCU2" SG_ 263 GearEngagedForDisplay_PT 0;
BA_ "GenSigTimeoutTime_MCPA" SG_ 263 GearEngagedForDisplay_PT 0;
BA_ "GenSigTimeoutTime_MCPB" SG_ 263 GearEngagedForDisplay_PT 0;
BA_ "GenSigTimeoutTime_MRGB" SG_ 263 PowertrainPrplsnActv_PT 0;
BA_ "GenSigTimeoutTime_TCM" SG_ 263 PowertrainPrplsnActv_PT 0;
BA_ "GenSigTimeoutTime_ECM" SG_ 263 PowertrainPrplsnActv_PT 0;
BA_ "GenSigTimeoutTime_AGSM" SG_ 263 PowertrainPrplsnActv_PT 0;
BA_ "GenSigTimeoutTime_EVCU2" SG_ 263 PowertrainPrplsnActv_PT 0;
BA_ "GenSigTimeoutTime_MCPA" SG_ 263 PowertrainPrplsnActv_PT 0;
BA_ "GenSigTimeoutTime_MCPB" SG_ 263 PowertrainPrplsnActv_PT 0;
BA_ "GenSigTimeoutTime_AGSM" SG_ 2654486616 SourceNodeIdentifier_1E384058 0;
BA_ "GenSigTimeoutTime_EVCU2" SG_ 2654486616 SourceNodeIdentifier_1E384058 0;
BA_ "GenSigTimeoutTime_MCPA" SG_ 2654486616 SourceNodeIdentifier_1E384058 0;
BA_ "GenSigTimeoutTime_MCPB" SG_ 2654486616 SourceNodeIdentifier_1E384058 0;
BA_ "GenSigTimeoutTime_MRGB" SG_ 2654486616 SourceNodeIdentifier_1E384058 0;
BA_ "GenSigTimeoutTime_TCM" SG_ 2654486616 SourceNodeIdentifier_1E384058 0;
BA_ "GenSigTimeoutTime_ECM" SG_ 2654486616 SourceNodeIdentifier_1E384058 0;
BA_ "GenSigTimeoutTime_SGCP" SG_ 2654486616 SourceNodeIdentifier_1E384058 0;
BA_ "GenSigTimeoutTime_AGSM" SG_ 2654486616 CBV_bit7_1E384058 0;
BA_ "GenSigTimeoutTime_EVCU2" SG_ 2654486616 CBV_bit7_1E384058 0;
BA_ "GenSigTimeoutTime_MCPA" SG_ 2654486616 CBV_bit7_1E384058 0;
BA_ "GenSigTimeoutTime_MCPB" SG_ 2654486616 CBV_bit7_1E384058 0;
BA_ "GenSigTimeoutTime_MRGB" SG_ 2654486616 CBV_bit7_1E384058 0;
BA_ "GenSigTimeoutTime_TCM" SG_ 2654486616 CBV_bit7_1E384058 0;
BA_ "GenSigTimeoutTime_ECM" SG_ 2654486616 CBV_bit7_1E384058 0;
BA_ "GenSigTimeoutTime_SGCP" SG_ 2654486616 CBV_bit7_1E384058 0;
BA_ "GenSigTimeoutTime_AGSM" SG_ 2654486616 CBV_bit6_PartialNtwInfBit_1E384058 0;
BA_ "GenSigTimeoutTime_EVCU2" SG_ 2654486616 CBV_bit6_PartialNtwInfBit_1E384058 0;
BA_ "GenSigTimeoutTime_MCPA" SG_ 2654486616 CBV_bit6_PartialNtwInfBit_1E384058 0;
BA_ "GenSigTimeoutTime_MCPB" SG_ 2654486616 CBV_bit6_PartialNtwInfBit_1E384058 0;
BA_ "GenSigTimeoutTime_MRGB" SG_ 2654486616 CBV_bit6_PartialNtwInfBit_1E384058 0;
BA_ "GenSigTimeoutTime_TCM" SG_ 2654486616 CBV_bit6_PartialNtwInfBit_1E384058 0;
BA_ "GenSigTimeoutTime_ECM" SG_ 2654486616 CBV_bit6_PartialNtwInfBit_1E384058 0;
BA_ "GenSigTimeoutTime_SGCP" SG_ 2654486616 CBV_bit6_PartialNtwInfBit_1E384058 0;
BA_ "GenSigTimeoutTime_MRGB" SG_ 2654486616 CBV_bit5_1E384058 0;
BA_ "GenSigTimeoutTime_TCM" SG_ 2654486616 CBV_bit5_1E384058 0;
BA_ "GenSigTimeoutTime_ECM" SG_ 2654486616 CBV_bit5_1E384058 0;
BA_ "GenSigTimeoutTime_SGCP" SG_ 2654486616 CBV_bit5_1E384058 0;
BA_ "GenSigTimeoutTime_AGSM" SG_ 2654486616 CBV_bit5_1E384058 0;
BA_ "GenSigTimeoutTime_EVCU2" SG_ 2654486616 CBV_bit5_1E384058 0;
BA_ "GenSigTimeoutTime_MCPA" SG_ 2654486616 CBV_bit5_1E384058 0;
BA_ "GenSigTimeoutTime_MCPB" SG_ 2654486616 CBV_bit5_1E384058 0;
BA_ "GenSigTimeoutTime_MRGB" SG_ 2654486616 CBV_bit4_ActiveWakeupBit_1E384058 0;
BA_ "GenSigTimeoutTime_TCM" SG_ 2654486616 CBV_bit4_ActiveWakeupBit_1E384058 0;
BA_ "GenSigTimeoutTime_ECM" SG_ 2654486616 CBV_bit4_ActiveWakeupBit_1E384058 0;
BA_ "GenSigTimeoutTime_SGCP" SG_ 2654486616 CBV_bit4_ActiveWakeupBit_1E384058 0;
BA_ "GenSigTimeoutTime_AGSM" SG_ 2654486616 CBV_bit4_ActiveWakeupBit_1E384058 0;
BA_ "GenSigTimeoutTime_EVCU2" SG_ 2654486616 CBV_bit4_ActiveWakeupBit_1E384058 0;
BA_ "GenSigTimeoutTime_MCPA" SG_ 2654486616 CBV_bit4_ActiveWakeupBit_1E384058 0;
BA_ "GenSigTimeoutTime_MCPB" SG_ 2654486616 CBV_bit4_ActiveWakeupBit_1E384058 0;
BA_ "GenSigTimeoutTime_MRGB" SG_ 2654486616 CBV_bit3_NMCoordinatorBit_1E384058 0;
BA_ "GenSigTimeoutTime_TCM" SG_ 2654486616 CBV_bit3_NMCoordinatorBit_1E384058 0;
BA_ "GenSigTimeoutTime_ECM" SG_ 2654486616 CBV_bit3_NMCoordinatorBit_1E384058 0;
BA_ "GenSigTimeoutTime_SGCP" SG_ 2654486616 CBV_bit3_NMCoordinatorBit_1E384058 0;
BA_ "GenSigTimeoutTime_AGSM" SG_ 2654486616 CBV_bit3_NMCoordinatorBit_1E384058 0;
BA_ "GenSigTimeoutTime_EVCU2" SG_ 2654486616 CBV_bit3_NMCoordinatorBit_1E384058 0;
BA_ "GenSigTimeoutTime_MCPA" SG_ 2654486616 CBV_bit3_NMCoordinatorBit_1E384058 0;
BA_ "GenSigTimeoutTime_MCPB" SG_ 2654486616 CBV_bit3_NMCoordinatorBit_1E384058 0;
BA_ "GenSigTimeoutTime_MRGB" SG_ 2654486616 CBV_bit2_1E384058 0;
BA_ "GenSigTimeoutTime_TCM" SG_ 2654486616 CBV_bit2_1E384058 0;
BA_ "GenSigTimeoutTime_ECM" SG_ 2654486616 CBV_bit2_1E384058 0;
BA_ "GenSigTimeoutTime_SGCP" SG_ 2654486616 CBV_bit2_1E384058 0;
BA_ "GenSigTimeoutTime_AGSM" SG_ 2654486616 CBV_bit2_1E384058 0;
BA_ "GenSigTimeoutTime_EVCU2" SG_ 2654486616 CBV_bit2_1E384058 0;
BA_ "GenSigTimeoutTime_MCPA" SG_ 2654486616 CBV_bit2_1E384058 0;
BA_ "GenSigTimeoutTime_MCPB" SG_ 2654486616 CBV_bit2_1E384058 0;
BA_ "GenSigTimeoutTime_MRGB" SG_ 2654486616 CBV_bit1_1E384058 0;
BA_ "GenSigTimeoutTime_TCM" SG_ 2654486616 CBV_bit1_1E384058 0;
BA_ "GenSigTimeoutTime_ECM" SG_ 2654486616 CBV_bit1_1E384058 0;
BA_ "GenSigTimeoutTime_SGCP" SG_ 2654486616 CBV_bit1_1E384058 0;
BA_ "GenSigTimeoutTime_AGSM" SG_ 2654486616 CBV_bit1_1E384058 0;
BA_ "GenSigTimeoutTime_EVCU2" SG_ 2654486616 CBV_bit1_1E384058 0;
BA_ "GenSigTimeoutTime_MCPA" SG_ 2654486616 CBV_bit1_1E384058 0;
BA_ "GenSigTimeoutTime_MCPB" SG_ 2654486616 CBV_bit1_1E384058 0;
BA_ "GenSigTimeoutTime_MRGB" SG_ 2654486616 CBV_bit0_RepeatMessageRequestBit_1E384058 0;
BA_ "GenSigTimeoutTime_TCM" SG_ 2654486616 CBV_bit0_RepeatMessageRequestBit_1E384058 0;
BA_ "GenSigTimeoutTime_ECM" SG_ 2654486616 CBV_bit0_RepeatMessageRequestBit_1E384058 0;
BA_ "GenSigTimeoutTime_SGCP" SG_ 2654486616 CBV_bit0_RepeatMessageRequestBit_1E384058 0;
BA_ "GenSigTimeoutTime_AGSM" SG_ 2654486616 CBV_bit0_RepeatMessageRequestBit_1E384058 0;
BA_ "GenSigTimeoutTime_EVCU2" SG_ 2654486616 CBV_bit0_RepeatMessageRequestBit_1E384058 0;
BA_ "GenSigTimeoutTime_MCPA" SG_ 2654486616 CBV_bit0_RepeatMessageRequestBit_1E384058 0;
BA_ "GenSigTimeoutTime_MCPB" SG_ 2654486616 CBV_bit0_RepeatMessageRequestBit_1E384058 0;
BA_ "GenSigTimeoutTime_SGCP" SG_ 263 OptimdStrtReqdActr 0;
BA_ "GenSigTimeoutTime_AGSM" SG_ 263 OptimdStrtReqdActr 0;
BA_ "GenSigTimeoutTime_EVCU2" SG_ 263 OptimdStrtReqdActr 0;
BA_ "GenSigTimeoutTime_MCPA" SG_ 263 OptimdStrtReqdActr 0;
BA_ "GenSigTimeoutTime_MCPB" SG_ 263 OptimdStrtReqdActr 0;
BA_ "GenSigTimeoutTime_SGCP" SG_ 263 HCPFuelDisable 0;
BA_ "GenSigStartValue" SG_ 263 HCPFuelDisable 1;
BA_ "GenSigTimeoutTime_AGSM" SG_ 263 HCPFuelDisable 0;
BA_ "GenSigTimeoutTime_EVCU2" SG_ 263 HCPFuelDisable 0;
BA_ "GenSigTimeoutTime_MCPA" SG_ 263 HCPFuelDisable 0;
BA_ "GenSigTimeoutTime_MCPB" SG_ 263 HCPFuelDisable 0;
BA_ "GenSigTimeoutTime_SGCP" SG_ 263 Hyb_ProducingTorque 0;
BA_ "GenSigTimeoutTime_AGSM" SG_ 263 Hyb_ProducingTorque 0;
BA_ "GenSigTimeoutTime_EVCU2" SG_ 263 Hyb_ProducingTorque 0;
BA_ "GenSigTimeoutTime_MCPA" SG_ 263 Hyb_ProducingTorque 0;
BA_ "GenSigTimeoutTime_MCPB" SG_ 263 Hyb_ProducingTorque 0;
BA_ "GenSigTimeoutTime_SGCP" SG_ 263 OptimdEngOnOffCmd 0;
BA_ "GenSigTimeoutTime_AGSM" SG_ 263 OptimdEngOnOffCmd 0;
BA_ "GenSigTimeoutTime_EVCU2" SG_ 263 OptimdEngOnOffCmd 0;
BA_ "GenSigTimeoutTime_MCPA" SG_ 263 OptimdEngOnOffCmd 0;
BA_ "GenSigTimeoutTime_MCPB" SG_ 263 OptimdEngOnOffCmd 0;
BA_ "GenSigTimeoutTime_SGCP" SG_ 263 OptimdEngStrtStpType 0;
BA_ "GenSigTimeoutTime_AGSM" SG_ 263 OptimdEngStrtStpType 0;
BA_ "GenSigTimeoutTime_EVCU2" SG_ 263 OptimdEngStrtStpType 0;
BA_ "GenSigTimeoutTime_MCPA" SG_ 263 OptimdEngStrtStpType 0;
BA_ "GenSigTimeoutTime_MCPB" SG_ 263 OptimdEngStrtStpType 0;
BA_ "GenSigTimeoutTime_MRGB" SG_ 105 T7_Sensor_Temp 0;
BA_ "GenSigTimeoutTime_TCM" SG_ 105 T7_Sensor_Temp 0;
BA_ "GenSigTimeoutTime_ECM" SG_ 105 T7_Sensor_Temp 0;
BA_ "GenSigSendType" SG_ 105 T7_Sensor_Temp 3;
BA_ "GenSigTimeoutTime_AGSM" SG_ 105 T7_Sensor_Temp 0;
BA_ "GenSigTimeoutTime_EVCU2" SG_ 105 T7_Sensor_Temp 0;
BA_ "GenSigTimeoutTime_MRGB" SG_ 105 T4_Sensor_Temp 0;
BA_ "GenSigTimeoutTime_TCM" SG_ 105 T4_Sensor_Temp 0;
BA_ "GenSigTimeoutTime_ECM" SG_ 105 T4_Sensor_Temp 0;
BA_ "GenSigSendType" SG_ 105 T4_Sensor_Temp 3;
BA_ "GenSigTimeoutTime_AGSM" SG_ 105 T4_Sensor_Temp 0;
BA_ "GenSigTimeoutTime_EVCU2" SG_ 105 T4_Sensor_Temp 0;
BA_ "GenSigTimeoutTime_MRGB" SG_ 105 T7_CoolantTempVldty 0;
BA_ "GenSigTimeoutTime_TCM" SG_ 105 T7_CoolantTempVldty 0;
BA_ "GenSigTimeoutTime_ECM" SG_ 105 T7_CoolantTempVldty 0;
BA_ "GenSigSendType" SG_ 105 T7_CoolantTempVldty 3;
BA_ "GenSigTimeoutTime_AGSM" SG_ 105 T7_CoolantTempVldty 0;
BA_ "GenSigTimeoutTime_EVCU2" SG_ 105 T7_CoolantTempVldty 0;
BA_ "GenSigTimeoutTime_MRGB" SG_ 2654486617 CBV_bit3_NMCoordinatorBit_1E384059 0;
BA_ "GenSigTimeoutTime_TCM" SG_ 2654486617 CBV_bit3_NMCoordinatorBit_1E384059 0;
BA_ "GenSigTimeoutTime_ECM" SG_ 2654486617 CBV_bit3_NMCoordinatorBit_1E384059 0;
BA_ "GenSigTimeoutTime_SGCP" SG_ 2654486617 CBV_bit3_NMCoordinatorBit_1E384059 0;
BA_ "GenSigTimeoutTime_MRGB" SG_ 2654486617 CBV_bit2_1E384059 0;
BA_ "GenSigTimeoutTime_TCM" SG_ 2654486617 CBV_bit2_1E384059 0;
BA_ "GenSigTimeoutTime_ECM" SG_ 2654486617 CBV_bit2_1E384059 0;
BA_ "GenSigTimeoutTime_SGCP" SG_ 2654486617 CBV_bit2_1E384059 0;
BA_ "GenSigTimeoutTime_MRGB" SG_ 2654486617 CBV_bit1_1E384059 0;
BA_ "GenSigTimeoutTime_TCM" SG_ 2654486617 CBV_bit1_1E384059 0;
BA_ "GenSigTimeoutTime_ECM" SG_ 2654486617 CBV_bit1_1E384059 0;
BA_ "GenSigTimeoutTime_SGCP" SG_ 2654486617 CBV_bit1_1E384059 0;
BA_ "GenSigTimeoutTime_MRGB" SG_ 2654486617 CBV_bit0_RepeatMessageRequestBit_1E384059 0;
BA_ "GenSigTimeoutTime_TCM" SG_ 2654486617 CBV_bit0_RepeatMessageRequestBit_1E384059 0;
BA_ "GenSigTimeoutTime_ECM" SG_ 2654486617 CBV_bit0_RepeatMessageRequestBit_1E384059 0;
BA_ "GenSigTimeoutTime_SGCP" SG_ 2654486617 CBV_bit0_RepeatMessageRequestBit_1E384059 0;
BA_ "GenSigTimeoutTime_MRGB" SG_ 2654486617 CBV_bit5_1E384059 0;
BA_ "GenSigTimeoutTime_MRGB" SG_ 2654486617 CBV_bit4_ActiveWakeupBit_1E384059 0;
BA_ "GenSigTimeoutTime_TCM" SG_ 2654486617 CBV_bit4_ActiveWakeupBit_1E384059 0;
BA_ "GenSigTimeoutTime_ECM" SG_ 2654486617 CBV_bit4_ActiveWakeupBit_1E384059 0;
BA_ "GenSigTimeoutTime_SGCP" SG_ 2654486617 CBV_bit4_ActiveWakeupBit_1E384059 0;
BA_ "GenSigTimeoutTime_AGSM" SG_ 2654486617 CBV_bit4_ActiveWakeupBit_1E384059 0;
BA_ "GenSigTimeoutTime_EVCU2" SG_ 2654486617 CBV_bit4_ActiveWakeupBit_1E384059 0;
BA_ "GenSigTimeoutTime_MCPA" SG_ 2654486617 CBV_bit4_ActiveWakeupBit_1E384059 0;
BA_ "GenSigTimeoutTime_MCPB" SG_ 2654486617 CBV_bit4_ActiveWakeupBit_1E384059 0;
BA_ "GenSigTimeoutTime_TCM" SG_ 2654486617 CBV_bit5_1E384059 0;
BA_ "GenSigTimeoutTime_ECM" SG_ 2654486617 CBV_bit5_1E384059 0;
BA_ "GenSigTimeoutTime_SGCP" SG_ 2654486617 CBV_bit5_1E384059 0;
BA_ "GenSigTimeoutTime_AGSM" SG_ 2654486617 CBV_bit5_1E384059 0;
BA_ "GenSigTimeoutTime_EVCU2" SG_ 2654486617 CBV_bit5_1E384059 0;
BA_ "GenSigTimeoutTime_MCPA" SG_ 2654486617 CBV_bit5_1E384059 0;
BA_ "GenSigTimeoutTime_MCPB" SG_ 2654486617 CBV_bit5_1E384059 0;
BA_ "GenSigTimeoutTime_MRGB" SG_ 2654486617 CBV_bit7_1E384059 0;
BA_ "GenSigTimeoutTime_TCM" SG_ 2654486617 CBV_bit7_1E384059 0;
BA_ "GenSigTimeoutTime_ECM" SG_ 2654486617 CBV_bit7_1E384059 0;
BA_ "GenSigTimeoutTime_SGCP" SG_ 2654486617 CBV_bit7_1E384059 0;
BA_ "GenSigTimeoutTime_AGSM" SG_ 2654486617 CBV_bit7_1E384059 0;
BA_ "GenSigTimeoutTime_EVCU2" SG_ 2654486617 CBV_bit7_1E384059 0;
BA_ "GenSigTimeoutTime_MCPA" SG_ 2654486617 CBV_bit7_1E384059 0;
BA_ "GenSigTimeoutTime_MCPB" SG_ 2654486617 CBV_bit7_1E384059 0;
BA_ "GenSigTimeoutTime_MRGB" SG_ 2654486617 CBV_bit6_PartialNtwInfBit_1E384059 0;
BA_ "GenSigTimeoutTime_TCM" SG_ 2654486617 CBV_bit6_PartialNtwInfBit_1E384059 0;
BA_ "GenSigTimeoutTime_ECM" SG_ 2654486617 CBV_bit6_PartialNtwInfBit_1E384059 0;
BA_ "GenSigTimeoutTime_SGCP" SG_ 2654486617 CBV_bit6_PartialNtwInfBit_1E384059 0;
BA_ "GenSigTimeoutTime_AGSM" SG_ 2654486617 CBV_bit6_PartialNtwInfBit_1E384059 0;
BA_ "GenSigTimeoutTime_EVCU2" SG_ 2654486617 CBV_bit6_PartialNtwInfBit_1E384059 0;
BA_ "GenSigTimeoutTime_MCPA" SG_ 2654486617 CBV_bit6_PartialNtwInfBit_1E384059 0;
BA_ "GenSigTimeoutTime_MCPB" SG_ 2654486617 CBV_bit6_PartialNtwInfBit_1E384059 0;
BA_ "GenSigTimeoutTime_AGSM" SG_ 2654486617 CBV_bit0_RepeatMessageRequestBit_1E384059 0;
BA_ "GenSigTimeoutTime_EVCU2" SG_ 2654486617 CBV_bit0_RepeatMessageRequestBit_1E384059 0;
BA_ "GenSigTimeoutTime_MCPA" SG_ 2654486617 CBV_bit0_RepeatMessageRequestBit_1E384059 0;
BA_ "GenSigTimeoutTime_MCPB" SG_ 2654486617 CBV_bit0_RepeatMessageRequestBit_1E384059 0;
BA_ "GenSigTimeoutTime_MRGB" SG_ 2654486617 SourceNodeIdentifier_1E384059 0;
BA_ "GenSigTimeoutTime_TCM" SG_ 2654486617 SourceNodeIdentifier_1E384059 0;
BA_ "GenSigTimeoutTime_ECM" SG_ 2654486617 SourceNodeIdentifier_1E384059 0;
BA_ "GenSigTimeoutTime_SGCP" SG_ 2654486617 SourceNodeIdentifier_1E384059 0;
BA_ "GenSigTimeoutTime_AGSM" SG_ 2654486617 SourceNodeIdentifier_1E384059 0;
BA_ "GenSigTimeoutTime_EVCU2" SG_ 2654486617 SourceNodeIdentifier_1E384059 0;
BA_ "GenSigTimeoutTime_MCPA" SG_ 2654486617 SourceNodeIdentifier_1E384059 0;
BA_ "GenSigTimeoutTime_MCPB" SG_ 2654486617 SourceNodeIdentifier_1E384059 0;
BA_ "GenSigTimeoutTime_AGSM" SG_ 2654486617 CBV_bit1_1E384059 0;
BA_ "GenSigTimeoutTime_EVCU2" SG_ 2654486617 CBV_bit1_1E384059 0;
BA_ "GenSigTimeoutTime_MCPA" SG_ 2654486617 CBV_bit1_1E384059 0;
BA_ "GenSigTimeoutTime_MCPB" SG_ 2654486617 CBV_bit1_1E384059 0;
BA_ "GenSigTimeoutTime_AGSM" SG_ 2654486617 CBV_bit2_1E384059 0;
BA_ "GenSigTimeoutTime_EVCU2" SG_ 2654486617 CBV_bit2_1E384059 0;
BA_ "GenSigTimeoutTime_MCPA" SG_ 2654486617 CBV_bit2_1E384059 0;
BA_ "GenSigTimeoutTime_MCPB" SG_ 2654486617 CBV_bit2_1E384059 0;
BA_ "GenSigTimeoutTime_AGSM" SG_ 2654486617 CBV_bit3_NMCoordinatorBit_1E384059 0;
BA_ "GenSigTimeoutTime_EVCU2" SG_ 2654486617 CBV_bit3_NMCoordinatorBit_1E384059 0;
BA_ "GenSigTimeoutTime_MCPA" SG_ 2654486617 CBV_bit3_NMCoordinatorBit_1E384059 0;
BA_ "GenSigTimeoutTime_MCPB" SG_ 2654486617 CBV_bit3_NMCoordinatorBit_1E384059 0;
BA_ "GenSigTimeoutTime_MRGB" SG_ 476 ShiftLever_PositionFlt 0;
BA_ "GenSigTimeoutTime_ECM" SG_ 476 ShiftLever_PositionFlt 0;
BA_ "GenSigTimeoutTime_AGSM" SG_ 476 ShiftLever_PositionFlt 0;
BA_ "GenSigTimeoutTime_EVCU2" SG_ 476 ShiftLever_PositionFlt 0;
BA_ "GenSigTimeoutTime_MCPA" SG_ 476 ShiftLever_PositionFlt 0;
BA_ "GenSigTimeoutTime_MCPB" SG_ 476 ShiftLever_PositionFlt 0;
BA_ "GenSigTimeoutTime_MRGB" SG_ 476 ShiftLeverPositionReq 0;
BA_ "GenSigTimeoutTime_ECM" SG_ 476 ShiftLeverPositionReq 0;
BA_ "GenSigTimeoutTime_SGCP" SG_ 476 ShiftLeverPositionReq 0;
BA_ "GenSigTimeoutTime_AGSM" SG_ 476 ShiftLeverPositionReq 0;
BA_ "GenSigSendType" SG_ 476 ShiftLeverPositionReq 3;
BA_ "GenSigTimeoutTime_MCPA" SG_ 476 ShiftLeverPositionReq 0;
BA_ "GenSigTimeoutTime_MRGB" SG_ 476 Low_Mode_Req 0;
BA_ "GenSigTimeoutTime_ECM" SG_ 476 Low_Mode_Req 0;
BA_ "GenSigSendType" SG_ 476 Low_Mode_Req 3;
BA_ "GenSigTimeoutTime_AGSM" SG_ 476 Low_Mode_Req 0;
BA_ "GenSigTimeoutTime_EVCU2" SG_ 476 Low_Mode_Req 0;
BA_ "GenSigTimeoutTime_MCPA" SG_ 476 Low_Mode_Req 0;
BA_ "GenSigTimeoutTime_MCPB" SG_ 476 Low_Mode_Req 0;
BA_ "GenSigTimeoutTime_MRGB" SG_ 258 CRC_BRAKE2 0;
BA_ "GenSigTimeoutTime_TCM" SG_ 258 CRC_BRAKE2 0;
BA_ "GenSigTimeoutTime_ECM" SG_ 258 CRC_BRAKE2 0;
BA_ "GenSigTimeoutTime_SGCP" SG_ 258 CRC_BRAKE2 0;
BA_ "GenSigTimeoutTime_AGSM" SG_ 258 CRC_BRAKE2 0;
BA_ "GenSigTimeoutTime_EVCU2" SG_ 258 CRC_BRAKE2 0;
BA_ "GenSigTimeoutTime_MRGB" SG_ 258 ABSActive 0;
BA_ "GenSigTimeoutTime_TCM" SG_ 258 ABSActive 0;
BA_ "GenSigTimeoutTime_ECM" SG_ 258 ABSActive 0;
BA_ "GenSigTimeoutTime_SGCP" SG_ 258 ABSActive 0;
BA_ "GenSigTimeoutTime_AGSM" SG_ 258 ABSActive 0;
BA_ "GenSigTimeoutTime_EVCU2" SG_ 258 ABSActive 0;
BA_ "GenSigTimeoutTime_ECM" SG_ 476 APCM_Stat 0;
BA_ "GenSigTimeoutTime_SGCP" SG_ 476 APCM_Stat 0;
BA_ "GenSigTimeoutTime_AGSM" SG_ 476 APCM_Stat 0;
BA_ "GenSigTimeoutTime_MCPA" SG_ 476 APCM_Stat 0;
BA_ "GenSigTimeoutTime_MCPB" SG_ 476 APCM_Stat 0;
BA_ "GenSigTimeoutTime_MRGB" SG_ 258 LongAccelerationFailSts_BSM 0;
BA_ "GenSigTimeoutTime_TCM" SG_ 258 LongAccelerationFailSts_BSM 0;
BA_ "GenSigTimeoutTime_ECM" SG_ 258 LongAccelerationFailSts_BSM 0;
BA_ "GenSigTimeoutTime_SGCP" SG_ 258 LongAccelerationFailSts_BSM 0;
BA_ "GenSigTimeoutTime_AGSM" SG_ 258 LongAccelerationFailSts_BSM 0;
BA_ "GenSigTimeoutTime_EVCU2" SG_ 258 LongAccelerationFailSts_BSM 0;
BA_ "GenSigTimeoutTime_MRGB" SG_ 258 MessageCounter_BRAKE2 0;
BA_ "GenSigTimeoutTime_TCM" SG_ 258 MessageCounter_BRAKE2 0;
BA_ "GenSigTimeoutTime_ECM" SG_ 258 MessageCounter_BRAKE2 0;
BA_ "GenSigTimeoutTime_SGCP" SG_ 258 MessageCounter_BRAKE2 0;
BA_ "GenSigTimeoutTime_AGSM" SG_ 258 MessageCounter_BRAKE2 0;
BA_ "GenSigTimeoutTime_EVCU2" SG_ 258 MessageCounter_BRAKE2 0;
BA_ "GenSigTimeoutTime_MRGB" SG_ 258 ESCActive 0;
BA_ "GenSigTimeoutTime_TCM" SG_ 258 ESCActive 0;
BA_ "GenSigTimeoutTime_ECM" SG_ 258 ESCActive 0;
BA_ "GenSigTimeoutTime_SGCP" SG_ 258 ESCActive 0;
BA_ "GenSigTimeoutTime_AGSM" SG_ 258 ESCActive 0;
BA_ "GenSigTimeoutTime_EVCU2" SG_ 258 ESCActive 0;
BA_ "GenSigTimeoutTime_MRGB" SG_ 258 LatAcceleration_BSM 0;
BA_ "GenSigTimeoutTime_TCM" SG_ 258 LatAcceleration_BSM 0;
BA_ "GenSigTimeoutTime_ECM" SG_ 258 LatAcceleration_BSM 0;
BA_ "GenSigTimeoutTime_SGCP" SG_ 258 LatAcceleration_BSM 0;
BA_ "GenSigStartValue" SG_ 258 LatAcceleration_BSM 4095;
BA_ "GenSigTimeoutTime_AGSM" SG_ 258 LatAcceleration_BSM 0;
BA_ "GenSigTimeoutTime_EVCU2" SG_ 258 LatAcceleration_BSM 0;
BA_ "GenSigTimeoutTime_MRGB" SG_ 258 LatAccelerationFailSts_BSM 0;
BA_ "GenSigTimeoutTime_TCM" SG_ 258 LatAccelerationFailSts_BSM 0;
BA_ "GenSigTimeoutTime_ECM" SG_ 258 LatAccelerationFailSts_BSM 0;
BA_ "GenSigTimeoutTime_SGCP" SG_ 258 LatAccelerationFailSts_BSM 0;
BA_ "GenSigTimeoutTime_AGSM" SG_ 258 LatAccelerationFailSts_BSM 0;
BA_ "GenSigTimeoutTime_EVCU2" SG_ 258 LatAccelerationFailSts_BSM 0;
BA_ "GenSigTimeoutTime_MRGB" SG_ 258 LongAcceleration_BSM 0;
BA_ "GenSigTimeoutTime_TCM" SG_ 258 LongAcceleration_BSM 0;
BA_ "GenSigTimeoutTime_ECM" SG_ 258 LongAcceleration_BSM 0;
BA_ "GenSigTimeoutTime_SGCP" SG_ 258 LongAcceleration_BSM 0;
BA_ "GenSigStartValue" SG_ 258 LongAcceleration_BSM 4095;
BA_ "GenSigTimeoutTime_AGSM" SG_ 258 LongAcceleration_BSM 0;
BA_ "GenSigTimeoutTime_EVCU2" SG_ 258 LongAcceleration_BSM 0;
BA_ "GenSigTimeoutTime_MRGB" SG_ 476 CRC_AGSM2 0;
BA_ "GenSigTimeoutTime_ECM" SG_ 476 CRC_AGSM2 0;
BA_ "GenSigTimeoutTime_SGCP" SG_ 476 CRC_AGSM2 0;
BA_ "GenSigTimeoutTime_AGSM" SG_ 476 CRC_AGSM2 0;
BA_ "GenSigTimeoutTime_EVCU2" SG_ 476 CRC_AGSM2 0;
BA_ "GenSigTimeoutTime_MCPA" SG_ 476 CRC_AGSM2 0;
BA_ "GenSigTimeoutTime_MCPB" SG_ 476 CRC_AGSM2 0;
BA_ "GenSigTimeoutTime_MRGB" SG_ 476 MessageCounter_AGSM2 0;
BA_ "GenSigTimeoutTime_ECM" SG_ 476 MessageCounter_AGSM2 0;
BA_ "GenSigTimeoutTime_SGCP" SG_ 476 MessageCounter_AGSM2 0;
BA_ "GenSigTimeoutTime_AGSM" SG_ 476 MessageCounter_AGSM2 0;
BA_ "GenSigTimeoutTime_EVCU2" SG_ 476 MessageCounter_AGSM2 0;
BA_ "GenSigTimeoutTime_MCPA" SG_ 476 MessageCounter_AGSM2 0;
BA_ "GenSigTimeoutTime_MCPB" SG_ 476 MessageCounter_AGSM2 0;
BA_ "GenSigTimeoutTime_MRGB" SG_ 476 ShiftLockFailSts 0;
BA_ "GenSigTimeoutTime_ECM" SG_ 476 ShiftLockFailSts 0;
BA_ "GenSigTimeoutTime_EVCU2" SG_ 476 ShiftLockFailSts 0;
BA_ "GenSigTimeoutTime_MCPA" SG_ 476 ShiftLockFailSts 0;
BA_ "GenSigTimeoutTime_MCPB" SG_ 476 ShiftLockFailSts 0;
BA_ "GenSigTimeoutTime_MRGB" SG_ 476 PRNDdisplayFailSts 0;
BA_ "GenSigTimeoutTime_ECM" SG_ 476 PRNDdisplayFailSts 0;
BA_ "GenSigTimeoutTime_SGCP" SG_ 476 PRNDdisplayFailSts 0;
BA_ "GenSigTimeoutTime_AGSM" SG_ 476 PRNDdisplayFailSts 0;
BA_ "GenSigTimeoutTime_MCPA" SG_ 476 PRNDdisplayFailSts 0;
BA_ "GenSigTimeoutTime_MCPB" SG_ 476 PRNDdisplayFailSts 0;
BA_ "GenSigTimeoutTime_MRGB" SG_ 476 PRNDFailSts 0;
BA_ "GenSigTimeoutTime_ECM" SG_ 476 PRNDFailSts 0;
BA_ "GenSigTimeoutTime_SGCP" SG_ 476 PRNDFailSts 0;
BA_ "GenSigTimeoutTime_AGSM" SG_ 476 PRNDFailSts 0;
BA_ "GenSigTimeoutTime_MCPA" SG_ 476 PRNDFailSts 0;
BA_ "GenSigTimeoutTime_MCPB" SG_ 476 PRNDFailSts 0;
VAL_ 476 ShiftLockFailSts 0 "Fail_not_Present" 1 "Fail_Present";
VAL_ 476 PRNDFailSts 0 "Fail_Not_Present" 1 "Fail_Present";
VAL_ 476 PRNDdisplayFailSts 0 "Fail_not_present" 1 "Fail_present";
VAL_ 271 Sum_FW_ID_Slw 31 "SNA";
VAL_ 271 Sum_FW_ID_Fst 31 "SNA";
VAL_ 271 MinPrdtdEngRunTorqCapV 0 "Valid" 1 "Not_Valid";
VAL_ 271 MinPrdtdEngRunTorqCap 4095 "SNA";
VAL_ 271 MinImmedEngTorqCapV 0 "Valid" 1 "Not_Valid";
VAL_ 271 MinImmedEngTorqCap 4095 "SNA";
VAL_ 271 MinEngTorqCapV 0 "Valid" 1 "Not_Valid";
VAL_ 271 MinEngTorqCap 4095 "SNA";
VAL_ 271 MinAirFlowMinSparkTorqCap 4095 "SNA";
VAL_ 271 MaxPrdtdEngTorqCapV 0 "Valid" 1 "Not_Valid";
VAL_ 271 MaxPrdtdEngTorqCap 4095 "SNA";
VAL_ 271 MaxOffEngTorqCap 4095 "SNA";
VAL_ 271 HybActEngTorqRespTyp 0 "Inactive" 1 "Pleasability_Limited" 2 "Maximum_Range";
VAL_ 271 ETRQ_Mode 7 "SNA";
VAL_ 271 EngTrqReserveReq 255 "SNA";
VAL_ 271 EngAirFlwStdyStTorqV 0 "Valid" 1 "Not_Valid";
VAL_ 271 EngAirFlwStdyStTorq 4095 "SNA";
VAL_ 271 EngActuatorsStat 0 "ACPP" 1 "SCPP" 2 "ACPA";
VAL_ 271 EngActStdyStTorqV 0 "Valid" 1 "Not_Valid";
VAL_ 271 EngActStdyStTorq 4095 "SNA";
VAL_ 262 TxAC_EMCC_rq_W 0 "False" 1 "True";
VAL_ 262 TRANS_CLU_SLIP_MODE_W 0 "NORMAL" 1 "MDS_RQ" 2 "IDFSO_RQ" 3 "AC_EN_DIS_RQ" 4 "IDFSO_ACTIVE" 5 "MDS_IDFSO_ACT" 7 "SNA";
VAL_ 262 LV12PwrFreeRq_W 0 "Level 1 or 2 Power free Mode NOT active" 1 "Level 1 or 2 Power free Mode Active";
VAL_ 262 KickDownRequest_W 0 "No_kd_request" 1 "Kd_request";
VAL_ 262 IntakeAirTemperature_W 255 "SNA";
VAL_ 262 GasPedalPositionFailSts_W 0 "Fail_not_present" 1 "Fail_present";
VAL_ 262 GasPedalPosition_W 255 "SNA";
VAL_ 262 ESS_ENG_ST_W 1 "ENS Stopped / ENS_STOPPED" 2 "ENS Request Start / ENS_RQ_ST" 3 "ENS Running / ENS_RUN" 4 "ENS Stop Pending / ENS_STOP_PEND" 5 "ENS Start protection / ENS_ST_PRTCT" 6 "ENS Start inhibit / ENS_ST_INH" 7 "ENS disabled / ENS_DSBL" 8 "ENS_IHB_LATCH" 9 "ENS Starting / ENS_Starting" 15 "SNA";
VAL_ 262 EngTrq_Enbl_Rq_TCM_W 0 "Not_Active" 1 "Active";
VAL_ 262 EngineSts_W 0 "Engine_Off" 1 "Engine_Cranking" 2 "Engine_On" 3 "SNA";
VAL_ 262 EngineSpeedFailSts_W 0 "Fail_not_present" 1 "Fail_present";
VAL_ 262 EngineSpeed_W 16383 "SNA";
VAL_ 262 EngineIdleRefSpeed 4095 "SNA";
VAL_ 262 EngineFrictionTorque_W 511 "SNA";
VAL_ 262 ECM_LHOM_W 0 "Not_In_Limp_Home" 1 "In_Limp_Home";
VAL_ 262 ECM_LHOM_Trans_W 0 "Limp Home not Active" 1 "No Redundant Torque Req" 2 "Precise Torque +/-15%" 3 "Imprecise Torque";
VAL_ 262 CrankHold_W 0 "Not_Active" 1 "Active";
VAL_ 258 LongAccelerationFailSts_BSM 0 "Fail_Not_Present" 1 "Fail_Present";
VAL_ 258 LongAcceleration_BSM 4095 "SNA";
VAL_ 258 LatAccelerationFailSts_BSM 0 "Fail_Not_Present" 1 "Fail_Present";
VAL_ 258 LatAcceleration_BSM 4095 "SNA";
VAL_ 258 ESCActive 0 "Not_active" 1 "Active";
VAL_ 258 ABSActive 0 "Not_active" 1 "Active";
VAL_ 476 APCM_Stat 0 "OFF" 1 "ON" 2 "PENDING" 3 "SNA";
VAL_ 262 ESS_EBOOST_BRKHLD_STATUS 0 "Default_Hold_BSM" 1 "ImmediateRelease" 2 "PositiveGradeTorqueBlending" 3 "NegativeGradeTorqueBlending" 7 "SNA";
VAL_ 262 Engine_Stall_Detected 0 "No_Stall_Detected" 1 "Stall_Detected";
VAL_ 105 T7_CoolantTempVldty 0 "Valid" 1 "Not_Valid";
VAL_ 271 MAP_4_BAR_PHEV 511 "SNA";
VAL_ 2654486617 CBV_bit3_NMCoordinatorBit_1E384059 0 "Start of synchronized shutdown is not requested by main coordinator" 1 "Start of synchronized shutdown is requested by main coordinator";
VAL_ 2654486617 CBV_bit4_ActiveWakeupBit_1E384059 0 "PassiveWakeup" 1 "ActiveWakeup";
VAL_ 2654486617 CBV_bit6_PartialNtwInfBit_1E384059 0 "NM PDU contains no Partial Network request information" 1 "NM PDU contains Partial Network request information";
VAL_ 2654486617 CBV_bit0_RepeatMessageRequestBit_1E384059 0 "Repeat Message State not requested" 1 "Repeat Message State requested";
VAL_ 2654486616 CBV_bit0_RepeatMessageRequestBit_1E384058 0 "Repeat Message State not requested" 1 "Repeat Message State requested";
VAL_ 2654486616 CBV_bit3_NMCoordinatorBit_1E384058 0 "Start of synchronized shutdown is not requested by main coordinator" 1 "Start of synchronized shutdown is requested by main coordinator";
VAL_ 2654486616 CBV_bit4_ActiveWakeupBit_1E384058 0 "PassiveWakeup" 1 "ActiveWakeup";
VAL_ 2654486616 CBV_bit6_PartialNtwInfBit_1E384058 0 "NM PDU contains no Partial Network request information" 1 "NM PDU contains Partial Network request information";
VAL_ 476 ShiftLever_PositionFlt 0 "No Fault" 1 "Fault";
VAL_ 2654339273 GenericFailSts_FD16_SGCP 0 "No_Fail_Present" 1 "Fail_Present";
VAL_ 2654339273 EOL_FD16_SGCP 0 "No_EOL_Programming" 1 "EOL_Programming";
VAL_ 2654339273 CurrentFailSts_FD16_SGCP 0 "No_Fail_Present" 1 "Fail_Present";
VAL_ 2654339161 EOL_FD16_MCPB 0 "No_EOL_Programming" 1 "EOL_Programming";
VAL_ 2654339160 EOL_FD16_MCPA 0 "No_EOL_Programming" 1 "EOL_Programming";
VAL_ 263 OptimdStrtReqdActr 0 "No_Action" 1 "P1f" 2 "P1r" 3 "Starter_12V" 4 "P2" 7 "SNA";
VAL_ 263 OptimdEngStrtStpType 0 "No_Action" 1 "Hybrid_Torque_Start" 2 "Engine_Torque_Start" 3 "Low_Power_Start" 4 "Generic_Torque_Start" 5 "Smooth_AutoStart" 6 "Normal_AutoStart" 7 "Aggressive_Autostart" 8 "Generic_Autostart" 9 "Compression_Test" 10 "Green_Engine_Start" 11 "Controlled_Stop" 12 "Immediate_Stop" 13 "Reverse_Autostart" 14 "Clutch_Autostart" 15 "Imp_Autostart" 16 "EM_Autostart" 17 "EM_LowPower" 31 "SNA";
VAL_ 263 OptimdEngOnOffCmd 0 "Off_Command" 1 "On_Command";
VAL_ 263 Hyb_ProducingTorque 0 "Not_Producing_Torque" 1 "Producing_Torque";
VAL_ 263 HCPFuelDisable 0 "Do_Not_Disable_Fuel" 1 "Disable_Fuel";
VAL_ 262 EssEngStrtIsNotAllwdID 0 "EssReady" 1 "ESSActive" 2 "Inhibit" 3 "Disarm" 4 "Disable" 7 "SNA";
VAL_ 262 EssEngStrtIsNotAllwd 0 "Start_Allowed" 1 "Start_Not_Allowed";
VAL_ 262 EssEngStopIsNotAllwdID 0 "Engine_OverridableID" 1 "Engine_NotOverridableID" 2 "Aftertreatment_NotOverridableID" 3 "Burnoff_NotOverridableID" 4 "OBD_NotOverridableID" 5 "Sparkfoul_NotOverridableID" 6 "Hood_NotOverridableID" 7 "StaleFuel_NotOverridableID" 8 "Temperatures_NotOverridable" 9 "Occupant_NotOverridable" 15 "SNA";
VAL_ 262 EssEngStopIsNotAllwd 0 "Stop_Allowed" 1 "Stop_Not_Allowed";
VAL_ 262 EssEngSt 0 "Stopped" 1 "Starting" 2 "Running" 3 "Spinning" 4 "Stopping" 5 "Reversing" 6 "Not_Used" 7 "SNA";
VAL_ 262 EssEngModReq 0 "Do_Nothing" 1 "Prepare_for_Start" 2 "Start" 3 "Prepare_for_Stop" 4 "Stop" 7 "SNA";
VAL_ 262 CompressionTest 0 "CompressionTest_NotActive" 1 "CompressionTest_Active";
VAL_ 263 PowertrainPrplsnActv_PT 0 "Not_Active" 1 "Active";
VAL_ 263 GearEngagedForDisplay_PT 0 "Initialize" 1 "Gear_1st" 2 "Gear_2nd" 3 "Gear_3rd" 4 "Gear_4th" 5 "Gear_5th" 6 "Gear_6th" 7 "Gear_7th" 8 "Gear_8th" 9 "Gear_9th" 12 "Park" 13 "Neutral" 14 "Reverse" 15 "Drive" 16 "Low" 17 "Manual" 18 "Sport_Mode" 31 "SNA";
VAL_ 263 GearEngaged_PT 0 "Neutral" 1 "ForwardGear_1" 2 "ForwardGear_2" 3 "ForwardGear_3" 4 "ForwardGear_4" 5 "ForwardGear_5" 6 "ForwardGear_6" 7 "ForwardGear_7" 8 "ForwardGear_8" 9 "ForwardGear_9" 13 "Parking" 14 "ReverseGear" 15 "SNA";
VAL_ 2654339161 GenericFailSts_FD16_MCPB 0 "No_Fail_Present" 1 "Fail_Present";
VAL_ 2654339161 CurrentFailSts_FD16_MCPB 0 "No_Fail_Present" 1 "Fail_Present";
VAL_ 2654339160 GenericFailSts_FD16_MCPA 0 "No_Fail_Present" 1 "Fail_Present";
VAL_ 2654339160 CurrentFailSts_FD16_MCPA 0 "No_Fail_Present" 1 "Fail_Present";
VAL_ 496 Plock_fdbk_sts 0 "Init" 1 "Engaging" 2 "Engaged" 3 "Disengaging" 4 "Disengaged" 5 "Fault" 7 "SNA";
VAL_ 271 RedSpkAuthorityAvbl 0 "Not_Available" 1 "Available";
VAL_ 271 EngMinSparkNomCurrAirTorqCap 2047 "SNA";
VAL_ 263 TransmissionFailSts_PT 0 "Fail_not_present" 1 "Fail_present";
VAL_ 263 TerrainModeStat_PT 0 "Auto" 1 "Auto_Fault" 2 "Rock" 3 "Track" 4 "Snow" 5 "Offroad" 6 "Eco" 7 "Corsa" 8 "Sport" 9 "Mud_Sand" 10 "Mud" 11 "Sand" 12 "Valet" 13 "Custom" 14 "Tow" 15 "DRAG" 16 "BAJA" 18 "Drift" 19 "Donut" 31 "SNA";
VAL_ 263 ShiftLeverPosition_PT 0 "No_Selection_Active_Or_Available" 1 "Park" 2 "Reverse" 3 "Neutral" 4 "Drive" 5 "Low" 6 "TIP_Autostick" 7 "Plus" 8 "Minus" 9 "Sport" 15 "SNA";
VAL_ 263 ShiftLeverLockReq_PT 0 "Not_Active" 1 "Active";
VAL_ 263 R_SHFT_LOCK_PT 0 "Unlocked" 1 "Locked";
VAL_ 263 GearIndicationSts_PT 0 "Normal" 1 "Blinking";
VAL_ 263 GasPedalPositionFailSts_PT 0 "Fail_not_present" 1 "Fail_present";
VAL_ 263 GasPedalPosition_PT 255 "SNA";
VAL_ 263 APCM_Rq_PT 0 "OFF" 1 "ON" 2 "Pending" 3 "SNA";
VAL_ 271 EngTrqFSO_CurrAir 4095 "SNA";
VAL_ 2654486592 CBV_bit4_ActiveWakeupBit_1E384040 0 "PassiveWakeup" 1 "ActiveWakeup";
VAL_ 2654486729 CBV_bit0_RepeatMessageRequestBit_1E3840C9 0 "Repeat_Message_State_not_requested" 1 "Repeat_Message_State_requested";
VAL_ 2654486729 CBV_bit3_NMCoordinatorBit_1E3840C9 0 "Start_of_synchronized_shutdown_is_not_requested_by_main_coordinator" 1 "Start_of_synchronized_shutdown_is_requested_by_main_coordinator";
VAL_ 2654486729 CBV_bit4_ActiveWakeupBit_1E3840C9 0 "PassiveWakeup" 1 "ActiveWakeup";
VAL_ 2654486729 CBV_bit6_PartialNtwInfBit_1E3840C9 0 "NM_PDU_contains_no_Partial_Network_request_information" 1 "NM_PDU_contains_Partial_Network_request_information";
VAL_ 1811 Real_Time_Validity 0 "Valid" 1 "Not_Valid";
VAL_ 1811 Real_Time_Clock 4294967295 "SNA";
VAL_ 476 Low_Mode_Req 0 "Not_Pressed" 1 "Pressed";
VAL_ 476 ShiftLeverPositionReq 0 "No_Selection_Active_Or_Available" 1 "P" 2 "R" 3 "N" 4 "D" 5 "L" 6 "TIP_Autostick" 7 "Plus" 8 "Minus" 9 "Sport" 10 "Not_Used" 11 "Not_Used" 12 "Not_Used" 13 "Not_Used" 14 "Not_Used" 15 "SNA";
VAL_ 1070 SGCP_DTC_Stat2 0 "Not_Supported" 1 "Critically_disabled" 2 "No_status_to_report" 3 "Diagnostic_passed" 4 "Diagnostic_failed" 5 "Reset_DTC_status" 7 "SNA";
VAL_ 1070 SGCP_DTC_Stat1 0 "Not_Supported" 1 "Critically_disabled" 2 "No_status_to_report" 3 "Diagnostic_passed" 4 "Diagnostic_failed" 5 "Reset_DTC_status" 7 "SNA";
VAL_ 1070 SGCP_DTC_Idx2 31 "SNA";
VAL_ 1070 SGCP_DTC_Idx1 31 "SNA";
VAL_ 1070 SGCP_CalChar 255 "SNA";
VAL_ 1070 SGCP_Cal_ID_Idx 63 "SNA";
VAL_ 1065 MCPB_DTC_Stat2 0 "Not_Supported" 1 "Critically_disabled" 2 "No_status_to_report" 3 "Diagnostic_passed" 4 "Diagnostic_failed" 5 "Reset_DTC_status" 7 "SNA";
VAL_ 1065 MCPB_DTC_Stat1 0 "Not_Supported" 1 "Critically_disabled" 2 "No_status_to_report" 3 "Diagnostic_passed" 4 "Diagnostic_failed" 5 "Reset_DTC_status" 7 "SNA";
VAL_ 1065 MCPB_DTC_Idx2 31 "SNA";
VAL_ 1065 MCPB_DTC_Idx1 31 "SNA";
VAL_ 1065 MCPB_CalChar 255 "SNA";
VAL_ 1065 MCPB_Cal_ID_Idx 63 "SNA";
VAL_ 1057 MCPA_DTC_Stat2 0 "Not_Supported" 1 "Critically_disabled" 2 "No_status_to_report" 3 "Diagnostic_passed" 4 "Diagnostic_failed" 5 "Reset_DTC_status" 7 "SNA";
VAL_ 1057 MCPA_DTC_Stat1 0 "Not_Supported" 1 "Critically_disabled" 2 "No_status_to_report" 3 "Diagnostic_passed" 4 "Diagnostic_failed" 5 "Reset_DTC_status" 7 "SNA";
VAL_ 1057 MCPA_DTC_Idx2 31 "SNA";
VAL_ 1057 MCPA_DTC_Idx1 31 "SNA";
VAL_ 1057 MCPA_CalChar 255 "SNA";
VAL_ 1057 MCPA_Cal_ID_Idx 63 "SNA";
VAL_ 263 PropulsionSystemActive_PT 0 "NOT_ACTIVE" 1 "ACTIVE";
VAL_ 286 RELSD_TgtTrq 511 "SNA";
VAL_ 263 Custom_DrvMdSts_PT 0 "NP" 1 "STREET" 2 "VALET" 3 "SPORT" 4 "S_PLUS" 5 "TRACK" 6 "ECO" 7 "SNOW" 8 "ROCK" 9 "TOW" 10 "DRAG" 11 "MUD" 12 "SAND" 13 "BAJA" 14 "OFFROAD" 31 "SNA";
VAL_ 263 WheelSpeedRearRight 8191 "SNA";
VAL_ 263 WheelSpeedRearLeft 8191 "SNA";
VAL_ 263 Transm_Torq_Feedback 0 "Not_Active" 1 "Active";
VAL_ 263 Inertia_Torque_Active 0 "Not_Active" 1 "Active";
VAL_ 263 Gear_Rq 0 "N" 1 "D1" 2 "D2" 7 "SNA";
VAL_ 263 EM_min_Trqdyn_P 1022 "Initialization" 1023 "SNA";
VAL_ 263 EM_max_Trqdyn_P 1022 "Initialization" 1023 "SNA";
VAL_ 262 MinEngPowerReqForOilDil 255 "SNA";
VAL_ 262 MinEngPowerReqForOilDilEnabler 0 "False" 1 "True";
VAL_ 271 GasFlwEnblsFuAtStr 0 "False" 1 "True";
VAL_ 263 EOPB_Min_Oil_FlwRate_Rq 255 "SNA";
SIG_GROUP_ 258 BRAKE_FD_2_Pkt 1 : MessageCounter_BRAKE2 LongAccelerationFailSts_BSM LongAcceleration_BSM LatAccelerationFailSts_BSM LatAcceleration_BSM ESCActive CRC_BRAKE2 ABSActive;
SIG_GROUP_ 271 ENGINE_HYBD_FD_1_Pkt 1 : Sum_FW_ID_Slw Sum_FW_ID_Fst MinPrdtdEngRunTorqCapV MinPrdtdEngRunTorqCap MinImmedEngTorqCapV MinImmedEngTorqCap MinEngTorqCapV MinEngTorqCap MinAirFlowMinSparkTorqCapV MinAirFlowMinSparkTorqCap MessageCounter_ENGINE_HYBD_FD_1 MaxPrdtdEngTorqCapV MaxPrdtdEngTorqCap MaxOffEngTorqCap HybActEngTorqRespTyp Feedback_HCP ETRQ_Mode EngTrqReserveReq EngRunCrnkAct EngAirFlwStdyStTorqV EngAirFlwStdyStTorq EngActuatorsStat EngActStdyStTorqV EngActStdyStTorq CRC_ENGINE_HYBD_FD_1 MAP_4_BAR_PHEV RedSpkAuthorityAvbl EngMinSparkNomCurrAirTorqCap EngTrqFSO_CurrAir GasFlwEnblsFuAtStr;
SIG_GROUP_ 262 ENGINE_FD_2_Pkt 1 : TxAC_EMCC_rq_W TRANS_CLU_SLIP_MODE_W MessageCounter_ENGINE2 LV12PwrFreeRq_W KickDownRequest_W IntakeAirTemperature_W GasPedalPositionFailSts_W GasPedalPosition_W ESS_RqShftPark_W ESS_ENG_ST_W EngTrq_Enbl_Rq_TCM_W EngineSts_W EngineSpeedFailSts_W EngineSpeed_W EngineIdleRefSpeed EngineFrictionTorque_W ECM_LHOM_W ECM_LHOM_Trans_W CRC_ENGINE2 CrankHold_W ESS_EBOOST_BRKHLD_STATUS Engine_Stall_Detected EssEngStrtIsNotAllwdID EssEngStrtIsNotAllwd EssEngStopIsNotAllwdID EssEngStopIsNotAllwd EssEngSt EssEngModReq CompressionTest MinEngPowerReqForOilDil MinEngPowerReqForOilDilEnabler Torque_Interface_Mask;
SIG_GROUP_ 476 AGSM_FD_2_Pkt 1 : ShiftLockFailSts PRNDFailSts PRNDdisplayFailSts MessageCounter_AGSM2 CRC_AGSM2 APCM_Stat ShiftLever_PositionFlt Low_Mode_Req ShiftLeverPositionReq;
SIG_GROUP_ 496 PARK_DATA_Pkt 1 : MessageCounter_PARK_DATA CRC_PARK_DATA Plock_fdbk_sts;
SIG_GROUP_ 263 PT_SYSTEM_FD_1_Pkt 1 : OptimdStrtReqdActr OptimdEngStrtStpType OptimdEngOnOffCmd Hyb_ProducingTorque HCPFuelDisable PowertrainPrplsnActv_PT GearEngagedForDisplay_PT GearEngaged_PT TransmissionFailSts_PT TerrainModeStat_PT ShiftLeverPosition_PT ShiftLeverLockReq_PT R_SHFT_LOCK_PT MessageCounter_PT_SYSTEM_FD_1 GearIndicationSts_PT GasPedalPositionFailSts_PT GasPedalPosition_PT CRC_PT_SYSTEM_FD_1 APCM_Rq_PT PropulsionSystemActive_PT Custom_DrvMdSts_PT WheelSpeedRearRight WheelSpeedRearLeft Transm_Torq_Feedback Inertia_Torque_Active Gear_Rq EM_min_Trqdyn_P EM_max_Trqdyn_P EOPB_Min_Oil_FlwRate_Rq;
SIG_GROUP_ 216 PT_ENERGY_FD_1_Pkt 1 : BatteryVoltage_Raw_PT;
SIG_GROUP_ 1070 SGCP_OBD_DTC_Pkt 1 : SGCP_DTC_Stat2 SGCP_DTC_Stat1 SGCP_DTC_Idx2 SGCP_DTC_Idx1 SGCP_CalChar SGCP_Cal_ID_Idx MessageCounter_SGCP_OBD_DTC CRC_SGCP_OBD_DTC;
SIG_GROUP_ 1065 MCPB_OBD_DTC_Pkt 1 : MessageCounter_MCPB_OBD_DTC MCPB_DTC_Stat2 MCPB_DTC_Stat1 MCPB_DTC_Idx2 MCPB_DTC_Idx1 MCPB_CalChar MCPB_Cal_ID_Idx CRC_MCPB_OBD_DTC;
SIG_GROUP_ 1057 MCPA_OBD_DTC_Pkt 1 : MessageCounter_MCPA_OBD_DTC MCPA_DTC_Stat2 MCPA_DTC_Stat1 MCPA_DTC_Idx2 MCPA_DTC_Idx1 MCPA_CalChar MCPA_Cal_ID_Idx CRC_MCPA_OBD_DTC;
